VERSION ""

NS_ :

BS_:

BU_:BMS FCS VCU
BO_ 2550464563 BatP3_BMS_PackUsageLimit: 8 BMS
 SG_ P3_PackVltUprLmt : 7|14@0+ (0.1,0) [0|1200] "V" VCU
 SG_ P3_PackVltLoLmt : 9|14@0+ (0.1,0) [0|1200] "V" VCU
 SG_ P3_PackMaxDschrgCrnt : 27|14@0+ (0.1,0) [0|1600] "A" VCU
 SG_ P3_PackMaxChrgCrnt : 45|14@0+ (0.1,0) [0|1600] "A" VCU

BO_ 2550530099 BatP3_BMS_PackPowerCapability: 8 BMS
 SG_ P3_PackDschrgPwrLmt : 7|10@0+ (1,0) [0|1000] "kW" VCU
 SG_ P3_PackDschrgPwrStat : 13|2@0+ (1,0) [0|3] "" VCU
 SG_ P3_PackChrgPwrLmt : 11|10@0+ (1,0) [0|1000] "kW" VCU
 SG_ P3_PackChrgPwrStat : 17|2@0+ (1,0) [0|3] "" VCU

BO_ 2550595635 BatP3_BMS_ChargingInfo: 8 BMS
 SG_ P3_ChrgrCplrStat : 7|1@0+ (1,0) [0|1] "" VCU
 SG_ P3_HVBattChrgSysStatus : 6|4@0+ (1,0) [0|15] "" VCU
 SG_ P3_DCChrgCrntCmd : 2|9@0+ (1,0) [0|500] "A" VCU
 SG_ P3_CC2Vlt : 9|8@0+ (0.1,0) [0|25] "V" VCU
 SG_ P3_DCRcptPosTemp : 17|9@0+ (0.5,-40) [-40|150] "C" VCU
 SG_ P3_DCRcptNegTemp : 24|9@0+ (0.5,-40) [-40|150] "C" VCU
 SG_ P3_Tm2FullChrg : 47|14@0+ (1,0) [0|65535] "min" VCU

BO_ 2550661171 BatP3_BMS_ThermalManagement: 8 BMS
 SG_ P3_Inlet1ClntTemp : 7|11@0+ (0.1,-40) [-40|150] "C" VCU
 SG_ P3_Inlet2ClntTemp : 12|11@0+ (0.1,-40) [-40|150] "C" VCU
 SG_ P3_Outlet1ClntTemp : 17|11@0+ (0.1,-40) [-40|150] "C" VCU
 SG_ P3_Outlet2ClntTemp : 38|11@0+ (0.1,-40) [-40|150] "C" VCU
 SG_ P3_TrgtClntTemp : 43|11@0+ (0.1,-40) [-40|150] "C" VCU
 SG_ P3_TrgtClntFlowRate : 48|9@0+ (0.2,0) [0|100] "C" VCU

BO_ 2550726707 BatP3_BMS_CellVoltMaxMin: 8 BMS
 SG_ P3_MaxCellVlt : 7|13@0+ (0.001,0) [0|5] "V" VCU
 SG_ P3_MaxCellVltNum : 10|9@0+ (1,0) [0|500] "" VCU
 SG_ P3_MinCellVlt : 17|13@0+ (0.001,0) [0|5] "V" VCU
 SG_ P3_MinCellVltNum : 36|9@0+ (1,0) [0|500] "" VCU
 SG_ P3_AvgCellVlt : 43|13@0+ (0.001,0) [0|5] "V" VCU

BO_ 2550792243 BatP3_BMS_CellTempMaxMin: 8 BMS
 SG_ P3_MaxCellTemp : 7|11@0+ (0.1,-40) [-40|150] "C" VCU
 SG_ P3_MaxCellTempNum : 12|9@0+ (1,0) [0|500] "" VCU
 SG_ P3_MinCellTemp : 19|11@0+ (0.1,-40) [-40|150] "C" VCU
 SG_ P3_MinCellTempNum : 24|9@0+ (1,0) [0|500] "" VCU
 SG_ P3_AvgCellTemp : 47|11@0+ (0.1,-40) [-40|150] "C" VCU

BO_ 2550857779 BatP3_BMS_PackFaultInfo1: 8 BMS
 SG_ P3_PackTotFltNum : 7|8@0+ (1,0) [0|200] "" VCU
 SG_ P3_CellOverVoltage : 15|2@0+ (1,0) [0|3] "" VCU
 SG_ P3_CellUnderVoltage : 13|2@0+ (1,0) [0|3] "" VCU
 SG_ P3_CellVoltageDiffHi : 11|1@0+ (1,0) [0|1] "" VCU
 SG_ P3_PackOverVoltage : 10|2@0+ (1,0) [0|3] "" VCU
 SG_ P3_PackUnderVoltage : 8|2@0+ (1,0) [0|3] "" VCU
 SG_ P3_CellOverTemp : 22|2@0+ (1,0) [0|3] "" VCU
 SG_ P3_CellTempLow : 20|1@0+ (1,0) [0|1] "" VCU
 SG_ P3_CellTempDiffHi : 19|1@0+ (1,0) [0|1] "" VCU
 SG_ P3_PackDschrgCrntHi : 18|2@0+ (1,0) [0|3] "" VCU
 SG_ P3_PackChrgCrntHi : 16|2@0+ (1,0) [0|3] "" VCU
 SG_ P3_PackCrnSnsr1OffsetHi : 30|1@0+ (1,0) [0|1] "" VCU
 SG_ P3_HVIsolFlt : 29|2@0+ (1,0) [0|3] "" VCU
 SG_ P3_HVILFlt : 27|1@0+ (1,0) [0|1] "" VCU
 SG_ P3_ThrmlRunaway : 26|1@0+ (1,0) [0|1] "" VCU
 SG_ P3_CellVoltInvalid : 25|1@0+ (1,0) [0|1] "" VCU
 SG_ P3_CellTempInvalid : 24|1@0+ (1,0) [0|1] "" VCU
 SG_ P3_DaisyChainComFlt : 39|1@0+ (1,0) [0|1] "" VCU
 SG_ P3_PackVoltRatFlt : 38|1@0+ (1,0) [0|1] "" VCU
 SG_ P3_CrntSnsr1Invalid : 37|1@0+ (1,0) [0|1] "" VCU
 SG_ P3_CrntSnsr1OOR : 36|1@0+ (1,0) [0|1] "" VCU
 SG_ P3_CrntSnsr2Invalid : 35|1@0+ (1,0) [0|1] "" VCU
 SG_ P3_CrntSnsr2OOR : 34|1@0+ (1,0) [0|1] "" VCU
 SG_ P3_PackCrnSnsr2OffsetHi : 33|1@0+ (1,0) [0|1] "" VCU
 SG_ P3_OutofEnergy : 32|1@0+ (1,0) [0|1] "" VCU
 SG_ P3_IsolDetCircErr : 47|1@0+ (1,0) [0|1] "" VCU
 SG_ P3_HVILCircShortToGND : 46|1@0+ (1,0) [0|1] "" VCU
 SG_ P3_HVILCircShortToPwr : 45|1@0+ (1,0) [0|1] "" VCU

BO_ 2550923315 BatP3_BMS_PackFaultInfo2: 8 BMS
 SG_ P3_MainPosCntctrStkClsd : 7|1@0+ (1,0) [0|1] "" VCU
 SG_ P3_MainPosCntctrStkOpn : 6|1@0+ (1,0) [0|1] "" VCU
 SG_ P3_MainNegCntctr1StkClsd : 5|1@0+ (1,0) [0|1] "" VCU
 SG_ P3_MainNegCntctr1StkOpn : 4|1@0+ (1,0) [0|1] "" VCU
 SG_ P3_MainNegCntctr2StkClsd : 3|1@0+ (1,0) [0|1] "" VCU
 SG_ P3_MainNegCntctr2StkOpn : 2|1@0+ (1,0) [0|1] "" VCU
 SG_ P3_PrechargTmOut : 1|1@0+ (1,0) [0|1] "" VCU
 SG_ P3_PrechrgCrntHi : 0|1@0+ (1,0) [0|1] "" VCU
 SG_ P3_ChrgCplrPosTempHi : 15|1@0+ (1,0) [0|1] "" VCU
 SG_ P3_ChrgCplrNegTempHi : 14|1@0+ (1,0) [0|1] "" VCU
 SG_ P3_BMSPwrSuplVlt1Hi : 13|1@0+ (1,0) [0|1] "" VCU
 SG_ P3_BMSPwrSuplVlt1Lo : 12|1@0+ (1,0) [0|1] "" VCU
 SG_ P3_BMSPwrSuplVlt2Hi : 11|1@0+ (1,0) [0|1] "" VCU
 SG_ P3_BMSPwrSuplVlt2Lo : 10|1@0+ (1,0) [0|1] "" VCU
 SG_ P3_CntctrCirPwrSuplVltLo : 9|1@0+ (1,0) [0|1] "" VCU
 SG_ P3_CntctrCirPwrSuplVltHi : 8|1@0+ (1,0) [0|1] "" VCU
 SG_ P3_CAN1BusOff : 23|1@0+ (1,0) [0|1] "" VCU
 SG_ P3_CAN1BusTmOut : 22|1@0+ (1,0) [0|1] "" VCU
 SG_ P3_CAN2BusOff : 21|1@0+ (1,0) [0|1] "" VCU
 SG_ P3_CAN2BusTmOut : 20|1@0+ (1,0) [0|1] "" VCU
 SG_ P3_CellBalCircTempHi : 19|1@0+ (1,0) [0|1] "" VCU
 SG_ P3_ClntInTempHi : 18|1@0+ (1,0) [0|1] "" VCU
 SG_ P3_ClntOutTempHi : 17|1@0+ (1,0) [0|1] "" VCU
 SG_ P3_CellExtrmUdrVolt : 16|1@0+ (1,0) [0|1] "" VCU
 SG_ P3_CellExtrmOvrVolt : 31|1@0+ (1,0) [0|1] "" VCU
 SG_ P3_Branch1DischrgCrntHi  : 30|1@0+ (1,0) [0|1] "" VCU
 SG_ P3_Branch2DischrgCrntHi  : 29|1@0+ (1,0) [0|1] "" VCU
 SG_ P3_Branch1ChrgCrntHi  : 28|1@0+ (1,0) [0|1] "" VCU
 SG_ P3_Branch2ChrgCrntHi  : 27|1@0+ (1,0) [0|1] "" VCU
 SG_ P3_InitFailed : 26|1@0+ (1,0) [0|1] "" VCU
 SG_ P3_PackErrCode : 25|10@0+ (1,0) [0|1023] "" VCU

BO_ 2550988851 BatP3_BMS_PackConfigInfo: 8 BMS
 SG_ P3_PackTotCellNum : 7|9@0+ (1,0) [0|500] "" VCU
 SG_ P3_PackTotCellTempSnsrNum : 14|9@0+ (1,0) [0|500] "" VCU

BO_ 2552299571 BatP3_BMS_BMSVersion: 8 BMS
 SG_ P3_BMSASWMajVerNum : 7|8@0+ (1,0) [0|9] "" VCU
 SG_ P3_BMSASWMinVerNum : 15|8@0+ (1,0) [0|99] "" VCU
 SG_ P3_BMSASWPatchVerNum : 23|8@0+ (1,0) [0|255] "" VCU
 SG_ P3_BMSBSWMajVerNum : 31|8@0+ (1,0) [0|9] "" VCU
 SG_ P3_BMSBSWMinVerNum : 39|8@0+ (1,0) [0|99] "" VCU
 SG_ P3_BMSBSWPatchVerNum : 47|8@0+ (1,0) [0|255] "" VCU

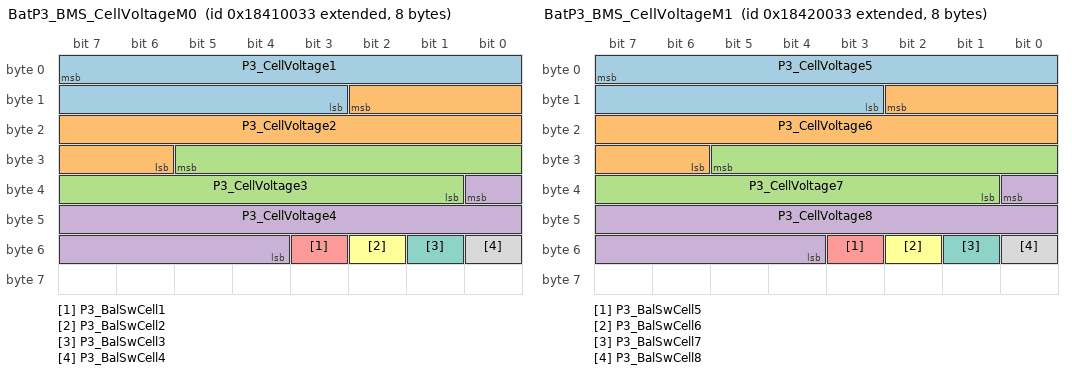
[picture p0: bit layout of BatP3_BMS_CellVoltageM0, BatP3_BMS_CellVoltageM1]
BO_ 2554396723 BatP3_BMS_CellVoltageM0: 8 BMS
 SG_ P3_CellVoltage1 : 7|13@0+ (0.001,0) [0|5] "V" VCU
 SG_ P3_CellVoltage2 : 10|13@0+ (0.001,0) [0|5] "V" VCU
 SG_ P3_CellVoltage3 : 29|13@0+ (0.001,0) [0|5] "V" VCU
 SG_ P3_CellVoltage4 : 32|13@0+ (0.001,0) [0|5] "V" VCU
 SG_ P3_BalSwCell1 : 51|1@0+ (1,0) [0|1] "" VCU
 SG_ P3_BalSwCell2 : 50|1@0+ (1,0) [0|1] "" VCU
 SG_ P3_BalSwCell3 : 49|1@0+ (1,0) [0|1] "" VCU
 SG_ P3_BalSwCell4 : 48|1@0+ (1,0) [0|1] "" VCU

BO_ 2554462259 BatP3_BMS_CellVoltageM1: 8 BMS
 SG_ P3_CellVoltage5 : 7|13@0+ (0.001,0) [0|5] "V" VCU
 SG_ P3_CellVoltage6 : 10|13@0+ (0.001,0) [0|5] "V" VCU
 SG_ P3_CellVoltage7 : 29|13@0+ (0.001,0) [0|5] "V" VCU
 SG_ P3_CellVoltage8 : 32|13@0+ (0.001,0) [0|5] "V" VCU
 SG_ P3_BalSwCell5 : 51|1@0+ (1,0) [0|1] "" VCU
 SG_ P3_BalSwCell6 : 50|1@0+ (1,0) [0|1] "" VCU
 SG_ P3_BalSwCell7 : 49|1@0+ (1,0) [0|1] "" VCU
 SG_ P3_BalSwCell8 : 48|1@0+ (1,0) [0|1] "" VCU

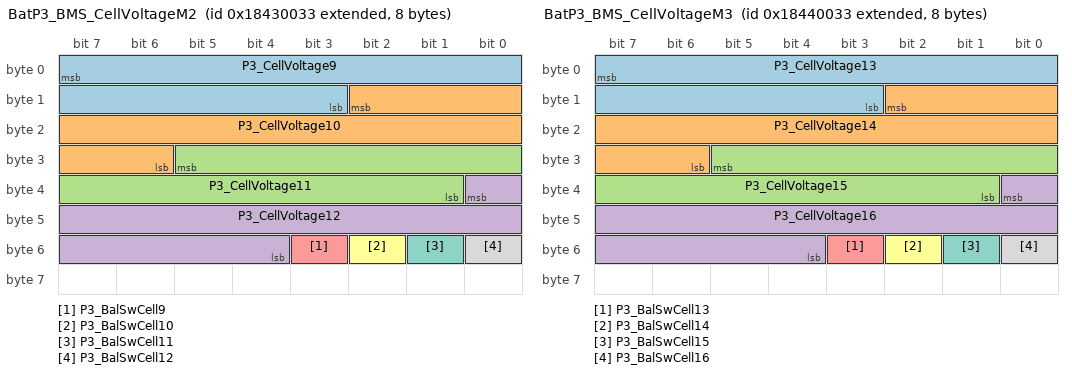
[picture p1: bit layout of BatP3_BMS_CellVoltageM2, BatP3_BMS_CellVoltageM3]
BO_ 2554527795 BatP3_BMS_CellVoltageM2: 8 BMS
 SG_ P3_CellVoltage9 : 7|13@0+ (0.001,0) [0|5] "V" VCU
 SG_ P3_CellVoltage10 : 10|13@0+ (0.001,0) [0|5] "V" VCU
 SG_ P3_CellVoltage11 : 29|13@0+ (0.001,0) [0|5] "V" VCU
 SG_ P3_CellVoltage12 : 32|13@0+ (0.001,0) [0|5] "V" VCU
 SG_ P3_BalSwCell9 : 51|1@0+ (1,0) [0|1] "" VCU
 SG_ P3_BalSwCell10 : 50|1@0+ (1,0) [0|1] "" VCU
 SG_ P3_BalSwCell11 : 49|1@0+ (1,0) [0|1] "" VCU
 SG_ P3_BalSwCell12 : 48|1@0+ (1,0) [0|1] "" VCU

BO_ 2554593331 BatP3_BMS_CellVoltageM3: 8 BMS
 SG_ P3_CellVoltage13 : 7|13@0+ (0.001,0) [0|5] "V" VCU
 SG_ P3_CellVoltage14 : 10|13@0+ (0.001,0) [0|5] "V" VCU
 SG_ P3_CellVoltage15 : 29|13@0+ (0.001,0) [0|5] "V" VCU
 SG_ P3_CellVoltage16 : 32|13@0+ (0.001,0) [0|5] "V" VCU
 SG_ P3_BalSwCell13 : 51|1@0+ (1,0) [0|1] "" VCU
 SG_ P3_BalSwCell14 : 50|1@0+ (1,0) [0|1] "" VCU
 SG_ P3_BalSwCell15 : 49|1@0+ (1,0) [0|1] "" VCU
 SG_ P3_BalSwCell16 : 48|1@0+ (1,0) [0|1] "" VCU

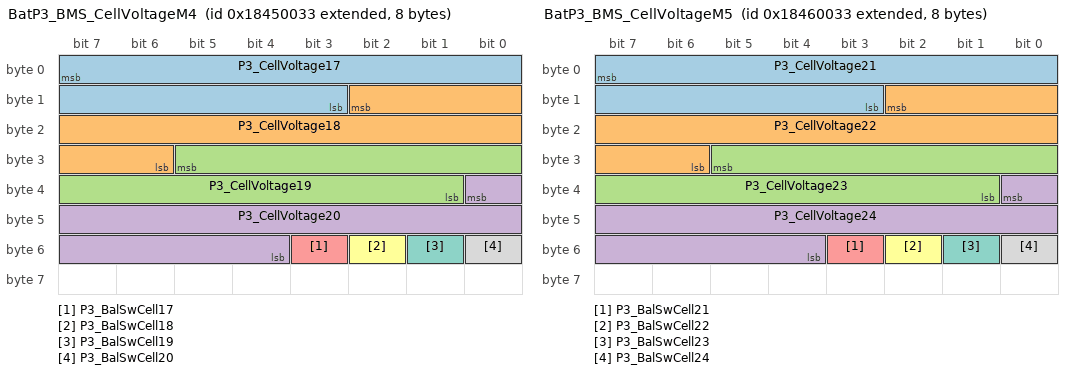
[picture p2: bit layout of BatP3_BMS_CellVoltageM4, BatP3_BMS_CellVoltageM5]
BO_ 2554658867 BatP3_BMS_CellVoltageM4: 8 BMS
 SG_ P3_CellVoltage17 : 7|13@0+ (0.001,0) [0|5] "V" VCU
 SG_ P3_CellVoltage18 : 10|13@0+ (0.001,0) [0|5] "V" VCU
 SG_ P3_CellVoltage19 : 29|13@0+ (0.001,0) [0|5] "V" VCU
 SG_ P3_CellVoltage20 : 32|13@0+ (0.001,0) [0|5] "V" VCU
 SG_ P3_BalSwCell17 : 51|1@0+ (1,0) [0|1] "" VCU
 SG_ P3_BalSwCell18 : 50|1@0+ (1,0) [0|1] "" VCU
 SG_ P3_BalSwCell19 : 49|1@0+ (1,0) [0|1] "" VCU
 SG_ P3_BalSwCell20 : 48|1@0+ (1,0) [0|1] "" VCU

BO_ 2554724403 BatP3_BMS_CellVoltageM5: 8 BMS
 SG_ P3_CellVoltage21 : 7|13@0+ (0.001,0) [0|5] "V" VCU
 SG_ P3_CellVoltage22 : 10|13@0+ (0.001,0) [0|5] "V" VCU
 SG_ P3_CellVoltage23 : 29|13@0+ (0.001,0) [0|5] "V" VCU
 SG_ P3_CellVoltage24 : 32|13@0+ (0.001,0) [0|5] "V" VCU
 SG_ P3_BalSwCell21 : 51|1@0+ (1,0) [0|1] "" VCU
 SG_ P3_BalSwCell22 : 50|1@0+ (1,0) [0|1] "" VCU
 SG_ P3_BalSwCell23 : 49|1@0+ (1,0) [0|1] "" VCU
 SG_ P3_BalSwCell24 : 48|1@0+ (1,0) [0|1] "" VCU

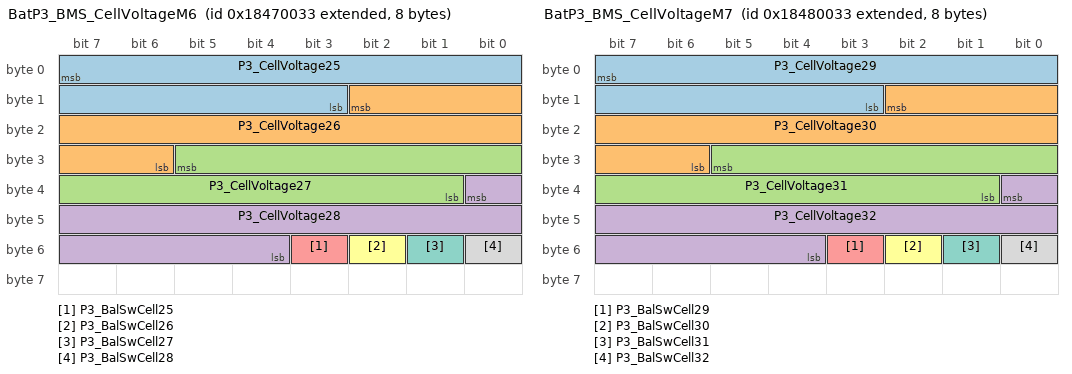
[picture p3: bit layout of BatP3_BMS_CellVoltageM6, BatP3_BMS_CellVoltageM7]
BO_ 2554789939 BatP3_BMS_CellVoltageM6: 8 BMS
 SG_ P3_CellVoltage25 : 7|13@0+ (0.001,0) [0|5] "V" VCU
 SG_ P3_CellVoltage26 : 10|13@0+ (0.001,0) [0|5] "V" VCU
 SG_ P3_CellVoltage27 : 29|13@0+ (0.001,0) [0|5] "V" VCU
 SG_ P3_CellVoltage28 : 32|13@0+ (0.001,0) [0|5] "V" VCU
 SG_ P3_BalSwCell25 : 51|1@0+ (1,0) [0|1] "" VCU
 SG_ P3_BalSwCell26 : 50|1@0+ (1,0) [0|1] "" VCU
 SG_ P3_BalSwCell27 : 49|1@0+ (1,0) [0|1] "" VCU
 SG_ P3_BalSwCell28 : 48|1@0+ (1,0) [0|1] "" VCU

BO_ 2554855475 BatP3_BMS_CellVoltageM7: 8 BMS
 SG_ P3_CellVoltage29 : 7|13@0+ (0.001,0) [0|5] "V" VCU
 SG_ P3_CellVoltage30 : 10|13@0+ (0.001,0) [0|5] "V" VCU
 SG_ P3_CellVoltage31 : 29|13@0+ (0.001,0) [0|5] "V" VCU
 SG_ P3_CellVoltage32 : 32|13@0+ (0.001,0) [0|5] "V" VCU
 SG_ P3_BalSwCell29 : 51|1@0+ (1,0) [0|1] "" VCU
 SG_ P3_BalSwCell30 : 50|1@0+ (1,0) [0|1] "" VCU
 SG_ P3_BalSwCell31 : 49|1@0+ (1,0) [0|1] "" VCU
 SG_ P3_BalSwCell32 : 48|1@0+ (1,0) [0|1] "" VCU

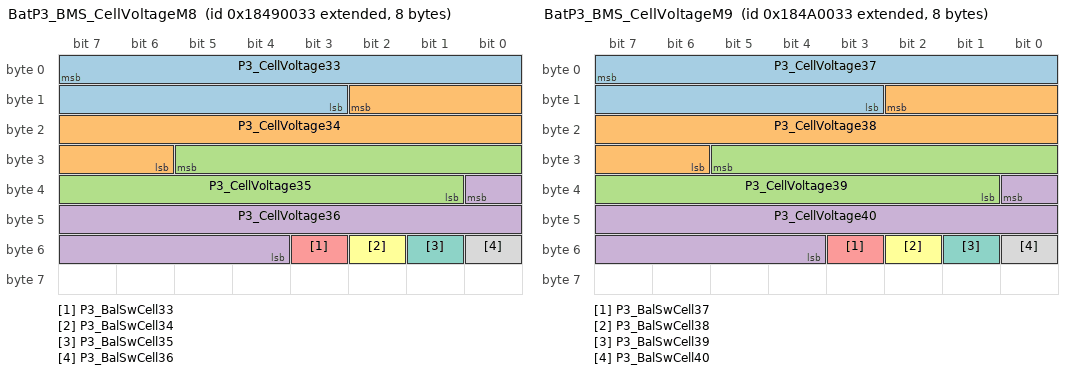
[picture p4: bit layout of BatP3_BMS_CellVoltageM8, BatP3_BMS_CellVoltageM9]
BO_ 2554921011 BatP3_BMS_CellVoltageM8: 8 BMS
 SG_ P3_CellVoltage33 : 7|13@0+ (0.001,0) [0|5] "V" VCU
 SG_ P3_CellVoltage34 : 10|13@0+ (0.001,0) [0|5] "V" VCU
 SG_ P3_CellVoltage35 : 29|13@0+ (0.001,0) [0|5] "V" VCU
 SG_ P3_CellVoltage36 : 32|13@0+ (0.001,0) [0|5] "V" VCU
 SG_ P3_BalSwCell33 : 51|1@0+ (1,0) [0|1] "" VCU
 SG_ P3_BalSwCell34 : 50|1@0+ (1,0) [0|1] "" VCU
 SG_ P3_BalSwCell35 : 49|1@0+ (1,0) [0|1] "" VCU
 SG_ P3_BalSwCell36 : 48|1@0+ (1,0) [0|1] "" VCU

BO_ 2554986547 BatP3_BMS_CellVoltageM9: 8 BMS
 SG_ P3_CellVoltage37 : 7|13@0+ (0.001,0) [0|5] "V" VCU
 SG_ P3_CellVoltage38 : 10|13@0+ (0.001,0) [0|5] "V" VCU
 SG_ P3_CellVoltage39 : 29|13@0+ (0.001,0) [0|5] "V" VCU
 SG_ P3_CellVoltage40 : 32|13@0+ (0.001,0) [0|5] "V" VCU
 SG_ P3_BalSwCell37 : 51|1@0+ (1,0) [0|1] "" VCU
 SG_ P3_BalSwCell38 : 50|1@0+ (1,0) [0|1] "" VCU
 SG_ P3_BalSwCell39 : 49|1@0+ (1,0) [0|1] "" VCU
 SG_ P3_BalSwCell40 : 48|1@0+ (1,0) [0|1] "" VCU

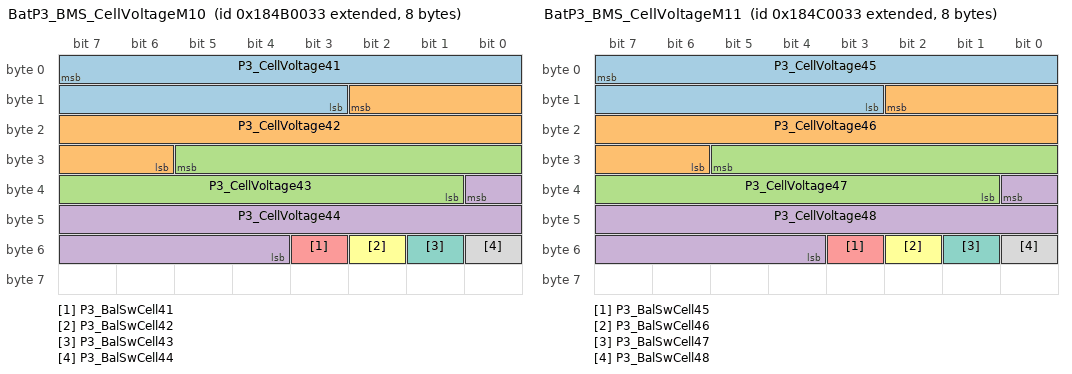
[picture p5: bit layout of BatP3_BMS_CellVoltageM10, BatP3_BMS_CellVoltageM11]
BO_ 2555052083 BatP3_BMS_CellVoltageM10: 8 BMS
 SG_ P3_CellVoltage41 : 7|13@0+ (0.001,0) [0|5] "V" VCU
 SG_ P3_CellVoltage42 : 10|13@0+ (0.001,0) [0|5] "V" VCU
 SG_ P3_CellVoltage43 : 29|13@0+ (0.001,0) [0|5] "V" VCU
 SG_ P3_CellVoltage44 : 32|13@0+ (0.001,0) [0|5] "V" VCU
 SG_ P3_BalSwCell41 : 51|1@0+ (1,0) [0|1] "" VCU
 SG_ P3_BalSwCell42 : 50|1@0+ (1,0) [0|1] "" VCU
 SG_ P3_BalSwCell43 : 49|1@0+ (1,0) [0|1] "" VCU
 SG_ P3_BalSwCell44 : 48|1@0+ (1,0) [0|1] "" VCU

BO_ 2555117619 BatP3_BMS_CellVoltageM11: 8 BMS
 SG_ P3_CellVoltage45 : 7|13@0+ (0.001,0) [0|5] "V" VCU
 SG_ P3_CellVoltage46 : 10|13@0+ (0.001,0) [0|5] "V" VCU
 SG_ P3_CellVoltage47 : 29|13@0+ (0.001,0) [0|5] "V" VCU
 SG_ P3_CellVoltage48 : 32|13@0+ (0.001,0) [0|5] "V" VCU
 SG_ P3_BalSwCell45 : 51|1@0+ (1,0) [0|1] "" VCU
 SG_ P3_BalSwCell46 : 50|1@0+ (1,0) [0|1] "" VCU
 SG_ P3_BalSwCell47 : 49|1@0+ (1,0) [0|1] "" VCU
 SG_ P3_BalSwCell48 : 48|1@0+ (1,0) [0|1] "" VCU

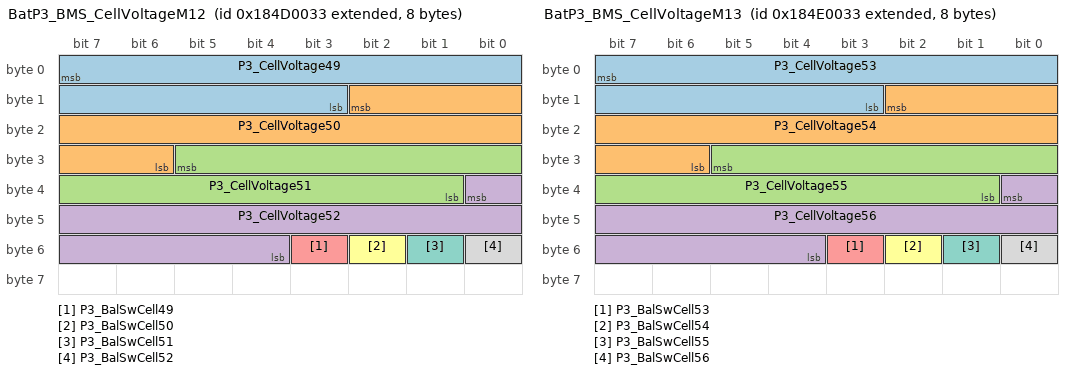
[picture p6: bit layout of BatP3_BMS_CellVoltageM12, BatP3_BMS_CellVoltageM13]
BO_ 2555183155 BatP3_BMS_CellVoltageM12: 8 BMS
 SG_ P3_CellVoltage49 : 7|13@0+ (0.001,0) [0|5] "V" VCU
 SG_ P3_CellVoltage50 : 10|13@0+ (0.001,0) [0|5] "V" VCU
 SG_ P3_CellVoltage51 : 29|13@0+ (0.001,0) [0|5] "V" VCU
 SG_ P3_CellVoltage52 : 32|13@0+ (0.001,0) [0|5] "V" VCU
 SG_ P3_BalSwCell49 : 51|1@0+ (1,0) [0|1] "" VCU
 SG_ P3_BalSwCell50 : 50|1@0+ (1,0) [0|1] "" VCU
 SG_ P3_BalSwCell51 : 49|1@0+ (1,0) [0|1] "" VCU
 SG_ P3_BalSwCell52 : 48|1@0+ (1,0) [0|1] "" VCU

BO_ 2555248691 BatP3_BMS_CellVoltageM13: 8 BMS
 SG_ P3_CellVoltage53 : 7|13@0+ (0.001,0) [0|5] "V" VCU
 SG_ P3_CellVoltage54 : 10|13@0+ (0.001,0) [0|5] "V" VCU
 SG_ P3_CellVoltage55 : 29|13@0+ (0.001,0) [0|5] "V" VCU
 SG_ P3_CellVoltage56 : 32|13@0+ (0.001,0) [0|5] "V" VCU
 SG_ P3_BalSwCell53 : 51|1@0+ (1,0) [0|1] "" VCU
 SG_ P3_BalSwCell54 : 50|1@0+ (1,0) [0|1] "" VCU
 SG_ P3_BalSwCell55 : 49|1@0+ (1,0) [0|1] "" VCU
 SG_ P3_BalSwCell56 : 48|1@0+ (1,0) [0|1] "" VCU

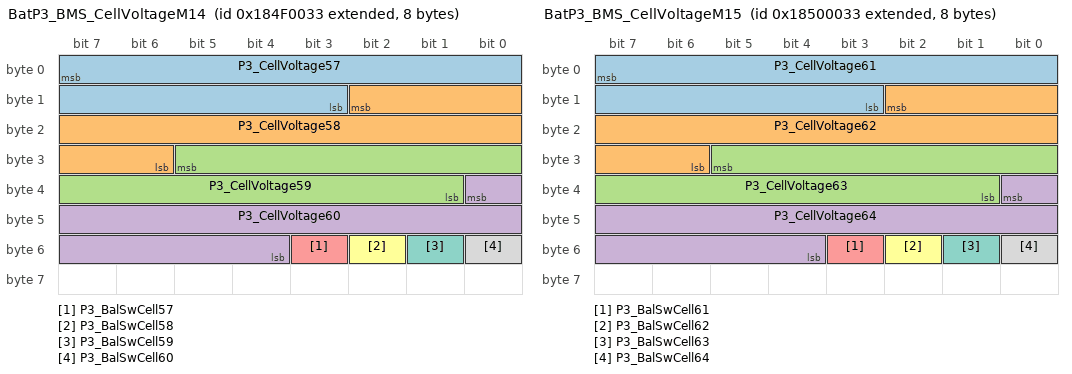
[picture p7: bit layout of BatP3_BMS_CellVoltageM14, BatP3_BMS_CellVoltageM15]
BO_ 2555314227 BatP3_BMS_CellVoltageM14: 8 BMS
 SG_ P3_CellVoltage57 : 7|13@0+ (0.001,0) [0|5] "V" VCU
 SG_ P3_CellVoltage58 : 10|13@0+ (0.001,0) [0|5] "V" VCU
 SG_ P3_CellVoltage59 : 29|13@0+ (0.001,0) [0|5] "V" VCU
 SG_ P3_CellVoltage60 : 32|13@0+ (0.001,0) [0|5] "V" VCU
 SG_ P3_BalSwCell57 : 51|1@0+ (1,0) [0|1] "" VCU
 SG_ P3_BalSwCell58 : 50|1@0+ (1,0) [0|1] "" VCU
 SG_ P3_BalSwCell59 : 49|1@0+ (1,0) [0|1] "" VCU
 SG_ P3_BalSwCell60 : 48|1@0+ (1,0) [0|1] "" VCU

BO_ 2555379763 BatP3_BMS_CellVoltageM15: 8 BMS
 SG_ P3_CellVoltage61 : 7|13@0+ (0.001,0) [0|5] "V" VCU
 SG_ P3_CellVoltage62 : 10|13@0+ (0.001,0) [0|5] "V" VCU
 SG_ P3_CellVoltage63 : 29|13@0+ (0.001,0) [0|5] "V" VCU
 SG_ P3_CellVoltage64 : 32|13@0+ (0.001,0) [0|5] "V" VCU
 SG_ P3_BalSwCell61 : 51|1@0+ (1,0) [0|1] "" VCU
 SG_ P3_BalSwCell62 : 50|1@0+ (1,0) [0|1] "" VCU
 SG_ P3_BalSwCell63 : 49|1@0+ (1,0) [0|1] "" VCU
 SG_ P3_BalSwCell64 : 48|1@0+ (1,0) [0|1] "" VCU

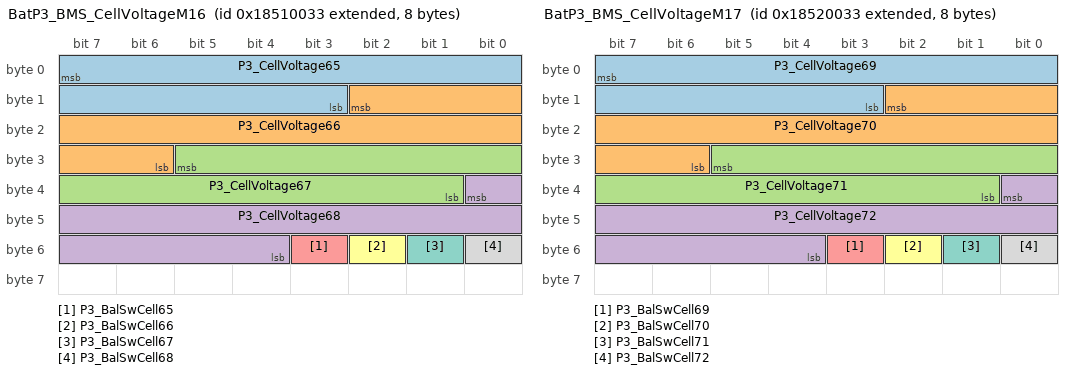
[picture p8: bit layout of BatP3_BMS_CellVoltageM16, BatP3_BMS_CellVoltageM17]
BO_ 2555445299 BatP3_BMS_CellVoltageM16: 8 BMS
 SG_ P3_CellVoltage65 : 7|13@0+ (0.001,0) [0|5] "V" VCU
 SG_ P3_CellVoltage66 : 10|13@0+ (0.001,0) [0|5] "V" VCU
 SG_ P3_CellVoltage67 : 29|13@0+ (0.001,0) [0|5] "V" VCU
 SG_ P3_CellVoltage68 : 32|13@0+ (0.001,0) [0|5] "V" VCU
 SG_ P3_BalSwCell65 : 51|1@0+ (1,0) [0|1] "" VCU
 SG_ P3_BalSwCell66 : 50|1@0+ (1,0) [0|1] "" VCU
 SG_ P3_BalSwCell67 : 49|1@0+ (1,0) [0|1] "" VCU
 SG_ P3_BalSwCell68 : 48|1@0+ (1,0) [0|1] "" VCU

BO_ 2555510835 BatP3_BMS_CellVoltageM17: 8 BMS
 SG_ P3_CellVoltage69 : 7|13@0+ (0.001,0) [0|5] "V" VCU
 SG_ P3_CellVoltage70 : 10|13@0+ (0.001,0) [0|5] "V" VCU
 SG_ P3_CellVoltage71 : 29|13@0+ (0.001,0) [0|5] "V" VCU
 SG_ P3_CellVoltage72 : 32|13@0+ (0.001,0) [0|5] "V" VCU
 SG_ P3_BalSwCell69 : 51|1@0+ (1,0) [0|1] "" VCU
 SG_ P3_BalSwCell70 : 50|1@0+ (1,0) [0|1] "" VCU
 SG_ P3_BalSwCell71 : 49|1@0+ (1,0) [0|1] "" VCU
 SG_ P3_BalSwCell72 : 48|1@0+ (1,0) [0|1] "" VCU

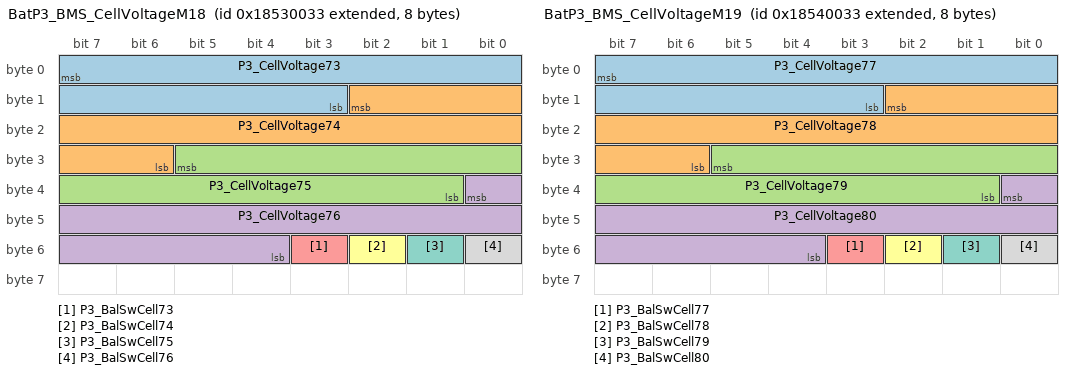
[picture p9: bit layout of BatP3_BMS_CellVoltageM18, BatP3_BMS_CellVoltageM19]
BO_ 2555576371 BatP3_BMS_CellVoltageM18: 8 BMS
 SG_ P3_CellVoltage73 : 7|13@0+ (0.001,0) [0|5] "V" VCU
 SG_ P3_CellVoltage74 : 10|13@0+ (0.001,0) [0|5] "V" VCU
 SG_ P3_CellVoltage75 : 29|13@0+ (0.001,0) [0|5] "V" VCU
 SG_ P3_CellVoltage76 : 32|13@0+ (0.001,0) [0|5] "V" VCU
 SG_ P3_BalSwCell73 : 51|1@0+ (1,0) [0|1] "" VCU
 SG_ P3_BalSwCell74 : 50|1@0+ (1,0) [0|1] "" VCU
 SG_ P3_BalSwCell75 : 49|1@0+ (1,0) [0|1] "" VCU
 SG_ P3_BalSwCell76 : 48|1@0+ (1,0) [0|1] "" VCU

BO_ 2555641907 BatP3_BMS_CellVoltageM19: 8 BMS
 SG_ P3_CellVoltage77 : 7|13@0+ (0.001,0) [0|5] "V" VCU
 SG_ P3_CellVoltage78 : 10|13@0+ (0.001,0) [0|5] "V" VCU
 SG_ P3_CellVoltage79 : 29|13@0+ (0.001,0) [0|5] "V" VCU
 SG_ P3_CellVoltage80 : 32|13@0+ (0.001,0) [0|5] "V" VCU
 SG_ P3_BalSwCell77 : 51|1@0+ (1,0) [0|1] "" VCU
 SG_ P3_BalSwCell78 : 50|1@0+ (1,0) [0|1] "" VCU
 SG_ P3_BalSwCell79 : 49|1@0+ (1,0) [0|1] "" VCU
 SG_ P3_BalSwCell80 : 48|1@0+ (1,0) [0|1] "" VCU

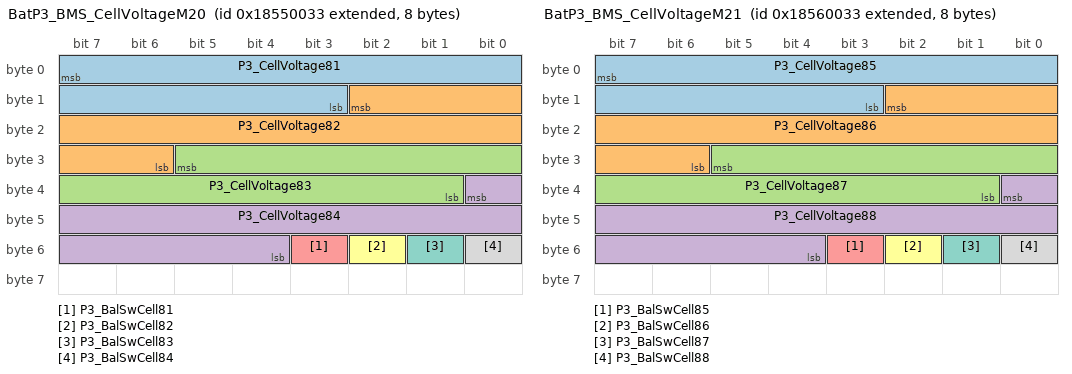
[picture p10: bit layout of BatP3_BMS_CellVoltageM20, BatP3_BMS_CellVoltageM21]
BO_ 2555707443 BatP3_BMS_CellVoltageM20: 8 BMS
 SG_ P3_CellVoltage81 : 7|13@0+ (0.001,0) [0|5] "V" VCU
 SG_ P3_CellVoltage82 : 10|13@0+ (0.001,0) [0|5] "V" VCU
 SG_ P3_CellVoltage83 : 29|13@0+ (0.001,0) [0|5] "V" VCU
 SG_ P3_CellVoltage84 : 32|13@0+ (0.001,0) [0|5] "V" VCU
 SG_ P3_BalSwCell81 : 51|1@0+ (1,0) [0|1] "" VCU
 SG_ P3_BalSwCell82 : 50|1@0+ (1,0) [0|1] "" VCU
 SG_ P3_BalSwCell83 : 49|1@0+ (1,0) [0|1] "" VCU
 SG_ P3_BalSwCell84 : 48|1@0+ (1,0) [0|1] "" VCU

BO_ 2555772979 BatP3_BMS_CellVoltageM21: 8 BMS
 SG_ P3_CellVoltage85 : 7|13@0+ (0.001,0) [0|5] "V" VCU
 SG_ P3_CellVoltage86 : 10|13@0+ (0.001,0) [0|5] "V" VCU
 SG_ P3_CellVoltage87 : 29|13@0+ (0.001,0) [0|5] "V" VCU
 SG_ P3_CellVoltage88 : 32|13@0+ (0.001,0) [0|5] "V" VCU
 SG_ P3_BalSwCell85 : 51|1@0+ (1,0) [0|1] "" VCU
 SG_ P3_BalSwCell86 : 50|1@0+ (1,0) [0|1] "" VCU
 SG_ P3_BalSwCell87 : 49|1@0+ (1,0) [0|1] "" VCU
 SG_ P3_BalSwCell88 : 48|1@0+ (1,0) [0|1] "" VCU

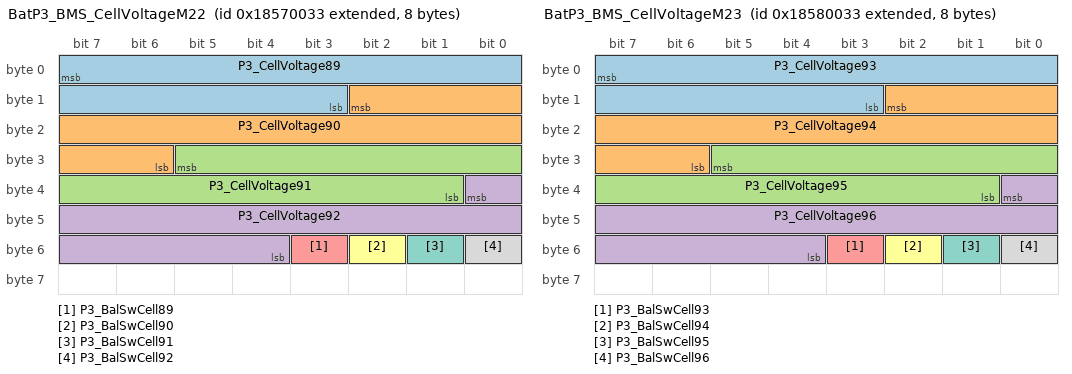
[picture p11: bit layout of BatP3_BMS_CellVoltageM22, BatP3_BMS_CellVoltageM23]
BO_ 2555838515 BatP3_BMS_CellVoltageM22: 8 BMS
 SG_ P3_CellVoltage89 : 7|13@0+ (0.001,0) [0|5] "V" VCU
 SG_ P3_CellVoltage90 : 10|13@0+ (0.001,0) [0|5] "V" VCU
 SG_ P3_CellVoltage91 : 29|13@0+ (0.001,0) [0|5] "V" VCU
 SG_ P3_CellVoltage92 : 32|13@0+ (0.001,0) [0|5] "V" VCU
 SG_ P3_BalSwCell89 : 51|1@0+ (1,0) [0|1] "" VCU
 SG_ P3_BalSwCell90 : 50|1@0+ (1,0) [0|1] "" VCU
 SG_ P3_BalSwCell91 : 49|1@0+ (1,0) [0|1] "" VCU
 SG_ P3_BalSwCell92 : 48|1@0+ (1,0) [0|1] "" VCU

BO_ 2555904051 BatP3_BMS_CellVoltageM23: 8 BMS
 SG_ P3_CellVoltage93 : 7|13@0+ (0.001,0) [0|5] "V" VCU
 SG_ P3_CellVoltage94 : 10|13@0+ (0.001,0) [0|5] "V" VCU
 SG_ P3_CellVoltage95 : 29|13@0+ (0.001,0) [0|5] "V" VCU
 SG_ P3_CellVoltage96 : 32|13@0+ (0.001,0) [0|5] "V" VCU
 SG_ P3_BalSwCell93 : 51|1@0+ (1,0) [0|1] "" VCU
 SG_ P3_BalSwCell94 : 50|1@0+ (1,0) [0|1] "" VCU
 SG_ P3_BalSwCell95 : 49|1@0+ (1,0) [0|1] "" VCU
 SG_ P3_BalSwCell96 : 48|1@0+ (1,0) [0|1] "" VCU

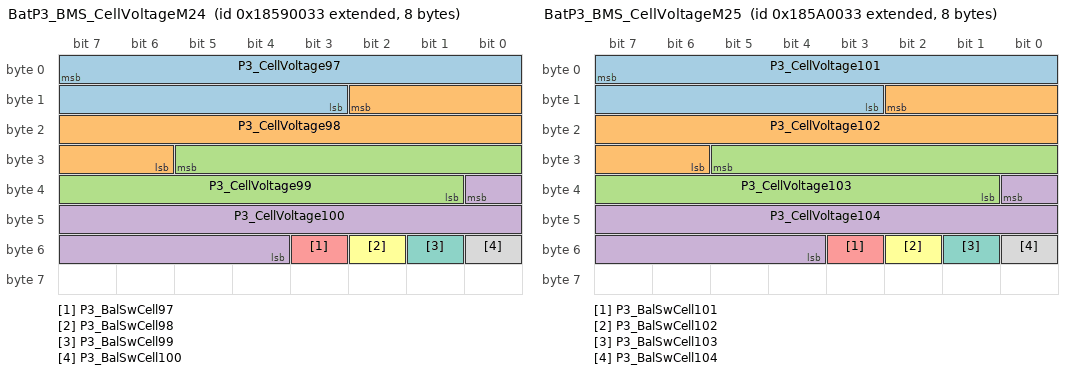
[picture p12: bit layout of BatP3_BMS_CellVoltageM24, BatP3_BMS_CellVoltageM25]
BO_ 2555969587 BatP3_BMS_CellVoltageM24: 8 BMS
 SG_ P3_CellVoltage97 : 7|13@0+ (0.001,0) [0|5] "V" VCU
 SG_ P3_CellVoltage98 : 10|13@0+ (0.001,0) [0|5] "V" VCU
 SG_ P3_CellVoltage99 : 29|13@0+ (0.001,0) [0|5] "V" VCU
 SG_ P3_CellVoltage100 : 32|13@0+ (0.001,0) [0|5] "V" VCU
 SG_ P3_BalSwCell97 : 51|1@0+ (1,0) [0|1] "" VCU
 SG_ P3_BalSwCell98 : 50|1@0+ (1,0) [0|1] "" VCU
 SG_ P3_BalSwCell99 : 49|1@0+ (1,0) [0|1] "" VCU
 SG_ P3_BalSwCell100 : 48|1@0+ (1,0) [0|1] "" VCU

BO_ 2556035123 BatP3_BMS_CellVoltageM25: 8 BMS
 SG_ P3_CellVoltage101 : 7|13@0+ (0.001,0) [0|5] "V" VCU
 SG_ P3_CellVoltage102 : 10|13@0+ (0.001,0) [0|5] "V" VCU
 SG_ P3_CellVoltage103 : 29|13@0+ (0.001,0) [0|5] "V" VCU
 SG_ P3_CellVoltage104 : 32|13@0+ (0.001,0) [0|5] "V" VCU
 SG_ P3_BalSwCell101 : 51|1@0+ (1,0) [0|1] "" VCU
 SG_ P3_BalSwCell102 : 50|1@0+ (1,0) [0|1] "" VCU
 SG_ P3_BalSwCell103 : 49|1@0+ (1,0) [0|1] "" VCU
 SG_ P3_BalSwCell104 : 48|1@0+ (1,0) [0|1] "" VCU

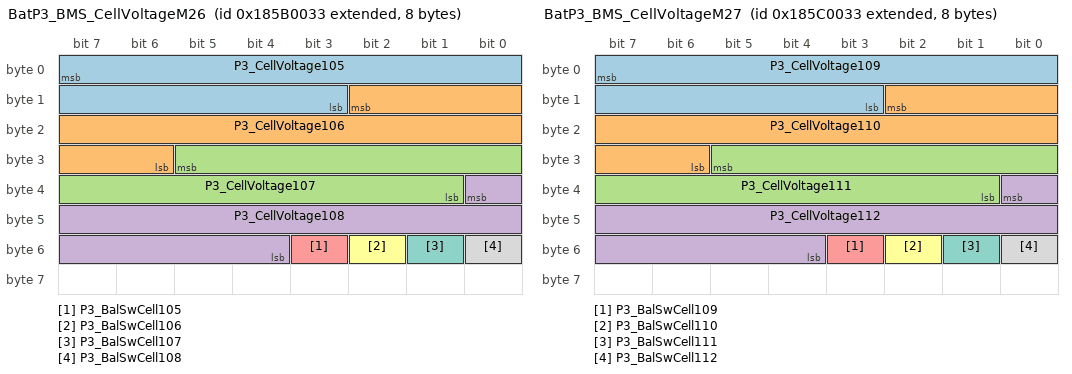
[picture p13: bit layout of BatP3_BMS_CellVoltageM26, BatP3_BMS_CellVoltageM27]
BO_ 2556100659 BatP3_BMS_CellVoltageM26: 8 BMS
 SG_ P3_CellVoltage105 : 7|13@0+ (0.001,0) [0|5] "V" VCU
 SG_ P3_CellVoltage106 : 10|13@0+ (0.001,0) [0|5] "V" VCU
 SG_ P3_CellVoltage107 : 29|13@0+ (0.001,0) [0|5] "V" VCU
 SG_ P3_CellVoltage108 : 32|13@0+ (0.001,0) [0|5] "V" VCU
 SG_ P3_BalSwCell105 : 51|1@0+ (1,0) [0|1] "" VCU
 SG_ P3_BalSwCell106 : 50|1@0+ (1,0) [0|1] "" VCU
 SG_ P3_BalSwCell107 : 49|1@0+ (1,0) [0|1] "" VCU
 SG_ P3_BalSwCell108 : 48|1@0+ (1,0) [0|1] "" VCU

BO_ 2556166195 BatP3_BMS_CellVoltageM27: 8 BMS
 SG_ P3_CellVoltage109 : 7|13@0+ (0.001,0) [0|5] "V" VCU
 SG_ P3_CellVoltage110 : 10|13@0+ (0.001,0) [0|5] "V" VCU
 SG_ P3_CellVoltage111 : 29|13@0+ (0.001,0) [0|5] "V" VCU
 SG_ P3_CellVoltage112 : 32|13@0+ (0.001,0) [0|5] "V" VCU
 SG_ P3_BalSwCell109 : 51|1@0+ (1,0) [0|1] "" VCU
 SG_ P3_BalSwCell110 : 50|1@0+ (1,0) [0|1] "" VCU
 SG_ P3_BalSwCell111 : 49|1@0+ (1,0) [0|1] "" VCU
 SG_ P3_BalSwCell112 : 48|1@0+ (1,0) [0|1] "" VCU

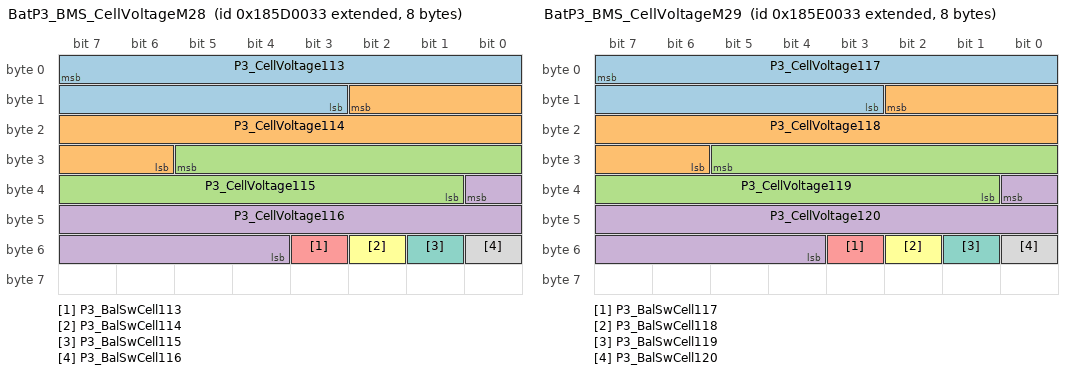
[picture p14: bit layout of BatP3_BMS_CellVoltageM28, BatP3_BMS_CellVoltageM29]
BO_ 2556231731 BatP3_BMS_CellVoltageM28: 8 BMS
 SG_ P3_CellVoltage113 : 7|13@0+ (0.001,0) [0|5] "V" VCU
 SG_ P3_CellVoltage114 : 10|13@0+ (0.001,0) [0|5] "V" VCU
 SG_ P3_CellVoltage115 : 29|13@0+ (0.001,0) [0|5] "V" VCU
 SG_ P3_CellVoltage116 : 32|13@0+ (0.001,0) [0|5] "V" VCU
 SG_ P3_BalSwCell113 : 51|1@0+ (1,0) [0|1] "" VCU
 SG_ P3_BalSwCell114 : 50|1@0+ (1,0) [0|1] "" VCU
 SG_ P3_BalSwCell115 : 49|1@0+ (1,0) [0|1] "" VCU
 SG_ P3_BalSwCell116 : 48|1@0+ (1,0) [0|1] "" VCU

BO_ 2556297267 BatP3_BMS_CellVoltageM29: 8 BMS
 SG_ P3_CellVoltage117 : 7|13@0+ (0.001,0) [0|5] "V" VCU
 SG_ P3_CellVoltage118 : 10|13@0+ (0.001,0) [0|5] "V" VCU
 SG_ P3_CellVoltage119 : 29|13@0+ (0.001,0) [0|5] "V" VCU
 SG_ P3_CellVoltage120 : 32|13@0+ (0.001,0) [0|5] "V" VCU
 SG_ P3_BalSwCell117 : 51|1@0+ (1,0) [0|1] "" VCU
 SG_ P3_BalSwCell118 : 50|1@0+ (1,0) [0|1] "" VCU
 SG_ P3_BalSwCell119 : 49|1@0+ (1,0) [0|1] "" VCU
 SG_ P3_BalSwCell120 : 48|1@0+ (1,0) [0|1] "" VCU

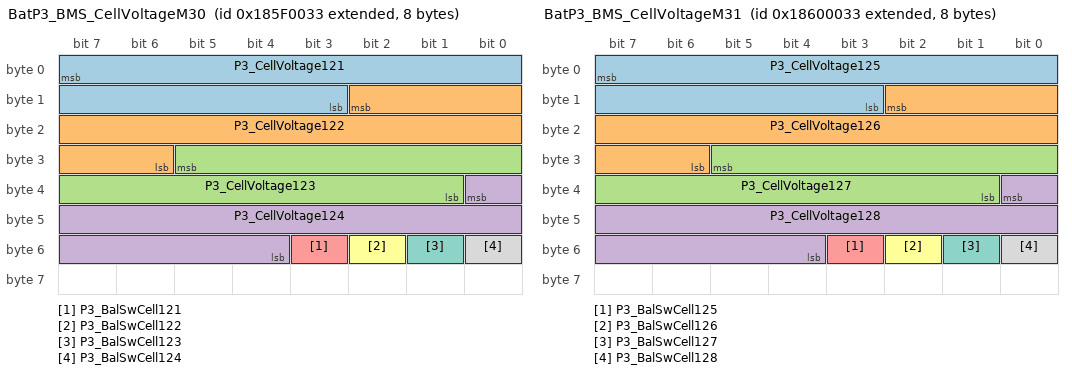
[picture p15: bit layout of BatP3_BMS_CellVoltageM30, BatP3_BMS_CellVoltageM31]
BO_ 2556362803 BatP3_BMS_CellVoltageM30: 8 BMS
 SG_ P3_CellVoltage121 : 7|13@0+ (0.001,0) [0|5] "V" VCU
 SG_ P3_CellVoltage122 : 10|13@0+ (0.001,0) [0|5] "V" VCU
 SG_ P3_CellVoltage123 : 29|13@0+ (0.001,0) [0|5] "V" VCU
 SG_ P3_CellVoltage124 : 32|13@0+ (0.001,0) [0|5] "V" VCU
 SG_ P3_BalSwCell121 : 51|1@0+ (1,0) [0|1] "" VCU
 SG_ P3_BalSwCell122 : 50|1@0+ (1,0) [0|1] "" VCU
 SG_ P3_BalSwCell123 : 49|1@0+ (1,0) [0|1] "" VCU
 SG_ P3_BalSwCell124 : 48|1@0+ (1,0) [0|1] "" VCU

BO_ 2556428339 BatP3_BMS_CellVoltageM31: 8 BMS
 SG_ P3_CellVoltage125 : 7|13@0+ (0.001,0) [0|5] "V" VCU
 SG_ P3_CellVoltage126 : 10|13@0+ (0.001,0) [0|5] "V" VCU
 SG_ P3_CellVoltage127 : 29|13@0+ (0.001,0) [0|5] "V" VCU
 SG_ P3_CellVoltage128 : 32|13@0+ (0.001,0) [0|5] "V" VCU
 SG_ P3_BalSwCell125 : 51|1@0+ (1,0) [0|1] "" VCU
 SG_ P3_BalSwCell126 : 50|1@0+ (1,0) [0|1] "" VCU
 SG_ P3_BalSwCell127 : 49|1@0+ (1,0) [0|1] "" VCU
 SG_ P3_BalSwCell128 : 48|1@0+ (1,0) [0|1] "" VCU

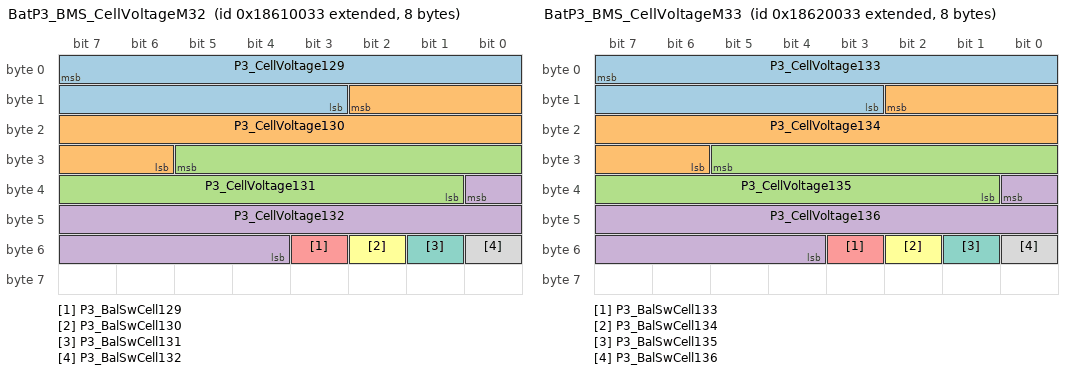
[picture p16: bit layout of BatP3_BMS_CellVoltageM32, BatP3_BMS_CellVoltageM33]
BO_ 2556493875 BatP3_BMS_CellVoltageM32: 8 BMS
 SG_ P3_CellVoltage129 : 7|13@0+ (0.001,0) [0|5] "V" VCU
 SG_ P3_CellVoltage130 : 10|13@0+ (0.001,0) [0|5] "V" VCU
 SG_ P3_CellVoltage131 : 29|13@0+ (0.001,0) [0|5] "V" VCU
 SG_ P3_CellVoltage132 : 32|13@0+ (0.001,0) [0|5] "V" VCU
 SG_ P3_BalSwCell129 : 51|1@0+ (1,0) [0|1] "" VCU
 SG_ P3_BalSwCell130 : 50|1@0+ (1,0) [0|1] "" VCU
 SG_ P3_BalSwCell131 : 49|1@0+ (1,0) [0|1] "" VCU
 SG_ P3_BalSwCell132 : 48|1@0+ (1,0) [0|1] "" VCU

BO_ 2556559411 BatP3_BMS_CellVoltageM33: 8 BMS
 SG_ P3_CellVoltage133 : 7|13@0+ (0.001,0) [0|5] "V" VCU
 SG_ P3_CellVoltage134 : 10|13@0+ (0.001,0) [0|5] "V" VCU
 SG_ P3_CellVoltage135 : 29|13@0+ (0.001,0) [0|5] "V" VCU
 SG_ P3_CellVoltage136 : 32|13@0+ (0.001,0) [0|5] "V" VCU
 SG_ P3_BalSwCell133 : 51|1@0+ (1,0) [0|1] "" VCU
 SG_ P3_BalSwCell134 : 50|1@0+ (1,0) [0|1] "" VCU
 SG_ P3_BalSwCell135 : 49|1@0+ (1,0) [0|1] "" VCU
 SG_ P3_BalSwCell136 : 48|1@0+ (1,0) [0|1] "" VCU

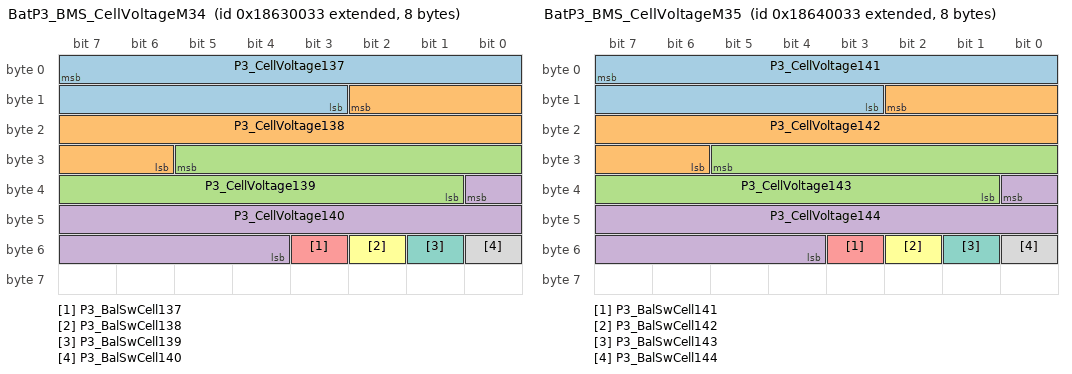
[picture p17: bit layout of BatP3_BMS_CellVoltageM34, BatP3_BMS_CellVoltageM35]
BO_ 2556624947 BatP3_BMS_CellVoltageM34: 8 BMS
 SG_ P3_CellVoltage137 : 7|13@0+ (0.001,0) [0|5] "V" VCU
 SG_ P3_CellVoltage138 : 10|13@0+ (0.001,0) [0|5] "V" VCU
 SG_ P3_CellVoltage139 : 29|13@0+ (0.001,0) [0|5] "V" VCU
 SG_ P3_CellVoltage140 : 32|13@0+ (0.001,0) [0|5] "V" VCU
 SG_ P3_BalSwCell137 : 51|1@0+ (1,0) [0|1] "" VCU
 SG_ P3_BalSwCell138 : 50|1@0+ (1,0) [0|1] "" VCU
 SG_ P3_BalSwCell139 : 49|1@0+ (1,0) [0|1] "" VCU
 SG_ P3_BalSwCell140 : 48|1@0+ (1,0) [0|1] "" VCU

BO_ 2556690483 BatP3_BMS_CellVoltageM35: 8 BMS
 SG_ P3_CellVoltage141 : 7|13@0+ (0.001,0) [0|5] "V" VCU
 SG_ P3_CellVoltage142 : 10|13@0+ (0.001,0) [0|5] "V" VCU
 SG_ P3_CellVoltage143 : 29|13@0+ (0.001,0) [0|5] "V" VCU
 SG_ P3_CellVoltage144 : 32|13@0+ (0.001,0) [0|5] "V" VCU
 SG_ P3_BalSwCell141 : 51|1@0+ (1,0) [0|1] "" VCU
 SG_ P3_BalSwCell142 : 50|1@0+ (1,0) [0|1] "" VCU
 SG_ P3_BalSwCell143 : 49|1@0+ (1,0) [0|1] "" VCU
 SG_ P3_BalSwCell144 : 48|1@0+ (1,0) [0|1] "" VCU

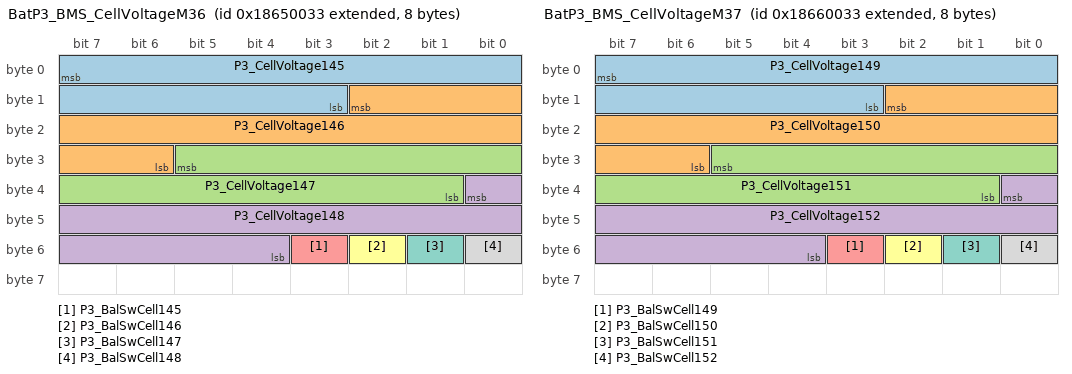
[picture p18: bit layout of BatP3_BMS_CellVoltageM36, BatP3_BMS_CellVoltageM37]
BO_ 2556756019 BatP3_BMS_CellVoltageM36: 8 BMS
 SG_ P3_CellVoltage145 : 7|13@0+ (0.001,0) [0|5] "V" VCU
 SG_ P3_CellVoltage146 : 10|13@0+ (0.001,0) [0|5] "V" VCU
 SG_ P3_CellVoltage147 : 29|13@0+ (0.001,0) [0|5] "V" VCU
 SG_ P3_CellVoltage148 : 32|13@0+ (0.001,0) [0|5] "V" VCU
 SG_ P3_BalSwCell145 : 51|1@0+ (1,0) [0|1] "" VCU
 SG_ P3_BalSwCell146 : 50|1@0+ (1,0) [0|1] "" VCU
 SG_ P3_BalSwCell147 : 49|1@0+ (1,0) [0|1] "" VCU
 SG_ P3_BalSwCell148 : 48|1@0+ (1,0) [0|1] "" VCU

BO_ 2556821555 BatP3_BMS_CellVoltageM37: 8 BMS
 SG_ P3_CellVoltage149 : 7|13@0+ (0.001,0) [0|5] "V" VCU
 SG_ P3_CellVoltage150 : 10|13@0+ (0.001,0) [0|5] "V" VCU
 SG_ P3_CellVoltage151 : 29|13@0+ (0.001,0) [0|5] "V" VCU
 SG_ P3_CellVoltage152 : 32|13@0+ (0.001,0) [0|5] "V" VCU
 SG_ P3_BalSwCell149 : 51|1@0+ (1,0) [0|1] "" VCU
 SG_ P3_BalSwCell150 : 50|1@0+ (1,0) [0|1] "" VCU
 SG_ P3_BalSwCell151 : 49|1@0+ (1,0) [0|1] "" VCU
 SG_ P3_BalSwCell152 : 48|1@0+ (1,0) [0|1] "" VCU

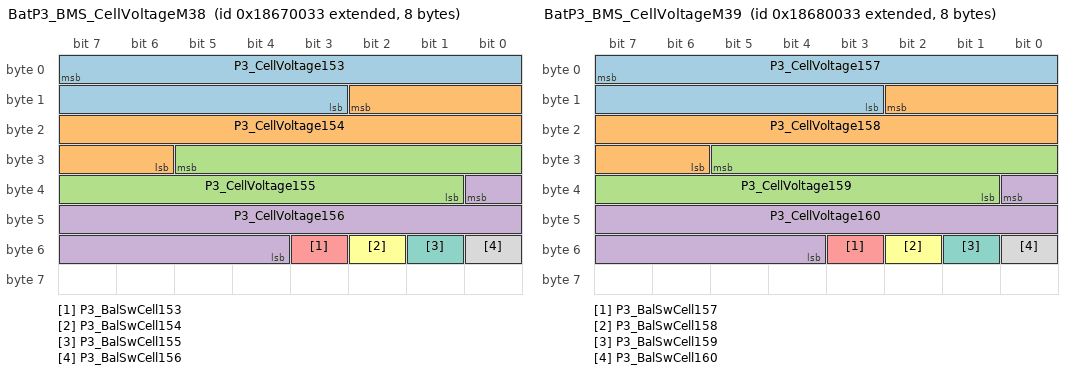
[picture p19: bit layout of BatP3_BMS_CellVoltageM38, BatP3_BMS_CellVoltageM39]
BO_ 2556887091 BatP3_BMS_CellVoltageM38: 8 BMS
 SG_ P3_CellVoltage153 : 7|13@0+ (0.001,0) [0|5] "V" VCU
 SG_ P3_CellVoltage154 : 10|13@0+ (0.001,0) [0|5] "V" VCU
 SG_ P3_CellVoltage155 : 29|13@0+ (0.001,0) [0|5] "V" VCU
 SG_ P3_CellVoltage156 : 32|13@0+ (0.001,0) [0|5] "V" VCU
 SG_ P3_BalSwCell153 : 51|1@0+ (1,0) [0|1] "" VCU
 SG_ P3_BalSwCell154 : 50|1@0+ (1,0) [0|1] "" VCU
 SG_ P3_BalSwCell155 : 49|1@0+ (1,0) [0|1] "" VCU
 SG_ P3_BalSwCell156 : 48|1@0+ (1,0) [0|1] "" VCU

BO_ 2556952627 BatP3_BMS_CellVoltageM39: 8 BMS
 SG_ P3_CellVoltage157 : 7|13@0+ (0.001,0) [0|5] "V" VCU
 SG_ P3_CellVoltage158 : 10|13@0+ (0.001,0) [0|5] "V" VCU
 SG_ P3_CellVoltage159 : 29|13@0+ (0.001,0) [0|5] "V" VCU
 SG_ P3_CellVoltage160 : 32|13@0+ (0.001,0) [0|5] "V" VCU
 SG_ P3_BalSwCell157 : 51|1@0+ (1,0) [0|1] "" VCU
 SG_ P3_BalSwCell158 : 50|1@0+ (1,0) [0|1] "" VCU
 SG_ P3_BalSwCell159 : 49|1@0+ (1,0) [0|1] "" VCU
 SG_ P3_BalSwCell160 : 48|1@0+ (1,0) [0|1] "" VCU

BO_ 2557018163 BatP3_BMS_CellVoltageM40: 8 BMS
 SG_ P3_CellVoltage161 : 7|13@0+ (0.001,0) [0|5] "V" VCU
 SG_ P3_CellVoltage162 : 10|13@0+ (0.001,0) [0|5] "V" VCU
 SG_ P3_CellVoltage163 : 29|13@0+ (0.001,0) [0|5] "V" VCU
 SG_ P3_CellVoltage164 : 32|13@0+ (0.001,0) [0|5] "V" VCU
 SG_ P3_BalSwCell161 : 51|1@0+ (1,0) [0|1] "" VCU
 SG_ P3_BalSwCell162 : 50|1@0+ (1,0) [0|1] "" VCU
 SG_ P3_BalSwCell163 : 49|1@0+ (1,0) [0|1] "" VCU
 SG_ P3_BalSwCell164 : 48|1@0+ (1,0) [0|1] "" VCU

BO_ 2557083699 BatP3_BMS_CellVoltageM41: 8 BMS
 SG_ P3_CellVoltage165 : 7|13@0+ (0.001,0) [0|5] "V" VCU
 SG_ P3_CellVoltage166 : 10|13@0+ (0.001,0) [0|5] "V" VCU
 SG_ P3_CellVoltage167 : 29|13@0+ (0.001,0) [0|5] "V" VCU
 SG_ P3_CellVoltage168 : 32|13@0+ (0.001,0) [0|5] "V" VCU
 SG_ P3_BalSwCell165 : 51|1@0+ (1,0) [0|1] "" VCU
 SG_ P3_BalSwCell166 : 50|1@0+ (1,0) [0|1] "" VCU
 SG_ P3_BalSwCell167 : 49|1@0+ (1,0) [0|1] "" VCU
 SG_ P3_BalSwCell168 : 48|1@0+ (1,0) [0|1] "" VCU

BO_ 2557149235 BatP3_BMS_CellVoltageM42: 8 BMS
 SG_ P3_CellVoltage169 : 7|13@0+ (0.001,0) [0|5] "V" VCU
 SG_ P3_CellVoltage170 : 10|13@0+ (0.001,0) [0|5] "V" VCU
 SG_ P3_CellVoltage171 : 29|13@0+ (0.001,0) [0|5] "V" VCU
 SG_ P3_CellVoltage172 : 32|13@0+ (0.001,0) [0|5] "V" VCU
 SG_ P3_BalSwCell169 : 51|1@0+ (1,0) [0|1] "" VCU
 SG_ P3_BalSwCell170 : 50|1@0+ (1,0) [0|1] "" VCU
 SG_ P3_BalSwCell171 : 49|1@0+ (1,0) [0|1] "" VCU
 SG_ P3_BalSwCell172 : 48|1@0+ (1,0) [0|1] "" VCU

BO_ 2557214771 BatP3_BMS_CellVoltageM43: 8 BMS
 SG_ P3_CellVoltage173 : 7|13@0+ (0.001,0) [0|5] "V" VCU
 SG_ P3_CellVoltage174 : 10|13@0+ (0.001,0) [0|5] "V" VCU
 SG_ P3_CellVoltage175 : 29|13@0+ (0.001,0) [0|5] "V" VCU
 SG_ P3_CellVoltage176 : 32|13@0+ (0.001,0) [0|5] "V" VCU
 SG_ P3_BalSwCell173 : 51|1@0+ (1,0) [0|1] "" VCU
 SG_ P3_BalSwCell174 : 50|1@0+ (1,0) [0|1] "" VCU
 SG_ P3_BalSwCell175 : 49|1@0+ (1,0) [0|1] "" VCU
 SG_ P3_BalSwCell176 : 48|1@0+ (1,0) [0|1] "" VCU

BO_ 2557280307 BatP3_BMS_CellVoltageM44: 8 BMS
 SG_ P3_CellVoltage177 : 7|13@0+ (0.001,0) [0|5] "V" VCU
 SG_ P3_CellVoltage178 : 10|13@0+ (0.001,0) [0|5] "V" VCU
 SG_ P3_CellVoltage179 : 29|13@0+ (0.001,0) [0|5] "V" VCU
 SG_ P3_CellVoltage180 : 32|13@0+ (0.001,0) [0|5] "V" VCU
 SG_ P3_BalSwCell177 : 51|1@0+ (1,0) [0|1] "" VCU
 SG_ P3_BalSwCell178 : 50|1@0+ (1,0) [0|1] "" VCU
 SG_ P3_BalSwCell179 : 49|1@0+ (1,0) [0|1] "" VCU
 SG_ P3_BalSwCell180 : 48|1@0+ (1,0) [0|1] "" VCU

BO_ 2557345843 BatP3_BMS_CellVoltageM45: 8 BMS
 SG_ P3_CellVoltage181 : 7|13@0+ (0.001,0) [0|5] "V" VCU
 SG_ P3_CellVoltage182 : 10|13@0+ (0.001,0) [0|5] "V" VCU
 SG_ P3_CellVoltage183 : 29|13@0+ (0.001,0) [0|5] "V" VCU
 SG_ P3_CellVoltage184 : 32|13@0+ (0.001,0) [0|5] "V" VCU
 SG_ P3_BalSwCell181 : 51|1@0+ (1,0) [0|1] "" VCU
 SG_ P3_BalSwCell182 : 50|1@0+ (1,0) [0|1] "" VCU
 SG_ P3_BalSwCell183 : 49|1@0+ (1,0) [0|1] "" VCU
 SG_ P3_BalSwCell184 : 48|1@0+ (1,0) [0|1] "" VCU

BO_ 2557411379 BatP3_BMS_CellVoltageM46: 8 BMS
 SG_ P3_CellVoltage185 : 7|13@0+ (0.001,0) [0|5] "V" VCU
 SG_ P3_CellVoltage186 : 10|13@0+ (0.001,0) [0|5] "V" VCU
 SG_ P3_CellVoltage187 : 29|13@0+ (0.001,0) [0|5] "V" VCU
 SG_ P3_CellVoltage188 : 32|13@0+ (0.001,0) [0|5] "V" VCU
 SG_ P3_BalSwCell185 : 51|1@0+ (1,0) [0|1] "" VCU
 SG_ P3_BalSwCell186 : 50|1@0+ (1,0) [0|1] "" VCU
 SG_ P3_BalSwCell187 : 49|1@0+ (1,0) [0|1] "" VCU
 SG_ P3_BalSwCell188 : 48|1@0+ (1,0) [0|1] "" VCU

BO_ 2557476915 BatP3_BMS_CellVoltageM47: 8 BMS
 SG_ P3_CellVoltage189 : 7|13@0+ (0.001,0) [0|5] "V" VCU
 SG_ P3_CellVoltage190 : 10|13@0+ (0.001,0) [0|5] "V" VCU
 SG_ P3_CellVoltage191 : 29|13@0+ (0.001,0) [0|5] "V" VCU
 SG_ P3_CellVoltage192 : 32|13@0+ (0.001,0) [0|5] "V" VCU
 SG_ P3_BalSwCell189 : 51|1@0+ (1,0) [0|1] "" VCU
 SG_ P3_BalSwCell190 : 50|1@0+ (1,0) [0|1] "" VCU
 SG_ P3_BalSwCell191 : 49|1@0+ (1,0) [0|1] "" VCU
 SG_ P3_BalSwCell192 : 48|1@0+ (1,0) [0|1] "" VCU

BO_ 2558525491 BatP3_BMS_CellTempM0: 8 BMS
 SG_ P3_CellTemp1 : 7|11@0+ (0.1,-40) [-40|150] "C" VCU
 SG_ P3_CellTemp2 : 12|11@0+ (0.1,-40) [-40|150] "C" VCU
 SG_ P3_CellTemp3 : 17|11@0+ (0.1,-40) [-40|150] "C" VCU
 SG_ P3_CellTemp4 : 38|11@0+ (0.1,-40) [-40|150] "C" VCU
 SG_ P3_CellTemp5 : 43|11@0+ (0.1,-40) [-40|150] "C" VCU

BO_ 2558591027 BatP3_BMS_CellTempM1: 8 BMS
 SG_ P3_CellTemp6 : 7|11@0+ (0.1,-40) [-40|150] "C" VCU
 SG_ P3_CellTemp7 : 12|11@0+ (0.1,-40) [-40|150] "C" VCU
 SG_ P3_CellTemp8 : 17|11@0+ (0.1,-40) [-40|150] "C" VCU
 SG_ P3_CellTemp9 : 38|11@0+ (0.1,-40) [-40|150] "C" VCU
 SG_ P3_CellTemp10 : 43|11@0+ (0.1,-40) [-40|150] "C" VCU

BO_ 2558656563 BatP3_BMS_CellTempM2: 8 BMS
 SG_ P3_CellTemp11 : 7|11@0+ (0.1,-40) [-40|150] "C" VCU
 SG_ P3_CellTemp12 : 12|11@0+ (0.1,-40) [-40|150] "C" VCU
 SG_ P3_CellTemp13 : 17|11@0+ (0.1,-40) [-40|150] "C" VCU
 SG_ P3_CellTemp14 : 38|11@0+ (0.1,-40) [-40|150] "C" VCU
 SG_ P3_CellTemp15 : 43|11@0+ (0.1,-40) [-40|150] "C" VCU

BO_ 2558722099 BatP3_BMS_CellTempM3: 8 BMS
 SG_ P3_CellTemp16 : 7|11@0+ (0.1,-40) [-40|150] "C" VCU
 SG_ P3_CellTemp17 : 12|11@0+ (0.1,-40) [-40|150] "C" VCU
 SG_ P3_CellTemp18 : 17|11@0+ (0.1,-40) [-40|150] "C" VCU
 SG_ P3_CellTemp19 : 38|11@0+ (0.1,-40) [-40|150] "C" VCU
 SG_ P3_CellTemp20 : 43|11@0+ (0.1,-40) [-40|150] "C" VCU

BO_ 2558787635 BatP3_BMS_CellTempM4: 8 BMS
 SG_ P3_CellTemp21 : 7|11@0+ (0.1,-40) [-40|150] "C" VCU
 SG_ P3_CellTemp22 : 12|11@0+ (0.1,-40) [-40|150] "C" VCU
 SG_ P3_CellTemp23 : 17|11@0+ (0.1,-40) [-40|150] "C" VCU
 SG_ P3_CellTemp24 : 38|11@0+ (0.1,-40) [-40|150] "C" VCU
 SG_ P3_CellTemp25 : 43|11@0+ (0.1,-40) [-40|150] "C" VCU

BO_ 2558853171 BatP3_BMS_CellTempM5: 8 BMS
 SG_ P3_CellTemp26 : 7|11@0+ (0.1,-40) [-40|150] "C" VCU
 SG_ P3_CellTemp27 : 12|11@0+ (0.1,-40) [-40|150] "C" VCU
 SG_ P3_CellTemp28 : 17|11@0+ (0.1,-40) [-40|150] "C" VCU
 SG_ P3_CellTemp29 : 38|11@0+ (0.1,-40) [-40|150] "C" VCU
 SG_ P3_CellTemp30 : 43|11@0+ (0.1,-40) [-40|150] "C" VCU

BO_ 2558918707 BatP3_BMS_CellTempM6: 8 BMS
 SG_ P3_CellTemp31 : 7|11@0+ (0.1,-40) [-40|150] "C" VCU
 SG_ P3_CellTemp32 : 12|11@0+ (0.1,-40) [-40|150] "C" VCU
 SG_ P3_CellTemp33 : 17|11@0+ (0.1,-40) [-40|150] "C" VCU
 SG_ P3_CellTemp34 : 38|11@0+ (0.1,-40) [-40|150] "C" VCU
 SG_ P3_CellTemp35 : 43|11@0+ (0.1,-40) [-40|150] "C" VCU

BO_ 2558984243 BatP3_BMS_CellTempM7: 8 BMS
 SG_ P3_CellTemp36 : 7|11@0+ (0.1,-40) [-40|150] "C" VCU
 SG_ P3_CellTemp37 : 12|11@0+ (0.1,-40) [-40|150] "C" VCU
 SG_ P3_CellTemp38 : 17|11@0+ (0.1,-40) [-40|150] "C" VCU
 SG_ P3_CellTemp39 : 38|11@0+ (0.1,-40) [-40|150] "C" VCU
 SG_ P3_CellTemp40 : 43|11@0+ (0.1,-40) [-40|150] "C" VCU

BO_ 2559049779 BatP3_BMS_CellTempM8: 8 BMS
 SG_ P3_CellTemp41 : 7|11@0+ (0.1,-40) [-40|150] "C" VCU
 SG_ P3_CellTemp42 : 12|11@0+ (0.1,-40) [-40|150] "C" VCU
 SG_ P3_CellTemp43 : 17|11@0+ (0.1,-40) [-40|150] "C" VCU
 SG_ P3_CellTemp44 : 38|11@0+ (0.1,-40) [-40|150] "C" VCU
 SG_ P3_CellTemp45 : 43|11@0+ (0.1,-40) [-40|150] "C" VCU

BO_ 2559115315 BatP3_BMS_CellTempM9: 8 BMS
 SG_ P3_CellTemp46 : 7|11@0+ (0.1,-40) [-40|150] "C" VCU
 SG_ P3_CellTemp47 : 12|11@0+ (0.1,-40) [-40|150] "C" VCU
 SG_ P3_CellTemp48 : 17|11@0+ (0.1,-40) [-40|150] "C" VCU
 SG_ P3_CellTemp49 : 38|11@0+ (0.1,-40) [-40|150] "C" VCU
 SG_ P3_CellTemp50 : 43|11@0+ (0.1,-40) [-40|150] "C" VCU

BO_ 2559180851 BatP3_BMS_CellTempM10: 8 BMS
 SG_ P3_CellTemp51 : 7|11@0+ (0.1,-40) [-40|150] "C" VCU
 SG_ P3_CellTemp52 : 12|11@0+ (0.1,-40) [-40|150] "C" VCU
 SG_ P3_CellTemp53 : 17|11@0+ (0.1,-40) [-40|150] "C" VCU
 SG_ P3_CellTemp54 : 38|11@0+ (0.1,-40) [-40|150] "C" VCU
 SG_ P3_CellTemp55 : 43|11@0+ (0.1,-40) [-40|150] "C" VCU

BO_ 2559246387 BatP3_BMS_CellTempM11: 8 BMS
 SG_ P3_CellTemp56 : 7|11@0+ (0.1,-40) [-40|150] "C" VCU
 SG_ P3_CellTemp57 : 12|11@0+ (0.1,-40) [-40|150] "C" VCU
 SG_ P3_CellTemp58 : 17|11@0+ (0.1,-40) [-40|150] "C" VCU
 SG_ P3_CellTemp59 : 38|11@0+ (0.1,-40) [-40|150] "C" VCU
 SG_ P3_CellTemp60 : 43|11@0+ (0.1,-40) [-40|150] "C" VCU

BO_ 2559311923 BatP3_BMS_CellTempM12: 8 BMS
 SG_ P3_CellTemp61 : 7|11@0+ (0.1,-40) [-40|150] "C" VCU
 SG_ P3_CellTemp62 : 12|11@0+ (0.1,-40) [-40|150] "C" VCU
 SG_ P3_CellTemp63 : 17|11@0+ (0.1,-40) [-40|150] "C" VCU
 SG_ P3_CellTemp64 : 38|11@0+ (0.1,-40) [-40|150] "C" VCU
 SG_ P3_CellTemp65 : 43|11@0+ (0.1,-40) [-40|150] "C" VCU

BO_ 2559377459 BatP3_BMS_CellTempM13: 8 BMS
 SG_ P3_CellTemp66 : 7|11@0+ (0.1,-40) [-40|150] "C" VCU
 SG_ P3_CellTemp67 : 12|11@0+ (0.1,-40) [-40|150] "C" VCU
 SG_ P3_CellTemp68 : 17|11@0+ (0.1,-40) [-40|150] "C" VCU
 SG_ P3_CellTemp69 : 38|11@0+ (0.1,-40) [-40|150] "C" VCU
 SG_ P3_CellTemp70 : 43|11@0+ (0.1,-40) [-40|150] "C" VCU

BO_ 2559442995 BatP3_BMS_CellTempM14: 8 BMS
 SG_ P3_CellTemp71 : 7|11@0+ (0.1,-40) [-40|150] "C" VCU
 SG_ P3_CellTemp72 : 12|11@0+ (0.1,-40) [-40|150] "C" VCU
 SG_ P3_CellTemp73 : 17|11@0+ (0.1,-40) [-40|150] "C" VCU
 SG_ P3_CellTemp74 : 38|11@0+ (0.1,-40) [-40|150] "C" VCU
 SG_ P3_CellTemp75 : 43|11@0+ (0.1,-40) [-40|150] "C" VCU

BO_ 2559508531 BatP3_BMS_CellTempM15: 8 BMS
 SG_ P3_CellTemp76 : 7|11@0+ (0.1,-40) [-40|150] "C" VCU
 SG_ P3_CellTemp77 : 12|11@0+ (0.1,-40) [-40|150] "C" VCU
 SG_ P3_CellTemp78 : 17|11@0+ (0.1,-40) [-40|150] "C" VCU
 SG_ P3_CellTemp79 : 38|11@0+ (0.1,-40) [-40|150] "C" VCU
 SG_ P3_CellTemp80 : 43|11@0+ (0.1,-40) [-40|150] "C" VCU

BO_ 2559574067 BatP3_BMS_CellTempM16: 8 BMS
 SG_ P3_CellTemp81 : 7|11@0+ (0.1,-40) [-40|150] "C" VCU
 SG_ P3_CellTemp82 : 12|11@0+ (0.1,-40) [-40|150] "C" VCU
 SG_ P3_CellTemp83 : 17|11@0+ (0.1,-40) [-40|150] "C" VCU
 SG_ P3_CellTemp84 : 38|11@0+ (0.1,-40) [-40|150] "C" VCU
 SG_ P3_CellTemp85 : 43|11@0+ (0.1,-40) [-40|150] "C" VCU

BO_ 2559639603 BatP3_BMS_CellTempM17: 8 BMS
 SG_ P3_CellTemp86 : 7|11@0+ (0.1,-40) [-40|150] "C" VCU
 SG_ P3_CellTemp87 : 12|11@0+ (0.1,-40) [-40|150] "C" VCU
 SG_ P3_CellTemp88 : 17|11@0+ (0.1,-40) [-40|150] "C" VCU
 SG_ P3_CellTemp89 : 38|11@0+ (0.1,-40) [-40|150] "C" VCU
 SG_ P3_CellTemp90 : 43|11@0+ (0.1,-40) [-40|150] "C" VCU

BO_ 2559705139 BatP3_BMS_CellTempM18: 8 BMS
 SG_ P3_CellTemp91 : 7|11@0+ (0.1,-40) [-40|150] "C" VCU
 SG_ P3_CellTemp92 : 12|11@0+ (0.1,-40) [-40|150] "C" VCU
 SG_ P3_CellTemp93 : 17|11@0+ (0.1,-40) [-40|150] "C" VCU
 SG_ P3_CellTemp94 : 38|11@0+ (0.1,-40) [-40|150] "C" VCU
 SG_ P3_CellTemp95 : 43|11@0+ (0.1,-40) [-40|150] "C" VCU

BO_ 2559770675 BatP3_BMS_CellTempM19: 8 BMS
 SG_ P3_CellTemp96 : 7|11@0+ (0.1,-40) [-40|150] "C" VCU
 SG_ P3_CellTemp97 : 12|11@0+ (0.1,-40) [-40|150] "C" VCU
 SG_ P3_CellTemp98 : 17|11@0+ (0.1,-40) [-40|150] "C" VCU
 SG_ P3_CellTemp99 : 38|11@0+ (0.1,-40) [-40|150] "C" VCU
 SG_ P3_CellTemp100 : 43|11@0+ (0.1,-40) [-40|150] "C" VCU

BO_ 2559836211 BatP3_BMS_CellTempM20: 8 BMS
 SG_ P3_CellTemp101 : 7|11@0+ (0.1,-40) [-40|150] "C" VCU
 SG_ P3_CellTemp102 : 12|11@0+ (0.1,-40) [-40|150] "C" VCU
 SG_ P3_CellTemp103 : 17|11@0+ (0.1,-40) [-40|150] "C" VCU
 SG_ P3_CellTemp104 : 38|11@0+ (0.1,-40) [-40|150] "C" VCU
 SG_ P3_CellTemp105 : 43|11@0+ (0.1,-40) [-40|150] "C" VCU

BO_ 2559901747 BatP3_BMS_CellTempM21: 8 BMS
 SG_ P3_CellTemp106 : 7|11@0+ (0.1,-40) [-40|150] "C" VCU
 SG_ P3_CellTemp107 : 12|11@0+ (0.1,-40) [-40|150] "C" VCU
 SG_ P3_CellTemp108 : 17|11@0+ (0.1,-40) [-40|150] "C" VCU
 SG_ P3_CellTemp109 : 38|11@0+ (0.1,-40) [-40|150] "C" VCU
 SG_ P3_CellTemp110 : 43|11@0+ (0.1,-40) [-40|150] "C" VCU

BO_ 2559967283 BatP3_BMS_CellTempM22: 8 BMS
 SG_ P3_CellTemp111 : 7|11@0+ (0.1,-40) [-40|150] "C" VCU
 SG_ P3_CellTemp112 : 12|11@0+ (0.1,-40) [-40|150] "C" VCU
 SG_ P3_CellTemp113 : 17|11@0+ (0.1,-40) [-40|150] "C" VCU
 SG_ P3_CellTemp114 : 38|11@0+ (0.1,-40) [-40|150] "C" VCU
 SG_ P3_CellTemp115 : 43|11@0+ (0.1,-40) [-40|150] "C" VCU

BO_ 2560032819 BatP3_BMS_CellTempM23: 8 BMS
 SG_ P3_CellTemp116 : 7|11@0+ (0.1,-40) [-40|150] "C" VCU
 SG_ P3_CellTemp117 : 12|11@0+ (0.1,-40) [-40|150] "C" VCU
 SG_ P3_CellTemp118 : 17|11@0+ (0.1,-40) [-40|150] "C" VCU
 SG_ P3_CellTemp119 : 38|11@0+ (0.1,-40) [-40|150] "C" VCU
 SG_ P3_CellTemp120 : 43|11@0+ (0.1,-40) [-40|150] "C" VCU

BO_ 2560098355 BatP3_BMS_CellTempM24: 8 BMS
 SG_ P3_CellTemp121 : 7|11@0+ (0.1,-40) [-40|150] "C" VCU
 SG_ P3_CellTemp122 : 12|11@0+ (0.1,-40) [-40|150] "C" VCU
 SG_ P3_CellTemp123 : 17|11@0+ (0.1,-40) [-40|150] "C" VCU
 SG_ P3_CellTemp124 : 38|11@0+ (0.1,-40) [-40|150] "C" VCU
 SG_ P3_CellTemp125 : 43|11@0+ (0.1,-40) [-40|150] "C" VCU

BO_ 2560163891 BatP3_BMS_CellTempM25: 8 BMS
 SG_ P3_CellTemp126 : 7|11@0+ (0.1,-40) [-40|150] "C" VCU
 SG_ P3_CellTemp127 : 12|11@0+ (0.1,-40) [-40|150] "C" VCU
 SG_ P3_CellTemp128 : 17|11@0+ (0.1,-40) [-40|150] "C" VCU
 SG_ P3_CellTemp129 : 38|11@0+ (0.1,-40) [-40|150] "C" VCU
 SG_ P3_CellTemp130 : 43|11@0+ (0.1,-40) [-40|150] "C" VCU

BO_ 2560229427 BatP3_BMS_CellTempM26: 8 BMS
 SG_ P3_CellTemp131 : 7|11@0+ (0.1,-40) [-40|150] "C" VCU
 SG_ P3_CellTemp132 : 12|11@0+ (0.1,-40) [-40|150] "C" VCU
 SG_ P3_CellTemp133 : 17|11@0+ (0.1,-40) [-40|150] "C" VCU
 SG_ P3_CellTemp134 : 38|11@0+ (0.1,-40) [-40|150] "C" VCU
 SG_ P3_CellTemp135 : 43|11@0+ (0.1,-40) [-40|150] "C" VCU

BO_ 2560294963 BatP3_BMS_CellTempM27: 8 BMS
 SG_ P3_CellTemp136 : 7|11@0+ (0.1,-40) [-40|150] "C" VCU
 SG_ P3_CellTemp137 : 12|11@0+ (0.1,-40) [-40|150] "C" VCU
 SG_ P3_CellTemp138 : 17|11@0+ (0.1,-40) [-40|150] "C" VCU
 SG_ P3_CellTemp139 : 38|11@0+ (0.1,-40) [-40|150] "C" VCU
 SG_ P3_CellTemp140 : 43|11@0+ (0.1,-40) [-40|150] "C" VCU

BO_ 2560360499 BatP3_BMS_CellTempM28: 8 BMS
 SG_ P3_CellTemp141 : 7|11@0+ (0.1,-40) [-40|150] "C" VCU
 SG_ P3_CellTemp142 : 12|11@0+ (0.1,-40) [-40|150] "C" VCU
 SG_ P3_CellTemp143 : 17|11@0+ (0.1,-40) [-40|150] "C" VCU
 SG_ P3_CellTemp144 : 38|11@0+ (0.1,-40) [-40|150] "C" VCU
 SG_ P3_CellTemp145 : 43|11@0+ (0.1,-40) [-40|150] "C" VCU

BO_ 2560426035 BatP3_BMS_CellTempM29: 8 BMS
 SG_ P3_CellTemp146 : 7|11@0+ (0.1,-40) [-40|150] "C" VCU
 SG_ P3_CellTemp147 : 12|11@0+ (0.1,-40) [-40|150] "C" VCU
 SG_ P3_CellTemp148 : 17|11@0+ (0.1,-40) [-40|150] "C" VCU
 SG_ P3_CellTemp149 : 38|11@0+ (0.1,-40) [-40|150] "C" VCU
 SG_ P3_CellTemp150 : 43|11@0+ (0.1,-40) [-40|150] "C" VCU

BO_ 2560491571 BatP3_BMS_CellTempM30: 8 BMS
 SG_ P3_CellTemp151 : 7|11@0+ (0.1,-40) [-40|150] "C" VCU
 SG_ P3_CellTemp152 : 12|11@0+ (0.1,-40) [-40|150] "C" VCU
 SG_ P3_CellTemp153 : 17|11@0+ (0.1,-40) [-40|150] "C" VCU
 SG_ P3_CellTemp154 : 38|11@0+ (0.1,-40) [-40|150] "C" VCU
 SG_ P3_CellTemp155 : 43|11@0+ (0.1,-40) [-40|150] "C" VCU

BO_ 2560557107 BatP3_BMS_CellTempM31: 8 BMS
 SG_ P3_CellTemp156 : 7|11@0+ (0.1,-40) [-40|150] "C" VCU
 SG_ P3_CellTemp157 : 12|11@0+ (0.1,-40) [-40|150] "C" VCU
 SG_ P3_CellTemp158 : 17|11@0+ (0.1,-40) [-40|150] "C" VCU
 SG_ P3_CellTemp159 : 38|11@0+ (0.1,-40) [-40|150] "C" VCU
 SG_ P3_CellTemp160 : 43|11@0+ (0.1,-40) [-40|150] "C" VCU

BO_ 2560622643 BatP3_BMS_CellTempM32: 8 BMS
 SG_ P3_CellTemp161 : 7|11@0+ (0.1,-40) [-40|150] "C" VCU
 SG_ P3_CellTemp162 : 12|11@0+ (0.1,-40) [-40|150] "C" VCU
 SG_ P3_CellTemp163 : 17|11@0+ (0.1,-40) [-40|150] "C" VCU
 SG_ P3_CellTemp164 : 38|11@0+ (0.1,-40) [-40|150] "C" VCU
 SG_ P3_CellTemp165 : 43|11@0+ (0.1,-40) [-40|150] "C" VCU

BO_ 2560688179 BatP3_BMS_CellTempM33: 8 BMS
 SG_ P3_CellTemp166 : 7|11@0+ (0.1,-40) [-40|150] "C" VCU
 SG_ P3_CellTemp167 : 12|11@0+ (0.1,-40) [-40|150] "C" VCU
 SG_ P3_CellTemp168 : 17|11@0+ (0.1,-40) [-40|150] "C" VCU
 SG_ P3_CellTemp169 : 38|11@0+ (0.1,-40) [-40|150] "C" VCU
 SG_ P3_CellTemp170 : 43|11@0+ (0.1,-40) [-40|150] "C" VCU

BO_ 2560753715 BatP3_BMS_CellTempM34: 8 BMS
 SG_ P3_CellTemp171 : 7|11@0+ (0.1,-40) [-40|150] "C" VCU
 SG_ P3_CellTemp172 : 12|11@0+ (0.1,-40) [-40|150] "C" VCU
 SG_ P3_CellTemp173 : 17|11@0+ (0.1,-40) [-40|150] "C" VCU
 SG_ P3_CellTemp174 : 38|11@0+ (0.1,-40) [-40|150] "C" VCU
 SG_ P3_CellTemp175 : 43|11@0+ (0.1,-40) [-40|150] "C" VCU

BO_ 2560819251 BatP3_BMS_CellTempM35: 8 BMS
 SG_ P3_CellTemp176 : 7|11@0+ (0.1,-40) [-40|150] "C" VCU
 SG_ P3_CellTemp177 : 12|11@0+ (0.1,-40) [-40|150] "C" VCU
 SG_ P3_CellTemp178 : 17|11@0+ (0.1,-40) [-40|150] "C" VCU
 SG_ P3_CellTemp179 : 38|11@0+ (0.1,-40) [-40|150] "C" VCU
 SG_ P3_CellTemp180 : 43|11@0+ (0.1,-40) [-40|150] "C" VCU

BO_ 2560884787 BatP3_BMS_CellTempM36: 8 BMS
 SG_ P3_CellTemp181 : 7|11@0+ (0.1,-40) [-40|150] "C" VCU
 SG_ P3_CellTemp182 : 12|11@0+ (0.1,-40) [-40|150] "C" VCU
 SG_ P3_CellTemp183 : 17|11@0+ (0.1,-40) [-40|150] "C" VCU
 SG_ P3_CellTemp184 : 38|11@0+ (0.1,-40) [-40|150] "C" VCU
 SG_ P3_CellTemp185 : 43|11@0+ (0.1,-40) [-40|150] "C" VCU

BO_ 2560950323 BatP3_BMS_CellTempM37: 8 BMS
 SG_ P3_CellTemp186 : 7|11@0+ (0.1,-40) [-40|150] "C" VCU
 SG_ P3_CellTemp187 : 12|11@0+ (0.1,-40) [-40|150] "C" VCU
 SG_ P3_CellTemp188 : 17|11@0+ (0.1,-40) [-40|150] "C" VCU
 SG_ P3_CellTemp189 : 38|11@0+ (0.1,-40) [-40|150] "C" VCU
 SG_ P3_CellTemp190 : 43|11@0+ (0.1,-40) [-40|150] "C" VCU

BO_ 2561015859 BatP3_BMS_CellTempM38: 8 BMS
 SG_ P3_CellTemp191 : 7|11@0+ (0.1,-40) [-40|150] "C" VCU
 SG_ P3_CellTemp192 : 12|11@0+ (0.1,-40) [-40|150] "C" VCU
 SG_ P3_DatLen16DbgInfo1 : 7|16@0+ (1,0) [0|65535] "" VCU
 SG_ P3_DatLen16DbgInfo2 : 23|16@0+ (1,0) [0|65535] "" VCU
 SG_ P3_DatLen16DbgInfo3 : 39|16@0+ (1,0) [0|65535] "" VCU
 SG_ P3_DatLen16DbgInfo4 : 55|16@0+ (1,0) [0|65535] "" VCU

BO_ 2550399044 BatP4_BMS_PowerSupplyInfo: 8 BMS
 SG_ P4_BMSPwrSuplVlt1 : 7|9@0+ (0.1,0) [0|50] "V" VCU
 SG_ P4_BMSPwrSuplVlt2 : 14|9@0+ (0.1,0) [0|50] "V" VCU
 SG_ P4_ChrgStationAuxPwrSuplVlt : 21|9@0+ (0.1,0) [0|50] "V" VCU
 SG_ P4_BMSKL15ON : 28|1@0+ (1,0) [0|1] "" VCU
 SG_ P4_DCStepState : 27|8@0+ (1,0) [0|255] "" VCU
 SG_ P4_ExtLvWakeup_28VOnly : 35|9@0+ (0.1,0) [0|50] "V" VCU

BO_ 2550464580 BatP4_BMS_PackUsageLimit: 8 BMS
 SG_ P4_PackVltUprLmt : 7|14@0+ (0.1,0) [0|1200] "V" VCU
 SG_ P4_PackVltLoLmt : 9|14@0+ (0.1,0) [0|1200] "V" VCU
 SG_ P4_PackMaxDschrgCrnt : 27|14@0+ (0.1,0) [0|1600] "A" VCU
 SG_ P4_PackMaxChrgCrnt : 45|14@0+ (0.1,0) [0|1600] "A" VCU

BO_ 2550530116 BatP4_BMS_PackPowerCapability: 8 BMS
 SG_ P4_PackDschrgPwrLmt : 7|10@0+ (1,0) [0|1000] "kW" VCU
 SG_ P4_PackDschrgPwrStat : 13|2@0+ (1,0) [0|3] "" VCU
 SG_ P4_PackChrgPwrLmt : 11|10@0+ (1,0) [0|1000] "kW" VCU
 SG_ P4_PackChrgPwrStat : 17|2@0+ (1,0) [0|3] "" VCU

BO_ 2550595652 BatP4_BMS_ChargingInfo: 8 BMS
 SG_ P4_ChrgrCplrStat : 7|1@0+ (1,0) [0|1] "" VCU
 SG_ P4_HVBattChrgSysStatus : 6|4@0+ (1,0) [0|15] "" VCU
 SG_ P4_DCChrgCrntCmd : 2|9@0+ (1,0) [0|500] "A" VCU
 SG_ P4_CC2Vlt : 9|8@0+ (0.1,0) [0|25] "V" VCU
 SG_ P4_DCRcptPosTemp : 17|9@0+ (0.5,-40) [-40|150] "C" VCU
 SG_ P4_DCRcptNegTemp : 24|9@0+ (0.5,-40) [-40|150] "C" VCU
 SG_ P4_Tm2FullChrg : 47|14@0+ (1,0) [0|65535] "min" VCU

BO_ 2550661188 BatP4_BMS_ThermalManagement: 8 BMS
 SG_ P4_Inlet1ClntTemp : 7|11@0+ (0.1,-40) [-40|150] "C" VCU
 SG_ P4_Inlet2ClntTemp : 12|11@0+ (0.1,-40) [-40|150] "C" VCU
 SG_ P4_Outlet1ClntTemp : 17|11@0+ (0.1,-40) [-40|150] "C" VCU
 SG_ P4_Outlet2ClntTemp : 38|11@0+ (0.1,-40) [-40|150] "C" VCU
 SG_ P4_TrgtClntTemp : 43|11@0+ (0.1,-40) [-40|150] "C" VCU
 SG_ P4_TrgtClntFlowRate : 48|9@0+ (0.2,0) [0|100] "C" VCU

BO_ 2550726724 BatP4_BMS_CellVoltMaxMin: 8 BMS
 SG_ P4_MaxCellVlt : 7|13@0+ (0.001,0) [0|5] "V" VCU
 SG_ P4_MaxCellVltNum : 10|9@0+ (1,0) [0|500] "" VCU
 SG_ P4_MinCellVlt : 17|13@0+ (0.001,0) [0|5] "V" VCU
 SG_ P4_MinCellVltNum : 36|9@0+ (1,0) [0|500] "" VCU
 SG_ P4_AvgCellVlt : 43|13@0+ (0.001,0) [0|5] "V" VCU

BO_ 2550792260 BatP4_BMS_CellTempMaxMin: 8 BMS
 SG_ P4_MaxCellTemp : 7|11@0+ (0.1,-40) [-40|150] "C" VCU
 SG_ P4_MaxCellTempNum : 12|9@0+ (1,0) [0|500] "" VCU
 SG_ P4_MinCellTemp : 19|11@0+ (0.1,-40) [-40|150] "C" VCU
 SG_ P4_MinCellTempNum : 24|9@0+ (1,0) [0|500] "" VCU
 SG_ P4_AvgCellTemp : 47|11@0+ (0.1,-40) [-40|150] "C" VCU

BO_ 2550857796 BatP4_BMS_PackFaultInfo1: 8 BMS
 SG_ P4_PackTotFltNum : 7|8@0+ (1,0) [0|200] "" VCU
 SG_ P4_CellOverVoltage : 15|2@0+ (1,0) [0|3] "" VCU
 SG_ P4_CellUnderVoltage : 13|2@0+ (1,0) [0|3] "" VCU
 SG_ P4_CellVoltageDiffHi : 11|1@0+ (1,0) [0|1] "" VCU
 SG_ P4_PackOverVoltage : 10|2@0+ (1,0) [0|3] "" VCU
 SG_ P4_PackUnderVoltage : 8|2@0+ (1,0) [0|3] "" VCU
 SG_ P4_CellOverTemp : 22|2@0+ (1,0) [0|3] "" VCU
 SG_ P4_CellTempLow : 20|1@0+ (1,0) [0|1] "" VCU
 SG_ P4_CellTempDiffHi : 19|1@0+ (1,0) [0|1] "" VCU
 SG_ P4_PackDschrgCrntHi : 18|2@0+ (1,0) [0|3] "" VCU
 SG_ P4_PackChrgCrntHi : 16|2@0+ (1,0) [0|3] "" VCU
 SG_ P4_PackCrnSnsr1OffsetHi : 30|1@0+ (1,0) [0|1] "" VCU
 SG_ P4_HVIsolFlt : 29|2@0+ (1,0) [0|3] "" VCU
 SG_ P4_HVILFlt : 27|1@0+ (1,0) [0|1] "" VCU
 SG_ P4_ThrmlRunaway : 26|1@0+ (1,0) [0|1] "" VCU
 SG_ P4_CellVoltInvalid : 25|1@0+ (1,0) [0|1] "" VCU
 SG_ P4_CellTempInvalid : 24|1@0+ (1,0) [0|1] "" VCU
 SG_ P4_DaisyChainComFlt : 39|1@0+ (1,0) [0|1] "" VCU
 SG_ P4_PackVoltRatFlt : 38|1@0+ (1,0) [0|1] "" VCU
 SG_ P4_CrntSnsr1Invalid : 37|1@0+ (1,0) [0|1] "" VCU
 SG_ P4_CrntSnsr1OOR : 36|1@0+ (1,0) [0|1] "" VCU
 SG_ P4_CrntSnsr2Invalid : 35|1@0+ (1,0) [0|1] "" VCU
 SG_ P4_CrntSnsr2OOR : 34|1@0+ (1,0) [0|1] "" VCU
 SG_ P4_PackCrnSnsr2OffsetHi : 33|1@0+ (1,0) [0|1] "" VCU
 SG_ P4_OutofEnergy : 32|1@0+ (1,0) [0|1] "" VCU
 SG_ P4_IsolDetCircErr : 47|1@0+ (1,0) [0|1] "" VCU
 SG_ P4_HVILCircShortToGND : 46|1@0+ (1,0) [0|1] "" VCU
 SG_ P4_HVILCircShortToPwr : 45|1@0+ (1,0) [0|1] "" VCU

BO_ 2550923332 BatP4_BMS_PackFaultInfo2: 8 BMS
 SG_ P4_MainPosCntctrStkClsd : 7|1@0+ (1,0) [0|1] "" VCU
 SG_ P4_MainPosCntctrStkOpn : 6|1@0+ (1,0) [0|1] "" VCU
 SG_ P4_MainNegCntctr1StkClsd : 5|1@0+ (1,0) [0|1] "" VCU
 SG_ P4_MainNegCntctr1StkOpn : 4|1@0+ (1,0) [0|1] "" VCU
 SG_ P4_MainNegCntctr2StkClsd : 3|1@0+ (1,0) [0|1] "" VCU
 SG_ P4_MainNegCntctr2StkOpn : 2|1@0+ (1,0) [0|1] "" VCU
 SG_ P4_PrechargTmOut : 1|1@0+ (1,0) [0|1] "" VCU
 SG_ P4_PrechrgCrntHi : 0|1@0+ (1,0) [0|1] "" VCU
 SG_ P4_ChrgCplrPosTempHi : 15|1@0+ (1,0) [0|1] "" VCU
 SG_ P4_ChrgCplrNegTempHi : 14|1@0+ (1,0) [0|1] "" VCU
 SG_ P4_BMSPwrSuplVlt1Hi : 13|1@0+ (1,0) [0|1] "" VCU
 SG_ P4_BMSPwrSuplVlt1Lo : 12|1@0+ (1,0) [0|1] "" VCU
 SG_ P4_BMSPwrSuplVlt2Hi : 11|1@0+ (1,0) [0|1] "" VCU
 SG_ P4_BMSPwrSuplVlt2Lo : 10|1@0+ (1,0) [0|1] "" VCU
 SG_ P4_CntctrCirPwrSuplVltLo : 9|1@0+ (1,0) [0|1] "" VCU
 SG_ P4_CntctrCirPwrSuplVltHi : 8|1@0+ (1,0) [0|1] "" VCU
 SG_ P4_CAN1BusOff : 23|1@0+ (1,0) [0|1] "" VCU
 SG_ P4_CAN1BusTmOut : 22|1@0+ (1,0) [0|1] "" VCU
 SG_ P4_CAN2BusOff : 21|1@0+ (1,0) [0|1] "" VCU
 SG_ P4_CAN2BusTmOut : 20|1@0+ (1,0) [0|1] "" VCU
 SG_ P4_CellBalCircTempHi : 19|1@0+ (1,0) [0|1] "" VCU
 SG_ P4_ClntInTempHi : 18|1@0+ (1,0) [0|1] "" VCU
 SG_ P4_ClntOutTempHi : 17|1@0+ (1,0) [0|1] "" VCU
 SG_ P4_CellExtrmUdrVolt : 16|1@0+ (1,0) [0|1] "" VCU
 SG_ P4_CellExtrmOvrVolt : 31|1@0+ (1,0) [0|1] "" VCU
 SG_ P4_Branch1DischrgCrntHi  : 30|1@0+ (1,0) [0|1] "" VCU
 SG_ P4_Branch2DischrgCrntHi  : 29|1@0+ (1,0) [0|1] "" VCU
 SG_ P4_Branch1ChrgCrntHi  : 28|1@0+ (1,0) [0|1] "" VCU
 SG_ P4_Branch2ChrgCrntHi  : 27|1@0+ (1,0) [0|1] "" VCU
 SG_ P4_InitFailed : 26|1@0+ (1,0) [0|1] "" VCU
 SG_ P4_PackErrCode : 25|10@0+ (1,0) [0|1023] "" VCU

BO_ 2550988868 BatP4_BMS_PackConfigInfo: 8 BMS
 SG_ P4_PackTotCellNum : 7|9@0+ (1,0) [0|500] "" VCU
 SG_ P4_PackTotCellTempSnsrNum : 14|9@0+ (1,0) [0|500] "" VCU

BO_ 2552299588 BatP4_BMS_BMSVersion: 8 BMS
 SG_ P4_BMSASWMajVerNum : 7|8@0+ (1,0) [0|9] "" VCU
 SG_ P4_BMSASWMinVerNum : 15|8@0+ (1,0) [0|99] "" VCU
 SG_ P4_BMSASWPatchVerNum : 23|8@0+ (1,0) [0|255] "" VCU
 SG_ P4_BMSBSWMajVerNum : 31|8@0+ (1,0) [0|9] "" VCU
 SG_ P4_BMSBSWMinVerNum : 39|8@0+ (1,0) [0|99] "" VCU
 SG_ P4_BMSBSWPatchVerNum : 47|8@0+ (1,0) [0|255] "" VCU

BO_ 2554396740 BatP4_BMS_CellVoltageM0: 8 BMS
 SG_ P4_CellVoltage1 : 7|13@0+ (0.001,0) [0|5] "V" VCU
 SG_ P4_CellVoltage2 : 10|13@0+ (0.001,0) [0|5] "V" VCU
 SG_ P4_CellVoltage3 : 29|13@0+ (0.001,0) [0|5] "V" VCU
 SG_ P4_CellVoltage4 : 32|13@0+ (0.001,0) [0|5] "V" VCU
 SG_ P4_BalSwCell1 : 51|1@0+ (1,0) [0|1] "" VCU
 SG_ P4_BalSwCell2 : 50|1@0+ (1,0) [0|1] "" VCU
 SG_ P4_BalSwCell3 : 49|1@0+ (1,0) [0|1] "" VCU
 SG_ P4_BalSwCell4 : 48|1@0+ (1,0) [0|1] "" VCU

BO_ 2554462276 BatP4_BMS_CellVoltageM1: 8 BMS
 SG_ P4_CellVoltage5 : 7|13@0+ (0.001,0) [0|5] "V" VCU
 SG_ P4_CellVoltage6 : 10|13@0+ (0.001,0) [0|5] "V" VCU
 SG_ P4_CellVoltage7 : 29|13@0+ (0.001,0) [0|5] "V" VCU
 SG_ P4_CellVoltage8 : 32|13@0+ (0.001,0) [0|5] "V" VCU
 SG_ P4_BalSwCell5 : 51|1@0+ (1,0) [0|1] "" VCU
 SG_ P4_BalSwCell6 : 50|1@0+ (1,0) [0|1] "" VCU
 SG_ P4_BalSwCell7 : 49|1@0+ (1,0) [0|1] "" VCU
 SG_ P4_BalSwCell8 : 48|1@0+ (1,0) [0|1] "" VCU

BO_ 2554527812 BatP4_BMS_CellVoltageM2: 8 BMS
 SG_ P4_CellVoltage9 : 7|13@0+ (0.001,0) [0|5] "V" VCU
 SG_ P4_CellVoltage10 : 10|13@0+ (0.001,0) [0|5] "V" VCU
 SG_ P4_CellVoltage11 : 29|13@0+ (0.001,0) [0|5] "V" VCU
 SG_ P4_CellVoltage12 : 32|13@0+ (0.001,0) [0|5] "V" VCU
 SG_ P4_BalSwCell9 : 51|1@0+ (1,0) [0|1] "" VCU
 SG_ P4_BalSwCell10 : 50|1@0+ (1,0) [0|1] "" VCU
 SG_ P4_BalSwCell11 : 49|1@0+ (1,0) [0|1] "" VCU
 SG_ P4_BalSwCell12 : 48|1@0+ (1,0) [0|1] "" VCU

BO_ 2554593348 BatP4_BMS_CellVoltageM3: 8 BMS
 SG_ P4_CellVoltage13 : 7|13@0+ (0.001,0) [0|5] "V" VCU
 SG_ P4_CellVoltage14 : 10|13@0+ (0.001,0) [0|5] "V" VCU
 SG_ P4_CellVoltage15 : 29|13@0+ (0.001,0) [0|5] "V" VCU
 SG_ P4_CellVoltage16 : 32|13@0+ (0.001,0) [0|5] "V" VCU
 SG_ P4_BalSwCell13 : 51|1@0+ (1,0) [0|1] "" VCU
 SG_ P4_BalSwCell14 : 50|1@0+ (1,0) [0|1] "" VCU
 SG_ P4_BalSwCell15 : 49|1@0+ (1,0) [0|1] "" VCU
 SG_ P4_BalSwCell16 : 48|1@0+ (1,0) [0|1] "" VCU

BO_ 2554658884 BatP4_BMS_CellVoltageM4: 8 BMS
 SG_ P4_CellVoltage17 : 7|13@0+ (0.001,0) [0|5] "V" VCU
 SG_ P4_CellVoltage18 : 10|13@0+ (0.001,0) [0|5] "V" VCU
 SG_ P4_CellVoltage19 : 29|13@0+ (0.001,0) [0|5] "V" VCU
 SG_ P4_CellVoltage20 : 32|13@0+ (0.001,0) [0|5] "V" VCU
 SG_ P4_BalSwCell17 : 51|1@0+ (1,0) [0|1] "" VCU
 SG_ P4_BalSwCell18 : 50|1@0+ (1,0) [0|1] "" VCU
 SG_ P4_BalSwCell19 : 49|1@0+ (1,0) [0|1] "" VCU
 SG_ P4_BalSwCell20 : 48|1@0+ (1,0) [0|1] "" VCU

BO_ 2554724420 BatP4_BMS_CellVoltageM5: 8 BMS
 SG_ P4_CellVoltage21 : 7|13@0+ (0.001,0) [0|5] "V" VCU
 SG_ P4_CellVoltage22 : 10|13@0+ (0.001,0) [0|5] "V" VCU
 SG_ P4_CellVoltage23 : 29|13@0+ (0.001,0) [0|5] "V" VCU
 SG_ P4_CellVoltage24 : 32|13@0+ (0.001,0) [0|5] "V" VCU
 SG_ P4_BalSwCell21 : 51|1@0+ (1,0) [0|1] "" VCU
 SG_ P4_BalSwCell22 : 50|1@0+ (1,0) [0|1] "" VCU
 SG_ P4_BalSwCell23 : 49|1@0+ (1,0) [0|1] "" VCU
 SG_ P4_BalSwCell24 : 48|1@0+ (1,0) [0|1] "" VCU

BO_ 2554789956 BatP4_BMS_CellVoltageM6: 8 BMS
 SG_ P4_CellVoltage25 : 7|13@0+ (0.001,0) [0|5] "V" VCU
 SG_ P4_CellVoltage26 : 10|13@0+ (0.001,0) [0|5] "V" VCU
 SG_ P4_CellVoltage27 : 29|13@0+ (0.001,0) [0|5] "V" VCU
 SG_ P4_CellVoltage28 : 32|13@0+ (0.001,0) [0|5] "V" VCU
 SG_ P4_BalSwCell25 : 51|1@0+ (1,0) [0|1] "" VCU
 SG_ P4_BalSwCell26 : 50|1@0+ (1,0) [0|1] "" VCU
 SG_ P4_BalSwCell27 : 49|1@0+ (1,0) [0|1] "" VCU
 SG_ P4_BalSwCell28 : 48|1@0+ (1,0) [0|1] "" VCU

BO_ 2554855492 BatP4_BMS_CellVoltageM7: 8 BMS
 SG_ P4_CellVoltage29 : 7|13@0+ (0.001,0) [0|5] "V" VCU
 SG_ P4_CellVoltage30 : 10|13@0+ (0.001,0) [0|5] "V" VCU
 SG_ P4_CellVoltage31 : 29|13@0+ (0.001,0) [0|5] "V" VCU
 SG_ P4_CellVoltage32 : 32|13@0+ (0.001,0) [0|5] "V" VCU
 SG_ P4_BalSwCell29 : 51|1@0+ (1,0) [0|1] "" VCU
 SG_ P4_BalSwCell30 : 50|1@0+ (1,0) [0|1] "" VCU
 SG_ P4_BalSwCell31 : 49|1@0+ (1,0) [0|1] "" VCU
 SG_ P4_BalSwCell32 : 48|1@0+ (1,0) [0|1] "" VCU

BO_ 2554921028 BatP4_BMS_CellVoltageM8: 8 BMS
 SG_ P4_CellVoltage33 : 7|13@0+ (0.001,0) [0|5] "V" VCU
 SG_ P4_CellVoltage34 : 10|13@0+ (0.001,0) [0|5] "V" VCU
 SG_ P4_CellVoltage35 : 29|13@0+ (0.001,0) [0|5] "V" VCU
 SG_ P4_CellVoltage36 : 32|13@0+ (0.001,0) [0|5] "V" VCU
 SG_ P4_BalSwCell33 : 51|1@0+ (1,0) [0|1] "" VCU
 SG_ P4_BalSwCell34 : 50|1@0+ (1,0) [0|1] "" VCU
 SG_ P4_BalSwCell35 : 49|1@0+ (1,0) [0|1] "" VCU
 SG_ P4_BalSwCell36 : 48|1@0+ (1,0) [0|1] "" VCU

BO_ 2554986564 BatP4_BMS_CellVoltageM9: 8 BMS
 SG_ P4_CellVoltage37 : 7|13@0+ (0.001,0) [0|5] "V" VCU
 SG_ P4_CellVoltage38 : 10|13@0+ (0.001,0) [0|5] "V" VCU
 SG_ P4_CellVoltage39 : 29|13@0+ (0.001,0) [0|5] "V" VCU
 SG_ P4_CellVoltage40 : 32|13@0+ (0.001,0) [0|5] "V" VCU
 SG_ P4_BalSwCell37 : 51|1@0+ (1,0) [0|1] "" VCU
 SG_ P4_BalSwCell38 : 50|1@0+ (1,0) [0|1] "" VCU
 SG_ P4_BalSwCell39 : 49|1@0+ (1,0) [0|1] "" VCU
 SG_ P4_BalSwCell40 : 48|1@0+ (1,0) [0|1] "" VCU

BO_ 2555052100 BatP4_BMS_CellVoltageM10: 8 BMS
 SG_ P4_CellVoltage41 : 7|13@0+ (0.001,0) [0|5] "V" VCU
 SG_ P4_CellVoltage42 : 10|13@0+ (0.001,0) [0|5] "V" VCU
 SG_ P4_CellVoltage43 : 29|13@0+ (0.001,0) [0|5] "V" VCU
 SG_ P4_CellVoltage44 : 32|13@0+ (0.001,0) [0|5] "V" VCU
 SG_ P4_BalSwCell41 : 51|1@0+ (1,0) [0|1] "" VCU
 SG_ P4_BalSwCell42 : 50|1@0+ (1,0) [0|1] "" VCU
 SG_ P4_BalSwCell43 : 49|1@0+ (1,0) [0|1] "" VCU
 SG_ P4_BalSwCell44 : 48|1@0+ (1,0) [0|1] "" VCU

BO_ 2555117636 BatP4_BMS_CellVoltageM11: 8 BMS
 SG_ P4_CellVoltage45 : 7|13@0+ (0.001,0) [0|5] "V" VCU
 SG_ P4_CellVoltage46 : 10|13@0+ (0.001,0) [0|5] "V" VCU
 SG_ P4_CellVoltage47 : 29|13@0+ (0.001,0) [0|5] "V" VCU
 SG_ P4_CellVoltage48 : 32|13@0+ (0.001,0) [0|5] "V" VCU
 SG_ P4_BalSwCell45 : 51|1@0+ (1,0) [0|1] "" VCU
 SG_ P4_BalSwCell46 : 50|1@0+ (1,0) [0|1] "" VCU
 SG_ P4_BalSwCell47 : 49|1@0+ (1,0) [0|1] "" VCU
 SG_ P4_BalSwCell48 : 48|1@0+ (1,0) [0|1] "" VCU

BO_ 2555183172 BatP4_BMS_CellVoltageM12: 8 BMS
 SG_ P4_CellVoltage49 : 7|13@0+ (0.001,0) [0|5] "V" VCU
 SG_ P4_CellVoltage50 : 10|13@0+ (0.001,0) [0|5] "V" VCU
 SG_ P4_CellVoltage51 : 29|13@0+ (0.001,0) [0|5] "V" VCU
 SG_ P4_CellVoltage52 : 32|13@0+ (0.001,0) [0|5] "V" VCU
 SG_ P4_BalSwCell49 : 51|1@0+ (1,0) [0|1] "" VCU
 SG_ P4_BalSwCell50 : 50|1@0+ (1,0) [0|1] "" VCU
 SG_ P4_BalSwCell51 : 49|1@0+ (1,0) [0|1] "" VCU
 SG_ P4_BalSwCell52 : 48|1@0+ (1,0) [0|1] "" VCU

BO_ 2555248708 BatP4_BMS_CellVoltageM13: 8 BMS
 SG_ P4_CellVoltage53 : 7|13@0+ (0.001,0) [0|5] "V" VCU
 SG_ P4_CellVoltage54 : 10|13@0+ (0.001,0) [0|5] "V" VCU
 SG_ P4_CellVoltage55 : 29|13@0+ (0.001,0) [0|5] "V" VCU
 SG_ P4_CellVoltage56 : 32|13@0+ (0.001,0) [0|5] "V" VCU
 SG_ P4_BalSwCell53 : 51|1@0+ (1,0) [0|1] "" VCU
 SG_ P4_BalSwCell54 : 50|1@0+ (1,0) [0|1] "" VCU
 SG_ P4_BalSwCell55 : 49|1@0+ (1,0) [0|1] "" VCU
 SG_ P4_BalSwCell56 : 48|1@0+ (1,0) [0|1] "" VCU

BO_ 2555314244 BatP4_BMS_CellVoltageM14: 8 BMS
 SG_ P4_CellVoltage57 : 7|13@0+ (0.001,0) [0|5] "V" VCU
 SG_ P4_CellVoltage58 : 10|13@0+ (0.001,0) [0|5] "V" VCU
 SG_ P4_CellVoltage59 : 29|13@0+ (0.001,0) [0|5] "V" VCU
 SG_ P4_CellVoltage60 : 32|13@0+ (0.001,0) [0|5] "V" VCU
 SG_ P4_BalSwCell57 : 51|1@0+ (1,0) [0|1] "" VCU
 SG_ P4_BalSwCell58 : 50|1@0+ (1,0) [0|1] "" VCU
 SG_ P4_BalSwCell59 : 49|1@0+ (1,0) [0|1] "" VCU
 SG_ P4_BalSwCell60 : 48|1@0+ (1,0) [0|1] "" VCU

BO_ 2555379780 BatP4_BMS_CellVoltageM15: 8 BMS
 SG_ P4_CellVoltage61 : 7|13@0+ (0.001,0) [0|5] "V" VCU
 SG_ P4_CellVoltage62 : 10|13@0+ (0.001,0) [0|5] "V" VCU
 SG_ P4_CellVoltage63 : 29|13@0+ (0.001,0) [0|5] "V" VCU
 SG_ P4_CellVoltage64 : 32|13@0+ (0.001,0) [0|5] "V" VCU
 SG_ P4_BalSwCell61 : 51|1@0+ (1,0) [0|1] "" VCU
 SG_ P4_BalSwCell62 : 50|1@0+ (1,0) [0|1] "" VCU
 SG_ P4_BalSwCell63 : 49|1@0+ (1,0) [0|1] "" VCU
 SG_ P4_BalSwCell64 : 48|1@0+ (1,0) [0|1] "" VCU

BO_ 2555445316 BatP4_BMS_CellVoltageM16: 8 BMS
 SG_ P4_CellVoltage65 : 7|13@0+ (0.001,0) [0|5] "V" VCU
 SG_ P4_CellVoltage66 : 10|13@0+ (0.001,0) [0|5] "V" VCU
 SG_ P4_CellVoltage67 : 29|13@0+ (0.001,0) [0|5] "V" VCU
 SG_ P4_CellVoltage68 : 32|13@0+ (0.001,0) [0|5] "V" VCU
 SG_ P4_BalSwCell65 : 51|1@0+ (1,0) [0|1] "" VCU
 SG_ P4_BalSwCell66 : 50|1@0+ (1,0) [0|1] "" VCU
 SG_ P4_BalSwCell67 : 49|1@0+ (1,0) [0|1] "" VCU
 SG_ P4_BalSwCell68 : 48|1@0+ (1,0) [0|1] "" VCU

BO_ 2555510852 BatP4_BMS_CellVoltageM17: 8 BMS
 SG_ P4_CellVoltage69 : 7|13@0+ (0.001,0) [0|5] "V" VCU
 SG_ P4_CellVoltage70 : 10|13@0+ (0.001,0) [0|5] "V" VCU
 SG_ P4_CellVoltage71 : 29|13@0+ (0.001,0) [0|5] "V" VCU
 SG_ P4_CellVoltage72 : 32|13@0+ (0.001,0) [0|5] "V" VCU
 SG_ P4_BalSwCell69 : 51|1@0+ (1,0) [0|1] "" VCU
 SG_ P4_BalSwCell70 : 50|1@0+ (1,0) [0|1] "" VCU
 SG_ P4_BalSwCell71 : 49|1@0+ (1,0) [0|1] "" VCU
 SG_ P4_BalSwCell72 : 48|1@0+ (1,0) [0|1] "" VCU

BO_ 2555576388 BatP4_BMS_CellVoltageM18: 8 BMS
 SG_ P4_CellVoltage73 : 7|13@0+ (0.001,0) [0|5] "V" VCU
 SG_ P4_CellVoltage74 : 10|13@0+ (0.001,0) [0|5] "V" VCU
 SG_ P4_CellVoltage75 : 29|13@0+ (0.001,0) [0|5] "V" VCU
 SG_ P4_CellVoltage76 : 32|13@0+ (0.001,0) [0|5] "V" VCU
 SG_ P4_BalSwCell73 : 51|1@0+ (1,0) [0|1] "" VCU
 SG_ P4_BalSwCell74 : 50|1@0+ (1,0) [0|1] "" VCU
 SG_ P4_BalSwCell75 : 49|1@0+ (1,0) [0|1] "" VCU
 SG_ P4_BalSwCell76 : 48|1@0+ (1,0) [0|1] "" VCU

BO_ 2555641924 BatP4_BMS_CellVoltageM19: 8 BMS
 SG_ P4_CellVoltage77 : 7|13@0+ (0.001,0) [0|5] "V" VCU
 SG_ P4_CellVoltage78 : 10|13@0+ (0.001,0) [0|5] "V" VCU
 SG_ P4_CellVoltage79 : 29|13@0+ (0.001,0) [0|5] "V" VCU
 SG_ P4_CellVoltage80 : 32|13@0+ (0.001,0) [0|5] "V" VCU
 SG_ P4_BalSwCell77 : 51|1@0+ (1,0) [0|1] "" VCU
 SG_ P4_BalSwCell78 : 50|1@0+ (1,0) [0|1] "" VCU
 SG_ P4_BalSwCell79 : 49|1@0+ (1,0) [0|1] "" VCU
 SG_ P4_BalSwCell80 : 48|1@0+ (1,0) [0|1] "" VCU

BO_ 2555707460 BatP4_BMS_CellVoltageM20: 8 BMS
 SG_ P4_CellVoltage81 : 7|13@0+ (0.001,0) [0|5] "V" VCU
 SG_ P4_CellVoltage82 : 10|13@0+ (0.001,0) [0|5] "V" VCU
 SG_ P4_CellVoltage83 : 29|13@0+ (0.001,0) [0|5] "V" VCU
 SG_ P4_CellVoltage84 : 32|13@0+ (0.001,0) [0|5] "V" VCU
 SG_ P4_BalSwCell81 : 51|1@0+ (1,0) [0|1] "" VCU
 SG_ P4_BalSwCell82 : 50|1@0+ (1,0) [0|1] "" VCU
 SG_ P4_BalSwCell83 : 49|1@0+ (1,0) [0|1] "" VCU
 SG_ P4_BalSwCell84 : 48|1@0+ (1,0) [0|1] "" VCU

BO_ 2555772996 BatP4_BMS_CellVoltageM21: 8 BMS
 SG_ P4_CellVoltage85 : 7|13@0+ (0.001,0) [0|5] "V" VCU
 SG_ P4_CellVoltage86 : 10|13@0+ (0.001,0) [0|5] "V" VCU
 SG_ P4_CellVoltage87 : 29|13@0+ (0.001,0) [0|5] "V" VCU
 SG_ P4_CellVoltage88 : 32|13@0+ (0.001,0) [0|5] "V" VCU
 SG_ P4_BalSwCell85 : 51|1@0+ (1,0) [0|1] "" VCU
 SG_ P4_BalSwCell86 : 50|1@0+ (1,0) [0|1] "" VCU
 SG_ P4_BalSwCell87 : 49|1@0+ (1,0) [0|1] "" VCU
 SG_ P4_BalSwCell88 : 48|1@0+ (1,0) [0|1] "" VCU

BO_ 2555838532 BatP4_BMS_CellVoltageM22: 8 BMS
 SG_ P4_CellVoltage89 : 7|13@0+ (0.001,0) [0|5] "V" VCU
 SG_ P4_CellVoltage90 : 10|13@0+ (0.001,0) [0|5] "V" VCU
 SG_ P4_CellVoltage91 : 29|13@0+ (0.001,0) [0|5] "V" VCU
 SG_ P4_CellVoltage92 : 32|13@0+ (0.001,0) [0|5] "V" VCU
 SG_ P4_BalSwCell89 : 51|1@0+ (1,0) [0|1] "" VCU
 SG_ P4_BalSwCell90 : 50|1@0+ (1,0) [0|1] "" VCU
 SG_ P4_BalSwCell91 : 49|1@0+ (1,0) [0|1] "" VCU
 SG_ P4_BalSwCell92 : 48|1@0+ (1,0) [0|1] "" VCU

BO_ 2555904068 BatP4_BMS_CellVoltageM23: 8 BMS
 SG_ P4_CellVoltage93 : 7|13@0+ (0.001,0) [0|5] "V" VCU
 SG_ P4_CellVoltage94 : 10|13@0+ (0.001,0) [0|5] "V" VCU
 SG_ P4_CellVoltage95 : 29|13@0+ (0.001,0) [0|5] "V" VCU
 SG_ P4_CellVoltage96 : 32|13@0+ (0.001,0) [0|5] "V" VCU
 SG_ P4_BalSwCell93 : 51|1@0+ (1,0) [0|1] "" VCU
 SG_ P4_BalSwCell94 : 50|1@0+ (1,0) [0|1] "" VCU
 SG_ P4_BalSwCell95 : 49|1@0+ (1,0) [0|1] "" VCU
 SG_ P4_BalSwCell96 : 48|1@0+ (1,0) [0|1] "" VCU

BO_ 2555969604 BatP4_BMS_CellVoltageM24: 8 BMS
 SG_ P4_CellVoltage97 : 7|13@0+ (0.001,0) [0|5] "V" VCU
 SG_ P4_CellVoltage98 : 10|13@0+ (0.001,0) [0|5] "V" VCU
 SG_ P4_CellVoltage99 : 29|13@0+ (0.001,0) [0|5] "V" VCU
 SG_ P4_CellVoltage100 : 32|13@0+ (0.001,0) [0|5] "V" VCU
 SG_ P4_BalSwCell97 : 51|1@0+ (1,0) [0|1] "" VCU
 SG_ P4_BalSwCell98 : 50|1@0+ (1,0) [0|1] "" VCU
 SG_ P4_BalSwCell99 : 49|1@0+ (1,0) [0|1] "" VCU
 SG_ P4_BalSwCell100 : 48|1@0+ (1,0) [0|1] "" VCU

BO_ 2556035140 BatP4_BMS_CellVoltageM25: 8 BMS
 SG_ P4_CellVoltage101 : 7|13@0+ (0.001,0) [0|5] "V" VCU
 SG_ P4_CellVoltage102 : 10|13@0+ (0.001,0) [0|5] "V" VCU
 SG_ P4_CellVoltage103 : 29|13@0+ (0.001,0) [0|5] "V" VCU
 SG_ P4_CellVoltage104 : 32|13@0+ (0.001,0) [0|5] "V" VCU
 SG_ P4_BalSwCell101 : 51|1@0+ (1,0) [0|1] "" VCU
 SG_ P4_BalSwCell102 : 50|1@0+ (1,0) [0|1] "" VCU
 SG_ P4_BalSwCell103 : 49|1@0+ (1,0) [0|1] "" VCU
 SG_ P4_BalSwCell104 : 48|1@0+ (1,0) [0|1] "" VCU

BO_ 2556100676 BatP4_BMS_CellVoltageM26: 8 BMS
 SG_ P4_CellVoltage105 : 7|13@0+ (0.001,0) [0|5] "V" VCU
 SG_ P4_CellVoltage106 : 10|13@0+ (0.001,0) [0|5] "V" VCU
 SG_ P4_CellVoltage107 : 29|13@0+ (0.001,0) [0|5] "V" VCU
 SG_ P4_CellVoltage108 : 32|13@0+ (0.001,0) [0|5] "V" VCU
 SG_ P4_BalSwCell105 : 51|1@0+ (1,0) [0|1] "" VCU
 SG_ P4_BalSwCell106 : 50|1@0+ (1,0) [0|1] "" VCU
 SG_ P4_BalSwCell107 : 49|1@0+ (1,0) [0|1] "" VCU
 SG_ P4_BalSwCell108 : 48|1@0+ (1,0) [0|1] "" VCU

BO_ 2556166212 BatP4_BMS_CellVoltageM27: 8 BMS
 SG_ P4_CellVoltage109 : 7|13@0+ (0.001,0) [0|5] "V" VCU
 SG_ P4_CellVoltage110 : 10|13@0+ (0.001,0) [0|5] "V" VCU
 SG_ P4_CellVoltage111 : 29|13@0+ (0.001,0) [0|5] "V" VCU
 SG_ P4_CellVoltage112 : 32|13@0+ (0.001,0) [0|5] "V" VCU
 SG_ P4_BalSwCell109 : 51|1@0+ (1,0) [0|1] "" VCU
 SG_ P4_BalSwCell110 : 50|1@0+ (1,0) [0|1] "" VCU
 SG_ P4_BalSwCell111 : 49|1@0+ (1,0) [0|1] "" VCU
 SG_ P4_BalSwCell112 : 48|1@0+ (1,0) [0|1] "" VCU

BO_ 2556231748 BatP4_BMS_CellVoltageM28: 8 BMS
 SG_ P4_CellVoltage113 : 7|13@0+ (0.001,0) [0|5] "V" VCU
 SG_ P4_CellVoltage114 : 10|13@0+ (0.001,0) [0|5] "V" VCU
 SG_ P4_CellVoltage115 : 29|13@0+ (0.001,0) [0|5] "V" VCU
 SG_ P4_CellVoltage116 : 32|13@0+ (0.001,0) [0|5] "V" VCU
 SG_ P4_BalSwCell113 : 51|1@0+ (1,0) [0|1] "" VCU
 SG_ P4_BalSwCell114 : 50|1@0+ (1,0) [0|1] "" VCU
 SG_ P4_BalSwCell115 : 49|1@0+ (1,0) [0|1] "" VCU
 SG_ P4_BalSwCell116 : 48|1@0+ (1,0) [0|1] "" VCU

BO_ 2556297284 BatP4_BMS_CellVoltageM29: 8 BMS
 SG_ P4_CellVoltage117 : 7|13@0+ (0.001,0) [0|5] "V" VCU
 SG_ P4_CellVoltage118 : 10|13@0+ (0.001,0) [0|5] "V" VCU
 SG_ P4_CellVoltage119 : 29|13@0+ (0.001,0) [0|5] "V" VCU
 SG_ P4_CellVoltage120 : 32|13@0+ (0.001,0) [0|5] "V" VCU
 SG_ P4_BalSwCell117 : 51|1@0+ (1,0) [0|1] "" VCU
 SG_ P4_BalSwCell118 : 50|1@0+ (1,0) [0|1] "" VCU
 SG_ P4_BalSwCell119 : 49|1@0+ (1,0) [0|1] "" VCU
 SG_ P4_BalSwCell120 : 48|1@0+ (1,0) [0|1] "" VCU

BO_ 2556362820 BatP4_BMS_CellVoltageM30: 8 BMS
 SG_ P4_CellVoltage121 : 7|13@0+ (0.001,0) [0|5] "V" VCU
 SG_ P4_CellVoltage122 : 10|13@0+ (0.001,0) [0|5] "V" VCU
 SG_ P4_CellVoltage123 : 29|13@0+ (0.001,0) [0|5] "V" VCU
 SG_ P4_CellVoltage124 : 32|13@0+ (0.001,0) [0|5] "V" VCU
 SG_ P4_BalSwCell121 : 51|1@0+ (1,0) [0|1] "" VCU
 SG_ P4_BalSwCell122 : 50|1@0+ (1,0) [0|1] "" VCU
 SG_ P4_BalSwCell123 : 49|1@0+ (1,0) [0|1] "" VCU
 SG_ P4_BalSwCell124 : 48|1@0+ (1,0) [0|1] "" VCU

BO_ 2556428356 BatP4_BMS_CellVoltageM31: 8 BMS
 SG_ P4_CellVoltage125 : 7|13@0+ (0.001,0) [0|5] "V" VCU
 SG_ P4_CellVoltage126 : 10|13@0+ (0.001,0) [0|5] "V" VCU
 SG_ P4_CellVoltage127 : 29|13@0+ (0.001,0) [0|5] "V" VCU
 SG_ P4_CellVoltage128 : 32|13@0+ (0.001,0) [0|5] "V" VCU
 SG_ P4_BalSwCell125 : 51|1@0+ (1,0) [0|1] "" VCU
 SG_ P4_BalSwCell126 : 50|1@0+ (1,0) [0|1] "" VCU
 SG_ P4_BalSwCell127 : 49|1@0+ (1,0) [0|1] "" VCU
 SG_ P4_BalSwCell128 : 48|1@0+ (1,0) [0|1] "" VCU

BO_ 2556493892 BatP4_BMS_CellVoltageM32: 8 BMS
 SG_ P4_CellVoltage129 : 7|13@0+ (0.001,0) [0|5] "V" VCU
 SG_ P4_CellVoltage130 : 10|13@0+ (0.001,0) [0|5] "V" VCU
 SG_ P4_CellVoltage131 : 29|13@0+ (0.001,0) [0|5] "V" VCU
 SG_ P4_CellVoltage132 : 32|13@0+ (0.001,0) [0|5] "V" VCU
 SG_ P4_BalSwCell129 : 51|1@0+ (1,0) [0|1] "" VCU
 SG_ P4_BalSwCell130 : 50|1@0+ (1,0) [0|1] "" VCU
 SG_ P4_BalSwCell131 : 49|1@0+ (1,0) [0|1] "" VCU
 SG_ P4_BalSwCell132 : 48|1@0+ (1,0) [0|1] "" VCU

BO_ 2556559428 BatP4_BMS_CellVoltageM33: 8 BMS
 SG_ P4_CellVoltage133 : 7|13@0+ (0.001,0) [0|5] "V" VCU
 SG_ P4_CellVoltage134 : 10|13@0+ (0.001,0) [0|5] "V" VCU
 SG_ P4_CellVoltage135 : 29|13@0+ (0.001,0) [0|5] "V" VCU
 SG_ P4_CellVoltage136 : 32|13@0+ (0.001,0) [0|5] "V" VCU
 SG_ P4_BalSwCell133 : 51|1@0+ (1,0) [0|1] "" VCU
 SG_ P4_BalSwCell134 : 50|1@0+ (1,0) [0|1] "" VCU
 SG_ P4_BalSwCell135 : 49|1@0+ (1,0) [0|1] "" VCU
 SG_ P4_BalSwCell136 : 48|1@0+ (1,0) [0|1] "" VCU

BO_ 2556624964 BatP4_BMS_CellVoltageM34: 8 BMS
 SG_ P4_CellVoltage137 : 7|13@0+ (0.001,0) [0|5] "V" VCU
 SG_ P4_CellVoltage138 : 10|13@0+ (0.001,0) [0|5] "V" VCU
 SG_ P4_CellVoltage139 : 29|13@0+ (0.001,0) [0|5] "V" VCU
 SG_ P4_CellVoltage140 : 32|13@0+ (0.001,0) [0|5] "V" VCU
 SG_ P4_BalSwCell137 : 51|1@0+ (1,0) [0|1] "" VCU
 SG_ P4_BalSwCell138 : 50|1@0+ (1,0) [0|1] "" VCU
 SG_ P4_BalSwCell139 : 49|1@0+ (1,0) [0|1] "" VCU
 SG_ P4_BalSwCell140 : 48|1@0+ (1,0) [0|1] "" VCU

BO_ 2556690500 BatP4_BMS_CellVoltageM35: 8 BMS
 SG_ P4_CellVoltage141 : 7|13@0+ (0.001,0) [0|5] "V" VCU
 SG_ P4_CellVoltage142 : 10|13@0+ (0.001,0) [0|5] "V" VCU
 SG_ P4_CellVoltage143 : 29|13@0+ (0.001,0) [0|5] "V" VCU
 SG_ P4_CellVoltage144 : 32|13@0+ (0.001,0) [0|5] "V" VCU
 SG_ P4_BalSwCell141 : 51|1@0+ (1,0) [0|1] "" VCU
 SG_ P4_BalSwCell142 : 50|1@0+ (1,0) [0|1] "" VCU
 SG_ P4_BalSwCell143 : 49|1@0+ (1,0) [0|1] "" VCU
 SG_ P4_BalSwCell144 : 48|1@0+ (1,0) [0|1] "" VCU

BO_ 2556756036 BatP4_BMS_CellVoltageM36: 8 BMS
 SG_ P4_CellVoltage145 : 7|13@0+ (0.001,0) [0|5] "V" VCU
 SG_ P4_CellVoltage146 : 10|13@0+ (0.001,0) [0|5] "V" VCU
 SG_ P4_CellVoltage147 : 29|13@0+ (0.001,0) [0|5] "V" VCU
 SG_ P4_CellVoltage148 : 32|13@0+ (0.001,0) [0|5] "V" VCU
 SG_ P4_BalSwCell145 : 51|1@0+ (1,0) [0|1] "" VCU
 SG_ P4_BalSwCell146 : 50|1@0+ (1,0) [0|1] "" VCU
 SG_ P4_BalSwCell147 : 49|1@0+ (1,0) [0|1] "" VCU
 SG_ P4_BalSwCell148 : 48|1@0+ (1,0) [0|1] "" VCU

BO_ 2556821572 BatP4_BMS_CellVoltageM37: 8 BMS
 SG_ P4_CellVoltage149 : 7|13@0+ (0.001,0) [0|5] "V" VCU
 SG_ P4_CellVoltage150 : 10|13@0+ (0.001,0) [0|5] "V" VCU
 SG_ P4_CellVoltage151 : 29|13@0+ (0.001,0) [0|5] "V" VCU
 SG_ P4_CellVoltage152 : 32|13@0+ (0.001,0) [0|5] "V" VCU
 SG_ P4_BalSwCell149 : 51|1@0+ (1,0) [0|1] "" VCU
 SG_ P4_BalSwCell150 : 50|1@0+ (1,0) [0|1] "" VCU
 SG_ P4_BalSwCell151 : 49|1@0+ (1,0) [0|1] "" VCU
 SG_ P4_BalSwCell152 : 48|1@0+ (1,0) [0|1] "" VCU

BO_ 2556887108 BatP4_BMS_CellVoltageM38: 8 BMS
 SG_ P4_CellVoltage153 : 7|13@0+ (0.001,0) [0|5] "V" VCU
 SG_ P4_CellVoltage154 : 10|13@0+ (0.001,0) [0|5] "V" VCU
 SG_ P4_CellVoltage155 : 29|13@0+ (0.001,0) [0|5] "V" VCU
 SG_ P4_CellVoltage156 : 32|13@0+ (0.001,0) [0|5] "V" VCU
 SG_ P4_BalSwCell153 : 51|1@0+ (1,0) [0|1] "" VCU
 SG_ P4_BalSwCell154 : 50|1@0+ (1,0) [0|1] "" VCU
 SG_ P4_BalSwCell155 : 49|1@0+ (1,0) [0|1] "" VCU
 SG_ P4_BalSwCell156 : 48|1@0+ (1,0) [0|1] "" VCU

BO_ 2556952644 BatP4_BMS_CellVoltageM39: 8 BMS
 SG_ P4_CellVoltage157 : 7|13@0+ (0.001,0) [0|5] "V" VCU
 SG_ P4_CellVoltage158 : 10|13@0+ (0.001,0) [0|5] "V" VCU
 SG_ P4_CellVoltage159 : 29|13@0+ (0.001,0) [0|5] "V" VCU
 SG_ P4_CellVoltage160 : 32|13@0+ (0.001,0) [0|5] "V" VCU
 SG_ P4_BalSwCell157 : 51|1@0+ (1,0) [0|1] "" VCU
 SG_ P4_BalSwCell158 : 50|1@0+ (1,0) [0|1] "" VCU
 SG_ P4_BalSwCell159 : 49|1@0+ (1,0) [0|1] "" VCU
 SG_ P4_BalSwCell160 : 48|1@0+ (1,0) [0|1] "" VCU

BO_ 2557018180 BatP4_BMS_CellVoltageM40: 8 BMS
 SG_ P4_CellVoltage161 : 7|13@0+ (0.001,0) [0|5] "V" VCU
 SG_ P4_CellVoltage162 : 10|13@0+ (0.001,0) [0|5] "V" VCU
 SG_ P4_CellVoltage163 : 29|13@0+ (0.001,0) [0|5] "V" VCU
 SG_ P4_CellVoltage164 : 32|13@0+ (0.001,0) [0|5] "V" VCU
 SG_ P4_BalSwCell161 : 51|1@0+ (1,0) [0|1] "" VCU
 SG_ P4_BalSwCell162 : 50|1@0+ (1,0) [0|1] "" VCU
 SG_ P4_BalSwCell163 : 49|1@0+ (1,0) [0|1] "" VCU
 SG_ P4_BalSwCell164 : 48|1@0+ (1,0) [0|1] "" VCU

BO_ 2557083716 BatP4_BMS_CellVoltageM41: 8 BMS
 SG_ P4_CellVoltage165 : 7|13@0+ (0.001,0) [0|5] "V" VCU
 SG_ P4_CellVoltage166 : 10|13@0+ (0.001,0) [0|5] "V" VCU
 SG_ P4_CellVoltage167 : 29|13@0+ (0.001,0) [0|5] "V" VCU
 SG_ P4_CellVoltage168 : 32|13@0+ (0.001,0) [0|5] "V" VCU
 SG_ P4_BalSwCell165 : 51|1@0+ (1,0) [0|1] "" VCU
 SG_ P4_BalSwCell166 : 50|1@0+ (1,0) [0|1] "" VCU
 SG_ P4_BalSwCell167 : 49|1@0+ (1,0) [0|1] "" VCU
 SG_ P4_BalSwCell168 : 48|1@0+ (1,0) [0|1] "" VCU

BO_ 2557149252 BatP4_BMS_CellVoltageM42: 8 BMS
 SG_ P4_CellVoltage169 : 7|13@0+ (0.001,0) [0|5] "V" VCU
 SG_ P4_CellVoltage170 : 10|13@0+ (0.001,0) [0|5] "V" VCU
 SG_ P4_CellVoltage171 : 29|13@0+ (0.001,0) [0|5] "V" VCU
 SG_ P4_CellVoltage172 : 32|13@0+ (0.001,0) [0|5] "V" VCU
 SG_ P4_BalSwCell169 : 51|1@0+ (1,0) [0|1] "" VCU
 SG_ P4_BalSwCell170 : 50|1@0+ (1,0) [0|1] "" VCU
 SG_ P4_BalSwCell171 : 49|1@0+ (1,0) [0|1] "" VCU
 SG_ P4_BalSwCell172 : 48|1@0+ (1,0) [0|1] "" VCU

BO_ 2557214788 BatP4_BMS_CellVoltageM43: 8 BMS
 SG_ P4_CellVoltage173 : 7|13@0+ (0.001,0) [0|5] "V" VCU
 SG_ P4_CellVoltage174 : 10|13@0+ (0.001,0) [0|5] "V" VCU
 SG_ P4_CellVoltage175 : 29|13@0+ (0.001,0) [0|5] "V" VCU
 SG_ P4_CellVoltage176 : 32|13@0+ (0.001,0) [0|5] "V" VCU
 SG_ P4_BalSwCell173 : 51|1@0+ (1,0) [0|1] "" VCU
 SG_ P4_BalSwCell174 : 50|1@0+ (1,0) [0|1] "" VCU
 SG_ P4_BalSwCell175 : 49|1@0+ (1,0) [0|1] "" VCU
 SG_ P4_BalSwCell176 : 48|1@0+ (1,0) [0|1] "" VCU

BO_ 2557280324 BatP4_BMS_CellVoltageM44: 8 BMS
 SG_ P4_CellVoltage177 : 7|13@0+ (0.001,0) [0|5] "V" VCU
 SG_ P4_CellVoltage178 : 10|13@0+ (0.001,0) [0|5] "V" VCU
 SG_ P4_CellVoltage179 : 29|13@0+ (0.001,0) [0|5] "V" VCU
 SG_ P4_CellVoltage180 : 32|13@0+ (0.001,0) [0|5] "V" VCU
 SG_ P4_BalSwCell177 : 51|1@0+ (1,0) [0|1] "" VCU
 SG_ P4_BalSwCell178 : 50|1@0+ (1,0) [0|1] "" VCU
 SG_ P4_BalSwCell179 : 49|1@0+ (1,0) [0|1] "" VCU
 SG_ P4_BalSwCell180 : 48|1@0+ (1,0) [0|1] "" VCU

BO_ 2557345860 BatP4_BMS_CellVoltageM45: 8 BMS
 SG_ P4_CellVoltage181 : 7|13@0+ (0.001,0) [0|5] "V" VCU
 SG_ P4_CellVoltage182 : 10|13@0+ (0.001,0) [0|5] "V" VCU
 SG_ P4_CellVoltage183 : 29|13@0+ (0.001,0) [0|5] "V" VCU
 SG_ P4_CellVoltage184 : 32|13@0+ (0.001,0) [0|5] "V" VCU
 SG_ P4_BalSwCell181 : 51|1@0+ (1,0) [0|1] "" VCU
 SG_ P4_BalSwCell182 : 50|1@0+ (1,0) [0|1] "" VCU
 SG_ P4_BalSwCell183 : 49|1@0+ (1,0) [0|1] "" VCU
 SG_ P4_BalSwCell184 : 48|1@0+ (1,0) [0|1] "" VCU

BO_ 2557411396 BatP4_BMS_CellVoltageM46: 8 BMS
 SG_ P4_CellVoltage185 : 7|13@0+ (0.001,0) [0|5] "V" VCU
 SG_ P4_CellVoltage186 : 10|13@0+ (0.001,0) [0|5] "V" VCU
 SG_ P4_CellVoltage187 : 29|13@0+ (0.001,0) [0|5] "V" VCU
 SG_ P4_CellVoltage188 : 32|13@0+ (0.001,0) [0|5] "V" VCU
 SG_ P4_BalSwCell185 : 51|1@0+ (1,0) [0|1] "" VCU
 SG_ P4_BalSwCell186 : 50|1@0+ (1,0) [0|1] "" VCU
 SG_ P4_BalSwCell187 : 49|1@0+ (1,0) [0|1] "" VCU
 SG_ P4_BalSwCell188 : 48|1@0+ (1,0) [0|1] "" VCU

BO_ 2557476932 BatP4_BMS_CellVoltageM47: 8 BMS
 SG_ P4_CellVoltage189 : 7|13@0+ (0.001,0) [0|5] "V" VCU
 SG_ P4_CellVoltage190 : 10|13@0+ (0.001,0) [0|5] "V" VCU
 SG_ P4_CellVoltage191 : 29|13@0+ (0.001,0) [0|5] "V" VCU
 SG_ P4_CellVoltage192 : 32|13@0+ (0.001,0) [0|5] "V" VCU
 SG_ P4_BalSwCell189 : 51|1@0+ (1,0) [0|1] "" VCU
 SG_ P4_BalSwCell190 : 50|1@0+ (1,0) [0|1] "" VCU
 SG_ P4_BalSwCell191 : 49|1@0+ (1,0) [0|1] "" VCU
 SG_ P4_BalSwCell192 : 48|1@0+ (1,0) [0|1] "" VCU

BO_ 2558525508 BatP4_BMS_CellTempM0: 8 BMS
 SG_ P4_CellTemp1 : 7|11@0+ (0.1,-40) [-40|150] "C" VCU
 SG_ P4_CellTemp2 : 12|11@0+ (0.1,-40) [-40|150] "C" VCU
 SG_ P4_CellTemp3 : 17|11@0+ (0.1,-40) [-40|150] "C" VCU
 SG_ P4_CellTemp4 : 38|11@0+ (0.1,-40) [-40|150] "C" VCU
 SG_ P4_CellTemp5 : 43|11@0+ (0.1,-40) [-40|150] "C" VCU

BO_ 2558591044 BatP4_BMS_CellTempM1: 8 BMS
 SG_ P4_CellTemp6 : 7|11@0+ (0.1,-40) [-40|150] "C" VCU
 SG_ P4_CellTemp7 : 12|11@0+ (0.1,-40) [-40|150] "C" VCU
 SG_ P4_CellTemp8 : 17|11@0+ (0.1,-40) [-40|150] "C" VCU
 SG_ P4_CellTemp9 : 38|11@0+ (0.1,-40) [-40|150] "C" VCU
 SG_ P4_CellTemp10 : 43|11@0+ (0.1,-40) [-40|150] "C" VCU

BO_ 2558656580 BatP4_BMS_CellTempM2: 8 BMS
 SG_ P4_CellTemp11 : 7|11@0+ (0.1,-40) [-40|150] "C" VCU
 SG_ P4_CellTemp12 : 12|11@0+ (0.1,-40) [-40|150] "C" VCU
 SG_ P4_CellTemp13 : 17|11@0+ (0.1,-40) [-40|150] "C" VCU
 SG_ P4_CellTemp14 : 38|11@0+ (0.1,-40) [-40|150] "C" VCU
 SG_ P4_CellTemp15 : 43|11@0+ (0.1,-40) [-40|150] "C" VCU

BO_ 2558722116 BatP4_BMS_CellTempM3: 8 BMS
 SG_ P4_CellTemp16 : 7|11@0+ (0.1,-40) [-40|150] "C" VCU
 SG_ P4_CellTemp17 : 12|11@0+ (0.1,-40) [-40|150] "C" VCU
 SG_ P4_CellTemp18 : 17|11@0+ (0.1,-40) [-40|150] "C" VCU
 SG_ P4_CellTemp19 : 38|11@0+ (0.1,-40) [-40|150] "C" VCU
 SG_ P4_CellTemp20 : 43|11@0+ (0.1,-40) [-40|150] "C" VCU

BO_ 2558787652 BatP4_BMS_CellTempM4: 8 BMS
 SG_ P4_CellTemp21 : 7|11@0+ (0.1,-40) [-40|150] "C" VCU
 SG_ P4_CellTemp22 : 12|11@0+ (0.1,-40) [-40|150] "C" VCU
 SG_ P4_CellTemp23 : 17|11@0+ (0.1,-40) [-40|150] "C" VCU
 SG_ P4_CellTemp24 : 38|11@0+ (0.1,-40) [-40|150] "C" VCU
 SG_ P4_CellTemp25 : 43|11@0+ (0.1,-40) [-40|150] "C" VCU

BO_ 2558853188 BatP4_BMS_CellTempM5: 8 BMS
 SG_ P4_CellTemp26 : 7|11@0+ (0.1,-40) [-40|150] "C" VCU
 SG_ P4_CellTemp27 : 12|11@0+ (0.1,-40) [-40|150] "C" VCU
 SG_ P4_CellTemp28 : 17|11@0+ (0.1,-40) [-40|150] "C" VCU
 SG_ P4_CellTemp29 : 38|11@0+ (0.1,-40) [-40|150] "C" VCU
 SG_ P4_CellTemp30 : 43|11@0+ (0.1,-40) [-40|150] "C" VCU

BO_ 2558918724 BatP4_BMS_CellTempM6: 8 BMS
 SG_ P4_CellTemp31 : 7|11@0+ (0.1,-40) [-40|150] "C" VCU
 SG_ P4_CellTemp32 : 12|11@0+ (0.1,-40) [-40|150] "C" VCU
 SG_ P4_CellTemp33 : 17|11@0+ (0.1,-40) [-40|150] "C" VCU
 SG_ P4_CellTemp34 : 38|11@0+ (0.1,-40) [-40|150] "C" VCU
 SG_ P4_CellTemp35 : 43|11@0+ (0.1,-40) [-40|150] "C" VCU

BO_ 2558984260 BatP4_BMS_CellTempM7: 8 BMS
 SG_ P4_CellTemp36 : 7|11@0+ (0.1,-40) [-40|150] "C" VCU
 SG_ P4_CellTemp37 : 12|11@0+ (0.1,-40) [-40|150] "C" VCU
 SG_ P4_CellTemp38 : 17|11@0+ (0.1,-40) [-40|150] "C" VCU
 SG_ P4_CellTemp39 : 38|11@0+ (0.1,-40) [-40|150] "C" VCU
 SG_ P4_CellTemp40 : 43|11@0+ (0.1,-40) [-40|150] "C" VCU

BO_ 2559049796 BatP4_BMS_CellTempM8: 8 BMS
 SG_ P4_CellTemp41 : 7|11@0+ (0.1,-40) [-40|150] "C" VCU
 SG_ P4_CellTemp42 : 12|11@0+ (0.1,-40) [-40|150] "C" VCU
 SG_ P4_CellTemp43 : 17|11@0+ (0.1,-40) [-40|150] "C" VCU
 SG_ P4_CellTemp44 : 38|11@0+ (0.1,-40) [-40|150] "C" VCU
 SG_ P4_CellTemp45 : 43|11@0+ (0.1,-40) [-40|150] "C" VCU

BO_ 2559115332 BatP4_BMS_CellTempM9: 8 BMS
 SG_ P4_CellTemp46 : 7|11@0+ (0.1,-40) [-40|150] "C" VCU
 SG_ P4_CellTemp47 : 12|11@0+ (0.1,-40) [-40|150] "C" VCU
 SG_ P4_CellTemp48 : 17|11@0+ (0.1,-40) [-40|150] "C" VCU
 SG_ P4_CellTemp49 : 38|11@0+ (0.1,-40) [-40|150] "C" VCU
 SG_ P4_CellTemp50 : 43|11@0+ (0.1,-40) [-40|150] "C" VCU

BO_ 2559180868 BatP4_BMS_CellTempM10: 8 BMS
 SG_ P4_CellTemp51 : 7|11@0+ (0.1,-40) [-40|150] "C" VCU
 SG_ P4_CellTemp52 : 12|11@0+ (0.1,-40) [-40|150] "C" VCU
 SG_ P4_CellTemp53 : 17|11@0+ (0.1,-40) [-40|150] "C" VCU
 SG_ P4_CellTemp54 : 38|11@0+ (0.1,-40) [-40|150] "C" VCU
 SG_ P4_CellTemp55 : 43|11@0+ (0.1,-40) [-40|150] "C" VCU

BO_ 2559246404 BatP4_BMS_CellTempM11: 8 BMS
 SG_ P4_CellTemp56 : 7|11@0+ (0.1,-40) [-40|150] "C" VCU
 SG_ P4_CellTemp57 : 12|11@0+ (0.1,-40) [-40|150] "C" VCU
 SG_ P4_CellTemp58 : 17|11@0+ (0.1,-40) [-40|150] "C" VCU
 SG_ P4_CellTemp59 : 38|11@0+ (0.1,-40) [-40|150] "C" VCU
 SG_ P4_CellTemp60 : 43|11@0+ (0.1,-40) [-40|150] "C" VCU

BO_ 2559311940 BatP4_BMS_CellTempM12: 8 BMS
 SG_ P4_CellTemp61 : 7|11@0+ (0.1,-40) [-40|150] "C" VCU
 SG_ P4_CellTemp62 : 12|11@0+ (0.1,-40) [-40|150] "C" VCU
 SG_ P4_CellTemp63 : 17|11@0+ (0.1,-40) [-40|150] "C" VCU
 SG_ P4_CellTemp64 : 38|11@0+ (0.1,-40) [-40|150] "C" VCU
 SG_ P4_CellTemp65 : 43|11@0+ (0.1,-40) [-40|150] "C" VCU

BO_ 2559377476 BatP4_BMS_CellTempM13: 8 BMS
 SG_ P4_CellTemp66 : 7|11@0+ (0.1,-40) [-40|150] "C" VCU
 SG_ P4_CellTemp67 : 12|11@0+ (0.1,-40) [-40|150] "C" VCU
 SG_ P4_CellTemp68 : 17|11@0+ (0.1,-40) [-40|150] "C" VCU
 SG_ P4_CellTemp69 : 38|11@0+ (0.1,-40) [-40|150] "C" VCU
 SG_ P4_CellTemp70 : 43|11@0+ (0.1,-40) [-40|150] "C" VCU

BO_ 2559443012 BatP4_BMS_CellTempM14: 8 BMS
 SG_ P4_CellTemp71 : 7|11@0+ (0.1,-40) [-40|150] "C" VCU
 SG_ P4_CellTemp72 : 12|11@0+ (0.1,-40) [-40|150] "C" VCU
 SG_ P4_CellTemp73 : 17|11@0+ (0.1,-40) [-40|150] "C" VCU
 SG_ P4_CellTemp74 : 38|11@0+ (0.1,-40) [-40|150] "C" VCU
 SG_ P4_CellTemp75 : 43|11@0+ (0.1,-40) [-40|150] "C" VCU

BO_ 2559508548 BatP4_BMS_CellTempM15: 8 BMS
 SG_ P4_CellTemp76 : 7|11@0+ (0.1,-40) [-40|150] "C" VCU
 SG_ P4_CellTemp77 : 12|11@0+ (0.1,-40) [-40|150] "C" VCU
 SG_ P4_CellTemp78 : 17|11@0+ (0.1,-40) [-40|150] "C" VCU
 SG_ P4_CellTemp79 : 38|11@0+ (0.1,-40) [-40|150] "C" VCU
 SG_ P4_CellTemp80 : 43|11@0+ (0.1,-40) [-40|150] "C" VCU

BO_ 2559574084 BatP4_BMS_CellTempM16: 8 BMS
 SG_ P4_CellTemp81 : 7|11@0+ (0.1,-40) [-40|150] "C" VCU
 SG_ P4_CellTemp82 : 12|11@0+ (0.1,-40) [-40|150] "C" VCU
 SG_ P4_CellTemp83 : 17|11@0+ (0.1,-40) [-40|150] "C" VCU
 SG_ P4_CellTemp84 : 38|11@0+ (0.1,-40) [-40|150] "C" VCU
 SG_ P4_CellTemp85 : 43|11@0+ (0.1,-40) [-40|150] "C" VCU

BO_ 2559639620 BatP4_BMS_CellTempM17: 8 BMS
 SG_ P4_CellTemp86 : 7|11@0+ (0.1,-40) [-40|150] "C" VCU
 SG_ P4_CellTemp87 : 12|11@0+ (0.1,-40) [-40|150] "C" VCU
 SG_ P4_CellTemp88 : 17|11@0+ (0.1,-40) [-40|150] "C" VCU
 SG_ P4_CellTemp89 : 38|11@0+ (0.1,-40) [-40|150] "C" VCU
 SG_ P4_CellTemp90 : 43|11@0+ (0.1,-40) [-40|150] "C" VCU

BO_ 2559705156 BatP4_BMS_CellTempM18: 8 BMS
 SG_ P4_CellTemp91 : 7|11@0+ (0.1,-40) [-40|150] "C" VCU
 SG_ P4_CellTemp92 : 12|11@0+ (0.1,-40) [-40|150] "C" VCU
 SG_ P4_CellTemp93 : 17|11@0+ (0.1,-40) [-40|150] "C" VCU
 SG_ P4_CellTemp94 : 38|11@0+ (0.1,-40) [-40|150] "C" VCU
 SG_ P4_CellTemp95 : 43|11@0+ (0.1,-40) [-40|150] "C" VCU

BO_ 2559770692 BatP4_BMS_CellTempM19: 8 BMS
 SG_ P4_CellTemp96 : 7|11@0+ (0.1,-40) [-40|150] "C" VCU
 SG_ P4_CellTemp97 : 12|11@0+ (0.1,-40) [-40|150] "C" VCU
 SG_ P4_CellTemp98 : 17|11@0+ (0.1,-40) [-40|150] "C" VCU
 SG_ P4_CellTemp99 : 38|11@0+ (0.1,-40) [-40|150] "C" VCU
 SG_ P4_CellTemp100 : 43|11@0+ (0.1,-40) [-40|150] "C" VCU

BO_ 2559836228 BatP4_BMS_CellTempM20: 8 BMS
 SG_ P4_CellTemp101 : 7|11@0+ (0.1,-40) [-40|150] "C" VCU
 SG_ P4_CellTemp102 : 12|11@0+ (0.1,-40) [-40|150] "C" VCU
 SG_ P4_CellTemp103 : 17|11@0+ (0.1,-40) [-40|150] "C" VCU
 SG_ P4_CellTemp104 : 38|11@0+ (0.1,-40) [-40|150] "C" VCU
 SG_ P4_CellTemp105 : 43|11@0+ (0.1,-40) [-40|150] "C" VCU

BO_ 2559901764 BatP4_BMS_CellTempM21: 8 BMS
 SG_ P4_CellTemp106 : 7|11@0+ (0.1,-40) [-40|150] "C" VCU
 SG_ P4_CellTemp107 : 12|11@0+ (0.1,-40) [-40|150] "C" VCU
 SG_ P4_CellTemp108 : 17|11@0+ (0.1,-40) [-40|150] "C" VCU
 SG_ P4_CellTemp109 : 38|11@0+ (0.1,-40) [-40|150] "C" VCU
 SG_ P4_CellTemp110 : 43|11@0+ (0.1,-40) [-40|150] "C" VCU

BO_ 2559967300 BatP4_BMS_CellTempM22: 8 BMS
 SG_ P4_CellTemp111 : 7|11@0+ (0.1,-40) [-40|150] "C" VCU
 SG_ P4_CellTemp112 : 12|11@0+ (0.1,-40) [-40|150] "C" VCU
 SG_ P4_CellTemp113 : 17|11@0+ (0.1,-40) [-40|150] "C" VCU
 SG_ P4_CellTemp114 : 38|11@0+ (0.1,-40) [-40|150] "C" VCU
 SG_ P4_CellTemp115 : 43|11@0+ (0.1,-40) [-40|150] "C" VCU

BO_ 2560032836 BatP4_BMS_CellTempM23: 8 BMS
 SG_ P4_CellTemp116 : 7|11@0+ (0.1,-40) [-40|150] "C" VCU
 SG_ P4_CellTemp117 : 12|11@0+ (0.1,-40) [-40|150] "C" VCU
 SG_ P4_CellTemp118 : 17|11@0+ (0.1,-40) [-40|150] "C" VCU
 SG_ P4_CellTemp119 : 38|11@0+ (0.1,-40) [-40|150] "C" VCU
 SG_ P4_CellTemp120 : 43|11@0+ (0.1,-40) [-40|150] "C" VCU

BO_ 2560098372 BatP4_BMS_CellTempM24: 8 BMS
 SG_ P4_CellTemp121 : 7|11@0+ (0.1,-40) [-40|150] "C" VCU
 SG_ P4_CellTemp122 : 12|11@0+ (0.1,-40) [-40|150] "C" VCU
 SG_ P4_CellTemp123 : 17|11@0+ (0.1,-40) [-40|150] "C" VCU
 SG_ P4_CellTemp124 : 38|11@0+ (0.1,-40) [-40|150] "C" VCU
 SG_ P4_CellTemp125 : 43|11@0+ (0.1,-40) [-40|150] "C" VCU

BO_ 2560163908 BatP4_BMS_CellTempM25: 8 BMS
 SG_ P4_CellTemp126 : 7|11@0+ (0.1,-40) [-40|150] "C" VCU
 SG_ P4_CellTemp127 : 12|11@0+ (0.1,-40) [-40|150] "C" VCU
 SG_ P4_CellTemp128 : 17|11@0+ (0.1,-40) [-40|150] "C" VCU
 SG_ P4_CellTemp129 : 38|11@0+ (0.1,-40) [-40|150] "C" VCU
 SG_ P4_CellTemp130 : 43|11@0+ (0.1,-40) [-40|150] "C" VCU

BO_ 2560229444 BatP4_BMS_CellTempM26: 8 BMS
 SG_ P4_CellTemp131 : 7|11@0+ (0.1,-40) [-40|150] "C" VCU
 SG_ P4_CellTemp132 : 12|11@0+ (0.1,-40) [-40|150] "C" VCU
 SG_ P4_CellTemp133 : 17|11@0+ (0.1,-40) [-40|150] "C" VCU
 SG_ P4_CellTemp134 : 38|11@0+ (0.1,-40) [-40|150] "C" VCU
 SG_ P4_CellTemp135 : 43|11@0+ (0.1,-40) [-40|150] "C" VCU

BO_ 2560294980 BatP4_BMS_CellTempM27: 8 BMS
 SG_ P4_CellTemp136 : 7|11@0+ (0.1,-40) [-40|150] "C" VCU
 SG_ P4_CellTemp137 : 12|11@0+ (0.1,-40) [-40|150] "C" VCU
 SG_ P4_CellTemp138 : 17|11@0+ (0.1,-40) [-40|150] "C" VCU
 SG_ P4_CellTemp139 : 38|11@0+ (0.1,-40) [-40|150] "C" VCU
 SG_ P4_CellTemp140 : 43|11@0+ (0.1,-40) [-40|150] "C" VCU

BO_ 2560360516 BatP4_BMS_CellTempM28: 8 BMS
 SG_ P4_CellTemp141 : 7|11@0+ (0.1,-40) [-40|150] "C" VCU
 SG_ P4_CellTemp142 : 12|11@0+ (0.1,-40) [-40|150] "C" VCU
 SG_ P4_CellTemp143 : 17|11@0+ (0.1,-40) [-40|150] "C" VCU
 SG_ P4_CellTemp144 : 38|11@0+ (0.1,-40) [-40|150] "C" VCU
 SG_ P4_CellTemp145 : 43|11@0+ (0.1,-40) [-40|150] "C" VCU

BO_ 2560426052 BatP4_BMS_CellTempM29: 8 BMS
 SG_ P4_CellTemp146 : 7|11@0+ (0.1,-40) [-40|150] "C" VCU
 SG_ P4_CellTemp147 : 12|11@0+ (0.1,-40) [-40|150] "C" VCU
 SG_ P4_CellTemp148 : 17|11@0+ (0.1,-40) [-40|150] "C" VCU
 SG_ P4_CellTemp149 : 38|11@0+ (0.1,-40) [-40|150] "C" VCU
 SG_ P4_CellTemp150 : 43|11@0+ (0.1,-40) [-40|150] "C" VCU

BO_ 2560491588 BatP4_BMS_CellTempM30: 8 BMS
 SG_ P4_CellTemp151 : 7|11@0+ (0.1,-40) [-40|150] "C" VCU
 SG_ P4_CellTemp152 : 12|11@0+ (0.1,-40) [-40|150] "C" VCU
 SG_ P4_CellTemp153 : 17|11@0+ (0.1,-40) [-40|150] "C" VCU
 SG_ P4_CellTemp154 : 38|11@0+ (0.1,-40) [-40|150] "C" VCU
 SG_ P4_CellTemp155 : 43|11@0+ (0.1,-40) [-40|150] "C" VCU

BO_ 2560557124 BatP4_BMS_CellTempM31: 8 BMS
 SG_ P4_CellTemp156 : 7|11@0+ (0.1,-40) [-40|150] "C" VCU
 SG_ P4_CellTemp157 : 12|11@0+ (0.1,-40) [-40|150] "C" VCU
 SG_ P4_CellTemp158 : 17|11@0+ (0.1,-40) [-40|150] "C" VCU
 SG_ P4_CellTemp159 : 38|11@0+ (0.1,-40) [-40|150] "C" VCU
 SG_ P4_CellTemp160 : 43|11@0+ (0.1,-40) [-40|150] "C" VCU

BO_ 2560622660 BatP4_BMS_CellTempM32: 8 BMS
 SG_ P4_CellTemp161 : 7|11@0+ (0.1,-40) [-40|150] "C" VCU
 SG_ P4_CellTemp162 : 12|11@0+ (0.1,-40) [-40|150] "C" VCU
 SG_ P4_CellTemp163 : 17|11@0+ (0.1,-40) [-40|150] "C" VCU
 SG_ P4_CellTemp164 : 38|11@0+ (0.1,-40) [-40|150] "C" VCU
 SG_ P4_CellTemp165 : 43|11@0+ (0.1,-40) [-40|150] "C" VCU

BO_ 2560688196 BatP4_BMS_CellTempM33: 8 BMS
 SG_ P4_CellTemp166 : 7|11@0+ (0.1,-40) [-40|150] "C" VCU
 SG_ P4_CellTemp167 : 12|11@0+ (0.1,-40) [-40|150] "C" VCU
 SG_ P4_CellTemp168 : 17|11@0+ (0.1,-40) [-40|150] "C" VCU
 SG_ P4_CellTemp169 : 38|11@0+ (0.1,-40) [-40|150] "C" VCU
 SG_ P4_CellTemp170 : 43|11@0+ (0.1,-40) [-40|150] "C" VCU

BO_ 2560753732 BatP4_BMS_CellTempM34: 8 BMS
 SG_ P4_CellTemp171 : 7|11@0+ (0.1,-40) [-40|150] "C" VCU
 SG_ P4_CellTemp172 : 12|11@0+ (0.1,-40) [-40|150] "C" VCU
 SG_ P4_CellTemp173 : 17|11@0+ (0.1,-40) [-40|150] "C" VCU
 SG_ P4_CellTemp174 : 38|11@0+ (0.1,-40) [-40|150] "C" VCU
 SG_ P4_CellTemp175 : 43|11@0+ (0.1,-40) [-40|150] "C" VCU

BO_ 2560819268 BatP4_BMS_CellTempM35: 8 BMS
 SG_ P4_CellTemp176 : 7|11@0+ (0.1,-40) [-40|150] "C" VCU
 SG_ P4_CellTemp177 : 12|11@0+ (0.1,-40) [-40|150] "C" VCU
 SG_ P4_CellTemp178 : 17|11@0+ (0.1,-40) [-40|150] "C" VCU
 SG_ P4_CellTemp179 : 38|11@0+ (0.1,-40) [-40|150] "C" VCU
 SG_ P4_CellTemp180 : 43|11@0+ (0.1,-40) [-40|150] "C" VCU

BO_ 2560884804 BatP4_BMS_CellTempM36: 8 BMS
 SG_ P4_CellTemp181 : 7|11@0+ (0.1,-40) [-40|150] "C" VCU
 SG_ P4_CellTemp182 : 12|11@0+ (0.1,-40) [-40|150] "C" VCU
 SG_ P4_CellTemp183 : 17|11@0+ (0.1,-40) [-40|150] "C" VCU
 SG_ P4_CellTemp184 : 38|11@0+ (0.1,-40) [-40|150] "C" VCU
 SG_ P4_CellTemp185 : 43|11@0+ (0.1,-40) [-40|150] "C" VCU

BO_ 2560950340 BatP4_BMS_CellTempM37: 8 BMS
 SG_ P4_CellTemp186 : 7|11@0+ (0.1,-40) [-40|150] "C" VCU
 SG_ P4_CellTemp187 : 12|11@0+ (0.1,-40) [-40|150] "C" VCU
 SG_ P4_CellTemp188 : 17|11@0+ (0.1,-40) [-40|150] "C" VCU
 SG_ P4_CellTemp189 : 38|11@0+ (0.1,-40) [-40|150] "C" VCU
 SG_ P4_CellTemp190 : 43|11@0+ (0.1,-40) [-40|150] "C" VCU

BO_ 2561015876 BatP4_BMS_CellTempM38: 8 BMS
 SG_ P4_CellTemp191 : 7|11@0+ (0.1,-40) [-40|150] "C" VCU
 SG_ P4_CellTemp192 : 12|11@0+ (0.1,-40) [-40|150] "C" VCU
 SG_ P4_DatLen16DbgInfo1 : 7|16@0+ (1,0) [0|65535] "" VCU
 SG_ P4_DatLen16DbgInfo2 : 23|16@0+ (1,0) [0|65535] "" VCU
 SG_ P4_DatLen16DbgInfo3 : 39|16@0+ (1,0) [0|65535] "" VCU
 SG_ P4_DatLen16DbgInfo4 : 55|16@0+ (1,0) [0|65535] "" VCU

BO_ 2550399061 BatP5_BMS_PowerSupplyInfo: 8 BMS
 SG_ P5_BMSPwrSuplVlt1 : 7|9@0+ (0.1,0) [0|50] "V" VCU
 SG_ P5_BMSPwrSuplVlt2 : 14|9@0+ (0.1,0) [0|50] "V" VCU
 SG_ P5_ChrgStationAuxPwrSuplVlt : 21|9@0+ (0.1,0) [0|50] "V" VCU
 SG_ P5_BMSKL15ON : 28|1@0+ (1,0) [0|1] "" VCU
 SG_ P5_DCStepState : 27|8@0+ (1,0) [0|255] "" VCU
 SG_ P5_ExtLvWakeup_28VOnly : 35|9@0+ (0.1,0) [0|50] "V" VCU

BO_ 2550464597 BatP5_BMS_PackUsageLimit: 8 BMS
 SG_ P5_PackVltUprLmt : 7|14@0+ (0.1,0) [0|1200] "V" VCU
 SG_ P5_PackVltLoLmt : 9|14@0+ (0.1,0) [0|1200] "V" VCU
 SG_ P5_PackMaxDschrgCrnt : 27|14@0+ (0.1,0) [0|1600] "A" VCU
 SG_ P5_PackMaxChrgCrnt : 45|14@0+ (0.1,0) [0|1600] "A" VCU

CM_ SG_ 2550464563 P3_PackVltUprLmt "电池包3的电压使用上限";
CM_ SG_ 2550464563 P3_PackVltLoLmt "电池包3的电压使用下限";
CM_ SG_ 2550464563 P3_PackMaxDschrgCrnt "电池包3的最大允许放电电流";
CM_ SG_ 2550464563 P3_PackMaxChrgCrnt "电池包3的最大允许充电电流";
CM_ SG_ 2550530099 P3_PackDschrgPwrLmt "电池包3的放电功率限值";
CM_ SG_ 2550530099 P3_PackDschrgPwrStat "电池包3的放电功率状态";
CM_ SG_ 2550530099 P3_PackChrgPwrLmt "电池包3的充电功率限值";
CM_ SG_ 2550530099 P3_PackChrgPwrStat "电池包3的充电功率状态";
CM_ SG_ 2550595635 P3_ChrgrCplrStat "电池包3的充电枪连接状态";
CM_ SG_ 2550595635 P3_HVBattChrgSysStatus "电池包3的充电系统状态";
CM_ SG_ 2550595635 P3_DCChrgCrntCmd "电池包3的直流充电请求电流";
CM_ SG_ 2550595635 P3_CC2Vlt "电池包3的CC2电压值";
CM_ SG_ 2550595635 P3_DCRcptPosTemp "电池包3的快充充电插座正极温度";
CM_ SG_ 2550595635 P3_DCRcptNegTemp "电池包3的快充充电插座负极温度";
CM_ SG_ 2550595635 P3_Tm2FullChrg "电池包3满充剩余时间";
CM_ SG_ 2550661171 P3_Inlet1ClntTemp "进水口1冷却液温度";
CM_ SG_ 2550661171 P3_Inlet2ClntTemp "进水口2冷却液温度";
CM_ SG_ 2550661171 P3_Outlet1ClntTemp "出水口1冷却液温度";
CM_ SG_ 2550661171 P3_Outlet2ClntTemp "出水口2冷却液温度";
CM_ SG_ 2550661171 P3_TrgtClntTemp "冷却水目标温度";
CM_ SG_ 2550661171 P3_TrgtClntFlowRate "冷却水目标流量";
CM_ SG_ 2550726707 P3_MaxCellVlt "电池包3的最大单体电压";
CM_ SG_ 2550726707 P3_MaxCellVltNum "电池包3的最大单体电压编号";
CM_ SG_ 2550726707 P3_MinCellVlt "电池包3的最小单体电压";
CM_ SG_ 2550726707 P3_MinCellVltNum "电池包3的最小单体电压编号";
CM_ SG_ 2550726707 P3_AvgCellVlt "电池包3的平均单体电压";
CM_ SG_ 2550792243 P3_MaxCellTemp "电池包3的最高单体温度";
CM_ SG_ 2550792243 P3_MaxCellTempNum "电池包3的最高单体温度编号";
CM_ SG_ 2550792243 P3_MinCellTemp "电池包3的最低单体温度";
CM_ SG_ 2550792243 P3_MinCellTempNum "电池包3的最低单体温度编号";
CM_ SG_ 2550792243 P3_AvgCellTemp "电池包3的单体平均温度";
CM_ SG_ 2550857779 P3_PackTotFltNum "电池包3的电池故障总数";
CM_ SG_ 2550857779 P3_CellOverVoltage "电池包3的单体过压";
CM_ SG_ 2550857779 P3_CellUnderVoltage "电池包3的单体欠压";
CM_ SG_ 2550857779 P3_CellVoltageDiffHi "电池包3的单体压差过大";
CM_ SG_ 2550857779 P3_PackOverVoltage "电池包3的电压过高";
CM_ SG_ 2550857779 P3_PackUnderVoltage "电池包3的电压过低";
CM_ SG_ 2550857779 P3_CellOverTemp "电池包3的单体过温";
CM_ SG_ 2550857779 P3_CellTempLow "电池包3的单体温度过低";
CM_ SG_ 2550857779 P3_CellTempDiffHi "电池包3的单体温度差异过大";
CM_ SG_ 2550857779 P3_PackDschrgCrntHi "电池包3的放电电流过流";
CM_ SG_ 2550857779 P3_PackChrgCrntHi "电池包3的充电电流过流";
CM_ SG_ 2550857779 P3_PackCrnSnsr1OffsetHi "电池包3的电流传感器1零漂过大";
CM_ SG_ 2550857779 P3_HVIsolFlt "电池包3的高压绝缘故障";
CM_ SG_ 2550857779 P3_HVILFlt "电池包3的高压互锁故障";
CM_ SG_ 2550857779 P3_ThrmlRunaway "电池包3的热失控故障";
CM_ SG_ 2550857779 P3_CellVoltInvalid "电池包3的单体电压采样失效";
CM_ SG_ 2550857779 P3_CellTempInvalid "电池包3的电芯温度采样失效";
CM_ SG_ 2550857779 P3_DaisyChainComFlt "电池包3的菊花链通信故障";
CM_ SG_ 2550857779 P3_PackVoltRatFlt "电池包3的总电压与单体电压总和偏差过大";
CM_ SG_ 2550857779 P3_CrntSnsr1Invalid "电池包3的电流传感器1电流采样失效";
CM_ SG_ 2550857779 P3_CrntSnsr1OOR "电池包3的电流传感器1电流超出采样范围";
CM_ SG_ 2550857779 P3_CrntSnsr2Invalid "电池包3的电流传感器2电流采样失效";
CM_ SG_ 2550857779 P3_CrntSnsr2OOR "电池包3的电流传感器2电流超出采样范围";
CM_ SG_ 2550857779 P3_PackCrnSnsr2OffsetHi "电池包3的电流传感器2零漂过大";
CM_ SG_ 2550857779 P3_OutofEnergy "电池包3的电池剩余电量低";
CM_ SG_ 2550857779 P3_IsolDetCircErr "电池包3的绝缘检测电路失效";
CM_ SG_ 2550857779 P3_HVILCircShortToGND "电池包3的高压互锁对地短路";
CM_ SG_ 2550857779 P3_HVILCircShortToPwr "电池包3的高压互锁对电源短路";
CM_ SG_ 2550923315 P3_MainPosCntctrStkClsd "电池包3的主正继电器粘连故障";
CM_ SG_ 2550923315 P3_MainPosCntctrStkOpn "电池包3的主正继电器常开故障";
CM_ SG_ 2550923315 P3_MainNegCntctr1StkClsd "电池包3的主负继电器1粘连故障";
CM_ SG_ 2550923315 P3_MainNegCntctr1StkOpn "电池包3的主负继电器1常开故障";
CM_ SG_ 2550923315 P3_MainNegCntctr2StkClsd "电池包3的主负继电器2粘连故障";
CM_ SG_ 2550923315 P3_MainNegCntctr2StkOpn "电池包3的主负继电器2常开故障";
CM_ SG_ 2550923315 P3_PrechargTmOut "电池包3的预充超时故障";
CM_ SG_ 2550923315 P3_PrechrgCrntHi "电池包3的预充过流故障";
CM_ SG_ 2550923315 P3_ChrgCplrPosTempHi "电池包3的充电正极接口温度过高故障";
CM_ SG_ 2550923315 P3_ChrgCplrNegTempHi "电池包3的充电负极接口温度过高故障";
CM_ SG_ 2550923315 P3_BMSPwrSuplVlt1Hi "电池包3的BMS供电电压1过高";
CM_ SG_ 2550923315 P3_BMSPwrSuplVlt1Lo "电池包3的BMS供电电压1过低";
CM_ SG_ 2550923315 P3_BMSPwrSuplVlt2Hi "电池包3的BMS供电电压2过高";
CM_ SG_ 2550923315 P3_BMSPwrSuplVlt2Lo "电池包3的BMS供电电压2过低";
CM_ SG_ 2550923315 P3_CntctrCirPwrSuplVltLo "电池包3的继电器驱动供电电压过低";
CM_ SG_ 2550923315 P3_CntctrCirPwrSuplVltHi "电池包3的继电器驱动供电电压过高";
CM_ SG_ 2550923315 P3_CAN1BusOff "电池包3的CAN1通信Bus off";
CM_ SG_ 2550923315 P3_CAN1BusTmOut "电池包3的CAN1报文超时（Timeout）";
CM_ SG_ 2550923315 P3_CAN2BusOff "电池包3的CAN2通信Bus off";
CM_ SG_ 2550923315 P3_CAN2BusTmOut "电池包3的CAN2报文超时（Timeout）";
CM_ SG_ 2550923315 P3_CellBalCircTempHi "电池包3的均衡电路过温";
CM_ SG_ 2550923315 P3_ClntInTempHi "电池包3的入水口温度过高";
CM_ SG_ 2550923315 P3_ClntOutTempHi "电池包3的出水口温度过高";
CM_ SG_ 2550923315 P3_CellExtrmUdrVolt "电池包3的单体极限欠压";
CM_ SG_ 2550923315 P3_CellExtrmOvrVolt "电池包3的单体极限过压";
CM_ SG_ 2550923315 P3_Branch1DischrgCrntHi  "电池包3的支路1放电过流";
CM_ SG_ 2550923315 P3_Branch2DischrgCrntHi  "电池包3的支路2放电过流";
CM_ SG_ 2550923315 P3_Branch1ChrgCrntHi  "电池包3的支路1充电过流";
CM_ SG_ 2550923315 P3_Branch2ChrgCrntHi  "电池包3的支路2充电过流";
CM_ SG_ 2550923315 P3_InitFailed "电池包3的BMS初始化失败";
CM_ SG_ 2550923315 P3_PackErrCode "电池包3的故障代码";
CM_ SG_ 2550988851 P3_PackTotCellNum "电池包3的单体电池总数";
CM_ SG_ 2550988851 P3_PackTotCellTempSnsrNum "电池包3的单体温度传感器总数";
CM_ SG_ 2552299571 P3_BMSASWMajVerNum "电池包3的BMS应用层软件主版本号";
CM_ SG_ 2552299571 P3_BMSASWMinVerNum "电池包3的BMS应用层软件子版本号";
CM_ SG_ 2552299571 P3_BMSASWPatchVerNum "电池包3的BMS应用层软件修订版本号";
CM_ SG_ 2552299571 P3_BMSBSWMajVerNum "电池包3的BMS底层软件主版本号";
CM_ SG_ 2552299571 P3_BMSBSWMinVerNum "电池包3的BMS底层软件子版本号";
CM_ SG_ 2552299571 P3_BMSBSWPatchVerNum "电池包3的BMS底层软件修订版本号";
CM_ SG_ 2554396723 P3_CellVoltage1 "电池包3的单体电压1";
CM_ SG_ 2554396723 P3_CellVoltage2 "电池包3的单体电压2";
CM_ SG_ 2554396723 P3_CellVoltage3 "电池包3的单体电压3";
CM_ SG_ 2554396723 P3_CellVoltage4 "电池包3的单体电压4";
CM_ SG_ 2554396723 P3_BalSwCell1 "电池包3的电芯1均衡状态";
CM_ SG_ 2554396723 P3_BalSwCell2 "电池包3的电芯2均衡状态";
CM_ SG_ 2554396723 P3_BalSwCell3 "电池包3的电芯3均衡状态";
CM_ SG_ 2554396723 P3_BalSwCell4 "电池包3的电芯4均衡状态";
CM_ SG_ 2554462259 P3_CellVoltage5 "电池包3的单体电压5";
CM_ SG_ 2554462259 P3_CellVoltage6 "电池包3的单体电压6";
CM_ SG_ 2554462259 P3_CellVoltage7 "电池包3的单体电压7";
CM_ SG_ 2554462259 P3_CellVoltage8 "电池包3的单体电压8";
CM_ SG_ 2554462259 P3_BalSwCell5 "电池包3的电芯5均衡状态";
CM_ SG_ 2554462259 P3_BalSwCell6 "电池包3的电芯6均衡状态";
CM_ SG_ 2554462259 P3_BalSwCell7 "电池包3的电芯7均衡状态";
CM_ SG_ 2554462259 P3_BalSwCell8 "电池包3的电芯8均衡状态";
CM_ SG_ 2554527795 P3_CellVoltage9 "电池包3的单体电压9";
CM_ SG_ 2554527795 P3_CellVoltage10 "电池包3的单体电压10";
CM_ SG_ 2554527795 P3_CellVoltage11 "电池包3的单体电压11";
CM_ SG_ 2554527795 P3_CellVoltage12 "电池包3的单体电压12";
CM_ SG_ 2554527795 P3_BalSwCell9 "电池包3的电芯9均衡状态";
CM_ SG_ 2554527795 P3_BalSwCell10 "电池包3的电芯10均衡状态";
CM_ SG_ 2554527795 P3_BalSwCell11 "电池包3的电芯11均衡状态";
CM_ SG_ 2554527795 P3_BalSwCell12 "电池包3的电芯12均衡状态";
CM_ SG_ 2554593331 P3_CellVoltage13 "电池包3的单体电压13";
CM_ SG_ 2554593331 P3_CellVoltage14 "电池包3的单体电压14";
CM_ SG_ 2554593331 P3_CellVoltage15 "电池包3的单体电压15";
CM_ SG_ 2554593331 P3_CellVoltage16 "电池包3的单体电压16";
CM_ SG_ 2554593331 P3_BalSwCell13 "电池包3的电芯13均衡状态";
CM_ SG_ 2554593331 P3_BalSwCell14 "电池包3的电芯14均衡状态";
CM_ SG_ 2554593331 P3_BalSwCell15 "电池包3的电芯15均衡状态";
CM_ SG_ 2554593331 P3_BalSwCell16 "电池包3的电芯16均衡状态";
CM_ SG_ 2554658867 P3_CellVoltage17 "电池包3的单体电压17";
CM_ SG_ 2554658867 P3_CellVoltage18 "电池包3的单体电压18";
CM_ SG_ 2554658867 P3_CellVoltage19 "电池包3的单体电压19";
CM_ SG_ 2554658867 P3_CellVoltage20 "电池包3的单体电压20";
CM_ SG_ 2554658867 P3_BalSwCell17 "电池包3的电芯17均衡状态";
CM_ SG_ 2554658867 P3_BalSwCell18 "电池包3的电芯18均衡状态";
CM_ SG_ 2554658867 P3_BalSwCell19 "电池包3的电芯19均衡状态";
CM_ SG_ 2554658867 P3_BalSwCell20 "电池包3的电芯20均衡状态";
CM_ SG_ 2554724403 P3_CellVoltage21 "电池包3的单体电压21";
CM_ SG_ 2554724403 P3_CellVoltage22 "电池包3的单体电压22";
CM_ SG_ 2554724403 P3_CellVoltage23 "电池包3的单体电压23";
CM_ SG_ 2554724403 P3_CellVoltage24 "电池包3的单体电压24";
CM_ SG_ 2554724403 P3_BalSwCell21 "电池包3的电芯21均衡状态";
CM_ SG_ 2554724403 P3_BalSwCell22 "电池包3的电芯22均衡状态";
CM_ SG_ 2554724403 P3_BalSwCell23 "电池包3的电芯23均衡状态";
CM_ SG_ 2554724403 P3_BalSwCell24 "电池包3的电芯24均衡状态";
CM_ SG_ 2554789939 P3_CellVoltage25 "电池包3的单体电压25";
CM_ SG_ 2554789939 P3_CellVoltage26 "电池包3的单体电压26";
CM_ SG_ 2554789939 P3_CellVoltage27 "电池包3的单体电压27";
CM_ SG_ 2554789939 P3_CellVoltage28 "电池包3的单体电压28";
CM_ SG_ 2554789939 P3_BalSwCell25 "电池包3的电芯25均衡状态";
CM_ SG_ 2554789939 P3_BalSwCell26 "电池包3的电芯26均衡状态";
CM_ SG_ 2554789939 P3_BalSwCell27 "电池包3的电芯27均衡状态";
CM_ SG_ 2554789939 P3_BalSwCell28 "电池包3的电芯28均衡状态";
CM_ SG_ 2554855475 P3_CellVoltage29 "电池包3的单体电压29";
CM_ SG_ 2554855475 P3_CellVoltage30 "电池包3的单体电压30";
CM_ SG_ 2554855475 P3_CellVoltage31 "电池包3的单体电压31";
CM_ SG_ 2554855475 P3_CellVoltage32 "电池包3的单体电压32";
CM_ SG_ 2554855475 P3_BalSwCell29 "电池包3的电芯29均衡状态";
CM_ SG_ 2554855475 P3_BalSwCell30 "电池包3的电芯30均衡状态";
CM_ SG_ 2554855475 P3_BalSwCell31 "电池包3的电芯31均衡状态";
CM_ SG_ 2554855475 P3_BalSwCell32 "电池包3的电芯32均衡状态";
CM_ SG_ 2554921011 P3_CellVoltage33 "电池包3的单体电压33";
CM_ SG_ 2554921011 P3_CellVoltage34 "电池包3的单体电压34";
CM_ SG_ 2554921011 P3_CellVoltage35 "电池包3的单体电压35";
CM_ SG_ 2554921011 P3_CellVoltage36 "电池包3的单体电压36";
CM_ SG_ 2554921011 P3_BalSwCell33 "电池包3的电芯33均衡状态";
CM_ SG_ 2554921011 P3_BalSwCell34 "电池包3的电芯34均衡状态";
CM_ SG_ 2554921011 P3_BalSwCell35 "电池包3的电芯35均衡状态";
CM_ SG_ 2554921011 P3_BalSwCell36 "电池包3的电芯36均衡状态";
CM_ SG_ 2554986547 P3_CellVoltage37 "电池包3的单体电压37";
CM_ SG_ 2554986547 P3_CellVoltage38 "电池包3的单体电压38";
CM_ SG_ 2554986547 P3_CellVoltage39 "电池包3的单体电压39";
CM_ SG_ 2554986547 P3_CellVoltage40 "电池包3的单体电压40";
CM_ SG_ 2554986547 P3_BalSwCell37 "电池包3的电芯37均衡状态";
CM_ SG_ 2554986547 P3_BalSwCell38 "电池包3的电芯38均衡状态";
CM_ SG_ 2554986547 P3_BalSwCell39 "电池包3的电芯39均衡状态";
CM_ SG_ 2554986547 P3_BalSwCell40 "电池包3的电芯40均衡状态";
CM_ SG_ 2555052083 P3_CellVoltage41 "电池包3的单体电压41";
CM_ SG_ 2555052083 P3_CellVoltage42 "电池包3的单体电压42";
CM_ SG_ 2555052083 P3_CellVoltage43 "电池包3的单体电压43";
CM_ SG_ 2555052083 P3_CellVoltage44 "电池包3的单体电压44";
CM_ SG_ 2555052083 P3_BalSwCell41 "电池包3的电芯41均衡状态";
CM_ SG_ 2555052083 P3_BalSwCell42 "电池包3的电芯42均衡状态";
CM_ SG_ 2555052083 P3_BalSwCell43 "电池包3的电芯43均衡状态";
CM_ SG_ 2555052083 P3_BalSwCell44 "电池包3的电芯44均衡状态";
CM_ SG_ 2555117619 P3_CellVoltage45 "电池包3的单体电压45";
CM_ SG_ 2555117619 P3_CellVoltage46 "电池包3的单体电压46";
CM_ SG_ 2555117619 P3_CellVoltage47 "电池包3的单体电压47";
CM_ SG_ 2555117619 P3_CellVoltage48 "电池包3的单体电压48";
CM_ SG_ 2555117619 P3_BalSwCell45 "电池包3的电芯45均衡状态";
CM_ SG_ 2555117619 P3_BalSwCell46 "电池包3的电芯46均衡状态";
CM_ SG_ 2555117619 P3_BalSwCell47 "电池包3的电芯47均衡状态";
CM_ SG_ 2555117619 P3_BalSwCell48 "电池包3的电芯48均衡状态";
CM_ SG_ 2555183155 P3_CellVoltage49 "电池包3的单体电压49";
CM_ SG_ 2555183155 P3_CellVoltage50 "电池包3的单体电压50";
CM_ SG_ 2555183155 P3_CellVoltage51 "电池包3的单体电压51";
CM_ SG_ 2555183155 P3_CellVoltage52 "电池包3的单体电压52";
CM_ SG_ 2555183155 P3_BalSwCell49 "电池包3的电芯49均衡状态";
CM_ SG_ 2555183155 P3_BalSwCell50 "电池包3的电芯50均衡状态";
CM_ SG_ 2555183155 P3_BalSwCell51 "电池包3的电芯51均衡状态";
CM_ SG_ 2555183155 P3_BalSwCell52 "电池包3的电芯52均衡状态";
CM_ SG_ 2555248691 P3_CellVoltage53 "电池包3的单体电压53";
CM_ SG_ 2555248691 P3_CellVoltage54 "电池包3的单体电压54";
CM_ SG_ 2555248691 P3_CellVoltage55 "电池包3的单体电压55";
CM_ SG_ 2555248691 P3_CellVoltage56 "电池包3的单体电压56";
CM_ SG_ 2555248691 P3_BalSwCell53 "电池包3的电芯53均衡状态";
CM_ SG_ 2555248691 P3_BalSwCell54 "电池包3的电芯54均衡状态";
CM_ SG_ 2555248691 P3_BalSwCell55 "电池包3的电芯55均衡状态";
CM_ SG_ 2555248691 P3_BalSwCell56 "电池包3的电芯56均衡状态";
CM_ SG_ 2555314227 P3_CellVoltage57 "电池包3的单体电压57";
CM_ SG_ 2555314227 P3_CellVoltage58 "电池包3的单体电压58";
CM_ SG_ 2555314227 P3_CellVoltage59 "电池包3的单体电压59";
CM_ SG_ 2555314227 P3_CellVoltage60 "电池包3的单体电压60";
CM_ SG_ 2555314227 P3_BalSwCell57 "电池包3的电芯57均衡状态";
CM_ SG_ 2555314227 P3_BalSwCell58 "电池包3的电芯58均衡状态";
CM_ SG_ 2555314227 P3_BalSwCell59 "电池包3的电芯59均衡状态";
CM_ SG_ 2555314227 P3_BalSwCell60 "电池包3的电芯60均衡状态";
CM_ SG_ 2555379763 P3_CellVoltage61 "电池包3的单体电压61";
CM_ SG_ 2555379763 P3_CellVoltage62 "电池包3的单体电压62";
CM_ SG_ 2555379763 P3_CellVoltage63 "电池包3的单体电压63";
CM_ SG_ 2555379763 P3_CellVoltage64 "电池包3的单体电压64";
CM_ SG_ 2555379763 P3_BalSwCell61 "电池包3的电芯61均衡状态";
CM_ SG_ 2555379763 P3_BalSwCell62 "电池包3的电芯62均衡状态";
CM_ SG_ 2555379763 P3_BalSwCell63 "电池包3的电芯63均衡状态";
CM_ SG_ 2555379763 P3_BalSwCell64 "电池包3的电芯64均衡状态";
CM_ SG_ 2555445299 P3_CellVoltage65 "电池包3的单体电压65";
CM_ SG_ 2555445299 P3_CellVoltage66 "电池包3的单体电压66";
CM_ SG_ 2555445299 P3_CellVoltage67 "电池包3的单体电压67";
CM_ SG_ 2555445299 P3_CellVoltage68 "电池包3的单体电压68";
CM_ SG_ 2555445299 P3_BalSwCell65 "电池包3的电芯65均衡状态";
CM_ SG_ 2555445299 P3_BalSwCell66 "电池包3的电芯66均衡状态";
CM_ SG_ 2555445299 P3_BalSwCell67 "电池包3的电芯67均衡状态";
CM_ SG_ 2555445299 P3_BalSwCell68 "电池包3的电芯68均衡状态";
CM_ SG_ 2555510835 P3_CellVoltage69 "电池包3的单体电压69";
CM_ SG_ 2555510835 P3_CellVoltage70 "电池包3的单体电压70";
CM_ SG_ 2555510835 P3_CellVoltage71 "电池包3的单体电压71";
CM_ SG_ 2555510835 P3_CellVoltage72 "电池包3的单体电压72";
CM_ SG_ 2555510835 P3_BalSwCell69 "电池包3的电芯69均衡状态";
CM_ SG_ 2555510835 P3_BalSwCell70 "电池包3的电芯70均衡状态";
CM_ SG_ 2555510835 P3_BalSwCell71 "电池包3的电芯71均衡状态";
CM_ SG_ 2555510835 P3_BalSwCell72 "电池包3的电芯72均衡状态";
CM_ SG_ 2555576371 P3_CellVoltage73 "电池包3的单体电压73";
CM_ SG_ 2555576371 P3_CellVoltage74 "电池包3的单体电压74";
CM_ SG_ 2555576371 P3_CellVoltage75 "电池包3的单体电压75";
CM_ SG_ 2555576371 P3_CellVoltage76 "电池包3的单体电压76";
CM_ SG_ 2555576371 P3_BalSwCell73 "电池包3的电芯73均衡状态";
CM_ SG_ 2555576371 P3_BalSwCell74 "电池包3的电芯74均衡状态";
CM_ SG_ 2555576371 P3_BalSwCell75 "电池包3的电芯75均衡状态";
CM_ SG_ 2555576371 P3_BalSwCell76 "电池包3的电芯76均衡状态";
CM_ SG_ 2555641907 P3_CellVoltage77 "电池包3的单体电压77";
CM_ SG_ 2555641907 P3_CellVoltage78 "电池包3的单体电压78";
CM_ SG_ 2555641907 P3_CellVoltage79 "电池包3的单体电压79";
CM_ SG_ 2555641907 P3_CellVoltage80 "电池包3的单体电压80";
CM_ SG_ 2555641907 P3_BalSwCell77 "电池包3的电芯77均衡状态";
CM_ SG_ 2555641907 P3_BalSwCell78 "电池包3的电芯78均衡状态";
CM_ SG_ 2555641907 P3_BalSwCell79 "电池包3的电芯79均衡状态";
CM_ SG_ 2555641907 P3_BalSwCell80 "电池包3的电芯80均衡状态";
CM_ SG_ 2555707443 P3_CellVoltage81 "电池包3的单体电压81";
CM_ SG_ 2555707443 P3_CellVoltage82 "电池包3的单体电压82";
CM_ SG_ 2555707443 P3_CellVoltage83 "电池包3的单体电压83";
CM_ SG_ 2555707443 P3_CellVoltage84 "电池包3的单体电压84";
CM_ SG_ 2555707443 P3_BalSwCell81 "电池包3的电芯81均衡状态";
CM_ SG_ 2555707443 P3_BalSwCell82 "电池包3的电芯82均衡状态";
CM_ SG_ 2555707443 P3_BalSwCell83 "电池包3的电芯83均衡状态";
CM_ SG_ 2555707443 P3_BalSwCell84 "电池包3的电芯84均衡状态";
CM_ SG_ 2555772979 P3_CellVoltage85 "电池包3的单体电压85";
CM_ SG_ 2555772979 P3_CellVoltage86 "电池包3的单体电压86";
CM_ SG_ 2555772979 P3_CellVoltage87 "电池包3的单体电压87";
CM_ SG_ 2555772979 P3_CellVoltage88 "电池包3的单体电压88";
CM_ SG_ 2555772979 P3_BalSwCell85 "电池包3的电芯85均衡状态";
CM_ SG_ 2555772979 P3_BalSwCell86 "电池包3的电芯86均衡状态";
CM_ SG_ 2555772979 P3_BalSwCell87 "电池包3的电芯87均衡状态";
CM_ SG_ 2555772979 P3_BalSwCell88 "电池包3的电芯88均衡状态";
CM_ SG_ 2555838515 P3_CellVoltage89 "电池包3的单体电压89";
CM_ SG_ 2555838515 P3_CellVoltage90 "电池包3的单体电压90";
CM_ SG_ 2555838515 P3_CellVoltage91 "电池包3的单体电压91";
CM_ SG_ 2555838515 P3_CellVoltage92 "电池包3的单体电压92";
CM_ SG_ 2555838515 P3_BalSwCell89 "电池包3的电芯89均衡状态";
CM_ SG_ 2555838515 P3_BalSwCell90 "电池包3的电芯90均衡状态";
CM_ SG_ 2555838515 P3_BalSwCell91 "电池包3的电芯91均衡状态";
CM_ SG_ 2555838515 P3_BalSwCell92 "电池包3的电芯92均衡状态";
CM_ SG_ 2555904051 P3_CellVoltage93 "电池包3的单体电压93";
CM_ SG_ 2555904051 P3_CellVoltage94 "电池包3的单体电压94";
CM_ SG_ 2555904051 P3_CellVoltage95 "电池包3的单体电压95";
CM_ SG_ 2555904051 P3_CellVoltage96 "电池包3的单体电压96";
CM_ SG_ 2555904051 P3_BalSwCell93 "电池包3的电芯93均衡状态";
CM_ SG_ 2555904051 P3_BalSwCell94 "电池包3的电芯94均衡状态";
CM_ SG_ 2555904051 P3_BalSwCell95 "电池包3的电芯95均衡状态";
CM_ SG_ 2555904051 P3_BalSwCell96 "电池包3的电芯96均衡状态";
CM_ SG_ 2555969587 P3_CellVoltage97 "电池包3的单体电压97";
CM_ SG_ 2555969587 P3_CellVoltage98 "电池包3的单体电压98";
CM_ SG_ 2555969587 P3_CellVoltage99 "电池包3的单体电压99";
CM_ SG_ 2555969587 P3_CellVoltage100 "电池包3的单体电压100";
CM_ SG_ 2555969587 P3_BalSwCell97 "电池包3的电芯97均衡状态";
CM_ SG_ 2555969587 P3_BalSwCell98 "电池包3的电芯98均衡状态";
CM_ SG_ 2555969587 P3_BalSwCell99 "电池包3的电芯99均衡状态";
CM_ SG_ 2555969587 P3_BalSwCell100 "电池包3的电芯100均衡状态";
CM_ SG_ 2556035123 P3_CellVoltage101 "电池包3的单体电压101";
CM_ SG_ 2556035123 P3_CellVoltage102 "电池包3的单体电压102";
CM_ SG_ 2556035123 P3_CellVoltage103 "电池包3的单体电压103";
CM_ SG_ 2556035123 P3_CellVoltage104 "电池包3的单体电压104";
CM_ SG_ 2556035123 P3_BalSwCell101 "电池包3的电芯101均衡状态";
CM_ SG_ 2556035123 P3_BalSwCell102 "电池包3的电芯102均衡状态";
CM_ SG_ 2556035123 P3_BalSwCell103 "电池包3的电芯103均衡状态";
CM_ SG_ 2556035123 P3_BalSwCell104 "电池包3的电芯104均衡状态";
CM_ SG_ 2556100659 P3_CellVoltage105 "电池包3的单体电压105";
CM_ SG_ 2556100659 P3_CellVoltage106 "电池包3的单体电压106";
CM_ SG_ 2556100659 P3_CellVoltage107 "电池包3的单体电压107";
CM_ SG_ 2556100659 P3_CellVoltage108 "电池包3的单体电压108";
CM_ SG_ 2556100659 P3_BalSwCell105 "电池包3的电芯105均衡状态";
CM_ SG_ 2556100659 P3_BalSwCell106 "电池包3的电芯106均衡状态";
CM_ SG_ 2556100659 P3_BalSwCell107 "电池包3的电芯107均衡状态";
CM_ SG_ 2556100659 P3_BalSwCell108 "电池包3的电芯108均衡状态";
CM_ SG_ 2556166195 P3_CellVoltage109 "电池包3的单体电压109";
CM_ SG_ 2556166195 P3_CellVoltage110 "电池包3的单体电压110";
CM_ SG_ 2556166195 P3_CellVoltage111 "电池包3的单体电压111";
CM_ SG_ 2556166195 P3_CellVoltage112 "电池包3的单体电压112";
CM_ SG_ 2556166195 P3_BalSwCell109 "电池包3的电芯109均衡状态";
CM_ SG_ 2556166195 P3_BalSwCell110 "电池包3的电芯110均衡状态";
CM_ SG_ 2556166195 P3_BalSwCell111 "电池包3的电芯111均衡状态";
CM_ SG_ 2556166195 P3_BalSwCell112 "电池包3的电芯112均衡状态";
CM_ SG_ 2556231731 P3_CellVoltage113 "电池包3的单体电压113";
CM_ SG_ 2556231731 P3_CellVoltage114 "电池包3的单体电压114";
CM_ SG_ 2556231731 P3_CellVoltage115 "电池包3的单体电压115";
CM_ SG_ 2556231731 P3_CellVoltage116 "电池包3的单体电压116";
CM_ SG_ 2556231731 P3_BalSwCell113 "电池包3的电芯113均衡状态";
CM_ SG_ 2556231731 P3_BalSwCell114 "电池包3的电芯114均衡状态";
CM_ SG_ 2556231731 P3_BalSwCell115 "电池包3的电芯115均衡状态";
CM_ SG_ 2556231731 P3_BalSwCell116 "电池包3的电芯116均衡状态";
CM_ SG_ 2556297267 P3_CellVoltage117 "电池包3的单体电压117";
CM_ SG_ 2556297267 P3_CellVoltage118 "电池包3的单体电压118";
CM_ SG_ 2556297267 P3_CellVoltage119 "电池包3的单体电压119";
CM_ SG_ 2556297267 P3_CellVoltage120 "电池包3的单体电压120";
CM_ SG_ 2556297267 P3_BalSwCell117 "电池包3的电芯117均衡状态";
CM_ SG_ 2556297267 P3_BalSwCell118 "电池包3的电芯118均衡状态";
CM_ SG_ 2556297267 P3_BalSwCell119 "电池包3的电芯119均衡状态";
CM_ SG_ 2556297267 P3_BalSwCell120 "电池包3的电芯120均衡状态";
CM_ SG_ 2556362803 P3_CellVoltage121 "电池包3的单体电压121";
CM_ SG_ 2556362803 P3_CellVoltage122 "电池包3的单体电压122";
CM_ SG_ 2556362803 P3_CellVoltage123 "电池包3的单体电压123";
CM_ SG_ 2556362803 P3_CellVoltage124 "电池包3的单体电压124";
CM_ SG_ 2556362803 P3_BalSwCell121 "电池包3的电芯121均衡状态";
CM_ SG_ 2556362803 P3_BalSwCell122 "电池包3的电芯122均衡状态";
CM_ SG_ 2556362803 P3_BalSwCell123 "电池包3的电芯123均衡状态";
CM_ SG_ 2556362803 P3_BalSwCell124 "电池包3的电芯124均衡状态";
CM_ SG_ 2556428339 P3_CellVoltage125 "电池包3的单体电压125";
CM_ SG_ 2556428339 P3_CellVoltage126 "电池包3的单体电压126";
CM_ SG_ 2556428339 P3_CellVoltage127 "电池包3的单体电压127";
CM_ SG_ 2556428339 P3_CellVoltage128 "电池包3的单体电压128";
CM_ SG_ 2556428339 P3_BalSwCell125 "电池包3的电芯125均衡状态";
CM_ SG_ 2556428339 P3_BalSwCell126 "电池包3的电芯126均衡状态";
CM_ SG_ 2556428339 P3_BalSwCell127 "电池包3的电芯127均衡状态";
CM_ SG_ 2556428339 P3_BalSwCell128 "电池包3的电芯128均衡状态";
CM_ SG_ 2556493875 P3_CellVoltage129 "电池包3的单体电压129";
CM_ SG_ 2556493875 P3_CellVoltage130 "电池包3的单体电压130";
CM_ SG_ 2556493875 P3_CellVoltage131 "电池包3的单体电压131";
CM_ SG_ 2556493875 P3_CellVoltage132 "电池包3的单体电压132";
CM_ SG_ 2556493875 P3_BalSwCell129 "电池包3的电芯129均衡状态";
CM_ SG_ 2556493875 P3_BalSwCell130 "电池包3的电芯130均衡状态";
CM_ SG_ 2556493875 P3_BalSwCell131 "电池包3的电芯131均衡状态";
CM_ SG_ 2556493875 P3_BalSwCell132 "电池包3的电芯132均衡状态";
CM_ SG_ 2556559411 P3_CellVoltage133 "电池包3的单体电压133";
CM_ SG_ 2556559411 P3_CellVoltage134 "电池包3的单体电压134";
CM_ SG_ 2556559411 P3_CellVoltage135 "电池包3的单体电压135";
CM_ SG_ 2556559411 P3_CellVoltage136 "电池包3的单体电压136";
CM_ SG_ 2556559411 P3_BalSwCell133 "电池包3的电芯133均衡状态";
CM_ SG_ 2556559411 P3_BalSwCell134 "电池包3的电芯134均衡状态";
CM_ SG_ 2556559411 P3_BalSwCell135 "电池包3的电芯135均衡状态";
CM_ SG_ 2556559411 P3_BalSwCell136 "电池包3的电芯136均衡状态";
CM_ SG_ 2556624947 P3_CellVoltage137 "电池包3的单体电压137";
CM_ SG_ 2556624947 P3_CellVoltage138 "电池包3的单体电压138";
CM_ SG_ 2556624947 P3_CellVoltage139 "电池包3的单体电压139";
CM_ SG_ 2556624947 P3_CellVoltage140 "电池包3的单体电压140";
CM_ SG_ 2556624947 P3_BalSwCell137 "电池包3的电芯137均衡状态";
CM_ SG_ 2556624947 P3_BalSwCell138 "电池包3的电芯138均衡状态";
CM_ SG_ 2556624947 P3_BalSwCell139 "电池包3的电芯139均衡状态";
CM_ SG_ 2556624947 P3_BalSwCell140 "电池包3的电芯140均衡状态";
CM_ SG_ 2556690483 P3_CellVoltage141 "电池包3的单体电压141";
CM_ SG_ 2556690483 P3_CellVoltage142 "电池包3的单体电压142";
CM_ SG_ 2556690483 P3_CellVoltage143 "电池包3的单体电压143";
CM_ SG_ 2556690483 P3_CellVoltage144 "电池包3的单体电压144";
CM_ SG_ 2556690483 P3_BalSwCell141 "电池包3的电芯141均衡状态";
CM_ SG_ 2556690483 P3_BalSwCell142 "电池包3的电芯142均衡状态";
CM_ SG_ 2556690483 P3_BalSwCell143 "电池包3的电芯143均衡状态";
CM_ SG_ 2556690483 P3_BalSwCell144 "电池包3的电芯144均衡状态";
CM_ SG_ 2556756019 P3_CellVoltage145 "电池包3的单体电压145";
CM_ SG_ 2556756019 P3_CellVoltage146 "电池包3的单体电压146";
CM_ SG_ 2556756019 P3_CellVoltage147 "电池包3的单体电压147";
CM_ SG_ 2556756019 P3_CellVoltage148 "电池包3的单体电压148";
CM_ SG_ 2556756019 P3_BalSwCell145 "电池包3的电芯145均衡状态";
CM_ SG_ 2556756019 P3_BalSwCell146 "电池包3的电芯146均衡状态";
CM_ SG_ 2556756019 P3_BalSwCell147 "电池包3的电芯147均衡状态";
CM_ SG_ 2556756019 P3_BalSwCell148 "电池包3的电芯148均衡状态";
CM_ SG_ 2556821555 P3_CellVoltage149 "电池包3的单体电压149";
CM_ SG_ 2556821555 P3_CellVoltage150 "电池包3的单体电压150";
CM_ SG_ 2556821555 P3_CellVoltage151 "电池包3的单体电压151";
CM_ SG_ 2556821555 P3_CellVoltage152 "电池包3的单体电压152";
CM_ SG_ 2556821555 P3_BalSwCell149 "电池包3的电芯149均衡状态";
CM_ SG_ 2556821555 P3_BalSwCell150 "电池包3的电芯150均衡状态";
CM_ SG_ 2556821555 P3_BalSwCell151 "电池包3的电芯151均衡状态";
CM_ SG_ 2556821555 P3_BalSwCell152 "电池包3的电芯152均衡状态";
CM_ SG_ 2556887091 P3_CellVoltage153 "电池包3的单体电压153";
CM_ SG_ 2556887091 P3_CellVoltage154 "电池包3的单体电压154";
CM_ SG_ 2556887091 P3_CellVoltage155 "电池包3的单体电压155";
CM_ SG_ 2556887091 P3_CellVoltage156 "电池包3的单体电压156";
CM_ SG_ 2556887091 P3_BalSwCell153 "电池包3的电芯153均衡状态";
CM_ SG_ 2556887091 P3_BalSwCell154 "电池包3的电芯154均衡状态";
CM_ SG_ 2556887091 P3_BalSwCell155 "电池包3的电芯155均衡状态";
CM_ SG_ 2556887091 P3_BalSwCell156 "电池包3的电芯156均衡状态";
CM_ SG_ 2556952627 P3_CellVoltage157 "电池包3的单体电压157";
CM_ SG_ 2556952627 P3_CellVoltage158 "电池包3的单体电压158";
CM_ SG_ 2556952627 P3_CellVoltage159 "电池包3的单体电压159";
CM_ SG_ 2556952627 P3_CellVoltage160 "电池包3的单体电压160";
CM_ SG_ 2556952627 P3_BalSwCell157 "电池包3的电芯157均衡状态";
CM_ SG_ 2556952627 P3_BalSwCell158 "电池包3的电芯158均衡状态";
CM_ SG_ 2556952627 P3_BalSwCell159 "电池包3的电芯159均衡状态";
CM_ SG_ 2556952627 P3_BalSwCell160 "电池包3的电芯160均衡状态";
CM_ SG_ 2557018163 P3_CellVoltage161 "电池包3的单体电压161";
CM_ SG_ 2557018163 P3_CellVoltage162 "电池包3的单体电压162";
CM_ SG_ 2557018163 P3_CellVoltage163 "电池包3的单体电压163";
CM_ SG_ 2557018163 P3_CellVoltage164 "电池包3的单体电压164";
CM_ SG_ 2557018163 P3_BalSwCell161 "电池包3的电芯161均衡状态";
CM_ SG_ 2557018163 P3_BalSwCell162 "电池包3的电芯162均衡状态";
CM_ SG_ 2557018163 P3_BalSwCell163 "电池包3的电芯163均衡状态";
CM_ SG_ 2557018163 P3_BalSwCell164 "电池包3的电芯164均衡状态";
CM_ SG_ 2557083699 P3_CellVoltage165 "电池包3的单体电压165";
CM_ SG_ 2557083699 P3_CellVoltage166 "电池包3的单体电压166";
CM_ SG_ 2557083699 P3_CellVoltage167 "电池包3的单体电压167";
CM_ SG_ 2557083699 P3_CellVoltage168 "电池包3的单体电压168";
CM_ SG_ 2557083699 P3_BalSwCell165 "电池包3的电芯165均衡状态";
CM_ SG_ 2557083699 P3_BalSwCell166 "电池包3的电芯166均衡状态";
CM_ SG_ 2557083699 P3_BalSwCell167 "电池包3的电芯167均衡状态";
CM_ SG_ 2557083699 P3_BalSwCell168 "电池包3的电芯168均衡状态";
CM_ SG_ 2557149235 P3_CellVoltage169 "电池包3的单体电压169";
CM_ SG_ 2557149235 P3_CellVoltage170 "电池包3的单体电压170";
CM_ SG_ 2557149235 P3_CellVoltage171 "电池包3的单体电压171";
CM_ SG_ 2557149235 P3_CellVoltage172 "电池包3的单体电压172";
CM_ SG_ 2557149235 P3_BalSwCell169 "电池包3的电芯169均衡状态";
CM_ SG_ 2557149235 P3_BalSwCell170 "电池包3的电芯170均衡状态";
CM_ SG_ 2557149235 P3_BalSwCell171 "电池包3的电芯171均衡状态";
CM_ SG_ 2557149235 P3_BalSwCell172 "电池包3的电芯172均衡状态";
CM_ SG_ 2557214771 P3_CellVoltage173 "电池包3的单体电压173";
CM_ SG_ 2557214771 P3_CellVoltage174 "电池包3的单体电压174";
CM_ SG_ 2557214771 P3_CellVoltage175 "电池包3的单体电压175";
CM_ SG_ 2557214771 P3_CellVoltage176 "电池包3的单体电压176";
CM_ SG_ 2557214771 P3_BalSwCell173 "电池包3的电芯173均衡状态";
CM_ SG_ 2557214771 P3_BalSwCell174 "电池包3的电芯174均衡状态";
CM_ SG_ 2557214771 P3_BalSwCell175 "电池包3的电芯175均衡状态";
CM_ SG_ 2557214771 P3_BalSwCell176 "电池包3的电芯176均衡状态";
CM_ SG_ 2557280307 P3_CellVoltage177 "电池包3的单体电压177";
CM_ SG_ 2557280307 P3_CellVoltage178 "电池包3的单体电压178";
CM_ SG_ 2557280307 P3_CellVoltage179 "电池包3的单体电压179";
CM_ SG_ 2557280307 P3_CellVoltage180 "电池包3的单体电压180";
CM_ SG_ 2557280307 P3_BalSwCell177 "电池包3的电芯177均衡状态";
CM_ SG_ 2557280307 P3_BalSwCell178 "电池包3的电芯178均衡状态";
CM_ SG_ 2557280307 P3_BalSwCell179 "电池包3的电芯179均衡状态";
CM_ SG_ 2557280307 P3_BalSwCell180 "电池包3的电芯180均衡状态";
CM_ SG_ 2557345843 P3_CellVoltage181 "电池包3的单体电压181";
CM_ SG_ 2557345843 P3_CellVoltage182 "电池包3的单体电压182";
CM_ SG_ 2557345843 P3_CellVoltage183 "电池包3的单体电压183";
CM_ SG_ 2557345843 P3_CellVoltage184 "电池包3的单体电压184";
CM_ SG_ 2557345843 P3_BalSwCell181 "电池包3的电芯181均衡状态";
CM_ SG_ 2557345843 P3_BalSwCell182 "电池包3的电芯182均衡状态";
CM_ SG_ 2557345843 P3_BalSwCell183 "电池包3的电芯183均衡状态";
CM_ SG_ 2557345843 P3_BalSwCell184 "电池包3的电芯184均衡状态";
CM_ SG_ 2557411379 P3_CellVoltage185 "电池包3的单体电压185";
CM_ SG_ 2557411379 P3_CellVoltage186 "电池包3的单体电压186";
CM_ SG_ 2557411379 P3_CellVoltage187 "电池包3的单体电压187";
CM_ SG_ 2557411379 P3_CellVoltage188 "电池包3的单体电压188";
CM_ SG_ 2557411379 P3_BalSwCell185 "电池包3的电芯185均衡状态";
CM_ SG_ 2557411379 P3_BalSwCell186 "电池包3的电芯186均衡状态";
CM_ SG_ 2557411379 P3_BalSwCell187 "电池包3的电芯187均衡状态";
CM_ SG_ 2557411379 P3_BalSwCell188 "电池包3的电芯188均衡状态";
CM_ SG_ 2557476915 P3_CellVoltage189 "电池包3的单体电压189";
CM_ SG_ 2557476915 P3_CellVoltage190 "电池包3的单体电压190";
CM_ SG_ 2557476915 P3_CellVoltage191 "电池包3的单体电压191";
CM_ SG_ 2557476915 P3_CellVoltage192 "电池包3的单体电压192";
CM_ SG_ 2557476915 P3_BalSwCell189 "电池包3的电芯189均衡状态";
CM_ SG_ 2557476915 P3_BalSwCell190 "电池包3的电芯190均衡状态";
CM_ SG_ 2557476915 P3_BalSwCell191 "电池包3的电芯191均衡状态";
CM_ SG_ 2557476915 P3_BalSwCell192 "电池包3的电芯192均衡状态";
CM_ SG_ 2558525491 P3_CellTemp1 "电池包3的单体温度1";
CM_ SG_ 2558525491 P3_CellTemp2 "电池包3的单体温度2";
CM_ SG_ 2558525491 P3_CellTemp3 "电池包3的单体温度3";
CM_ SG_ 2558525491 P3_CellTemp4 "电池包3的单体温度4";
CM_ SG_ 2558525491 P3_CellTemp5 "电池包3的单体温度5";
CM_ SG_ 2558591027 P3_CellTemp6 "电池包3的单体温度6";
CM_ SG_ 2558591027 P3_CellTemp7 "电池包3的单体温度7";
CM_ SG_ 2558591027 P3_CellTemp8 "电池包3的单体温度8";
CM_ SG_ 2558591027 P3_CellTemp9 "电池包3的单体温度9";
CM_ SG_ 2558591027 P3_CellTemp10 "电池包3的单体温度10";
CM_ SG_ 2558656563 P3_CellTemp11 "电池包3的单体温度11";
CM_ SG_ 2558656563 P3_CellTemp12 "电池包3的单体温度12";
CM_ SG_ 2558656563 P3_CellTemp13 "电池包3的单体温度13";
CM_ SG_ 2558656563 P3_CellTemp14 "电池包3的单体温度14";
CM_ SG_ 2558656563 P3_CellTemp15 "电池包3的单体温度15";
CM_ SG_ 2558722099 P3_CellTemp16 "电池包3的单体温度16";
CM_ SG_ 2558722099 P3_CellTemp17 "电池包3的单体温度17";
CM_ SG_ 2558722099 P3_CellTemp18 "电池包3的单体温度18";
CM_ SG_ 2558722099 P3_CellTemp19 "电池包3的单体温度19";
CM_ SG_ 2558722099 P3_CellTemp20 "电池包3的单体温度20";
CM_ SG_ 2558787635 P3_CellTemp21 "电池包3的单体温度21";
CM_ SG_ 2558787635 P3_CellTemp22 "电池包3的单体温度22";
CM_ SG_ 2558787635 P3_CellTemp23 "电池包3的单体温度23";
CM_ SG_ 2558787635 P3_CellTemp24 "电池包3的单体温度24";
CM_ SG_ 2558787635 P3_CellTemp25 "电池包3的单体温度25";
CM_ SG_ 2558853171 P3_CellTemp26 "电池包3的单体温度26";
CM_ SG_ 2558853171 P3_CellTemp27 "电池包3的单体温度27";
CM_ SG_ 2558853171 P3_CellTemp28 "电池包3的单体温度28";
CM_ SG_ 2558853171 P3_CellTemp29 "电池包3的单体温度29";
CM_ SG_ 2558853171 P3_CellTemp30 "电池包3的单体温度30";
CM_ SG_ 2558918707 P3_CellTemp31 "电池包3的单体温度31";
CM_ SG_ 2558918707 P3_CellTemp32 "电池包3的单体温度32";
CM_ SG_ 2558918707 P3_CellTemp33 "电池包3的单体温度33";
CM_ SG_ 2558918707 P3_CellTemp34 "电池包3的单体温度34";
CM_ SG_ 2558918707 P3_CellTemp35 "电池包3的单体温度35";
CM_ SG_ 2558984243 P3_CellTemp36 "电池包3的单体温度36";
CM_ SG_ 2558984243 P3_CellTemp37 "电池包3的单体温度37";
CM_ SG_ 2558984243 P3_CellTemp38 "电池包3的单体温度38";
CM_ SG_ 2558984243 P3_CellTemp39 "电池包3的单体温度39";
CM_ SG_ 2558984243 P3_CellTemp40 "电池包3的单体温度40";
CM_ SG_ 2559049779 P3_CellTemp41 "电池包3的单体温度41";
CM_ SG_ 2559049779 P3_CellTemp42 "电池包3的单体温度42";
CM_ SG_ 2559049779 P3_CellTemp43 "电池包3的单体温度43";
CM_ SG_ 2559049779 P3_CellTemp44 "电池包3的单体温度44";
CM_ SG_ 2559049779 P3_CellTemp45 "电池包3的单体温度45";
CM_ SG_ 2559115315 P3_CellTemp46 "电池包3的单体温度46";
CM_ SG_ 2559115315 P3_CellTemp47 "电池包3的单体温度47";
CM_ SG_ 2559115315 P3_CellTemp48 "电池包3的单体温度48";
CM_ SG_ 2559115315 P3_CellTemp49 "电池包3的单体温度49";
CM_ SG_ 2559115315 P3_CellTemp50 "电池包3的单体温度50";
CM_ SG_ 2559180851 P3_CellTemp51 "电池包3的单体温度51";
CM_ SG_ 2559180851 P3_CellTemp52 "电池包3的单体温度52";
CM_ SG_ 2559180851 P3_CellTemp53 "电池包3的单体温度53";
CM_ SG_ 2559180851 P3_CellTemp54 "电池包3的单体温度54";
CM_ SG_ 2559180851 P3_CellTemp55 "电池包3的单体温度55";
CM_ SG_ 2559246387 P3_CellTemp56 "电池包3的单体温度56";
CM_ SG_ 2559246387 P3_CellTemp57 "电池包3的单体温度57";
CM_ SG_ 2559246387 P3_CellTemp58 "电池包3的单体温度58";
CM_ SG_ 2559246387 P3_CellTemp59 "电池包3的单体温度59";
CM_ SG_ 2559246387 P3_CellTemp60 "电池包3的单体温度60";
CM_ SG_ 2559311923 P3_CellTemp61 "电池包3的单体温度61";
CM_ SG_ 2559311923 P3_CellTemp62 "电池包3的单体温度62";
CM_ SG_ 2559311923 P3_CellTemp63 "电池包3的单体温度63";
CM_ SG_ 2559311923 P3_CellTemp64 "电池包3的单体温度64";
CM_ SG_ 2559311923 P3_CellTemp65 "电池包3的单体温度65";
CM_ SG_ 2559377459 P3_CellTemp66 "电池包3的单体温度66";
CM_ SG_ 2559377459 P3_CellTemp67 "电池包3的单体温度67";
CM_ SG_ 2559377459 P3_CellTemp68 "电池包3的单体温度68";
CM_ SG_ 2559377459 P3_CellTemp69 "电池包3的单体温度69";
CM_ SG_ 2559377459 P3_CellTemp70 "电池包3的单体温度70";
CM_ SG_ 2559442995 P3_CellTemp71 "电池包3的单体温度71";
CM_ SG_ 2559442995 P3_CellTemp72 "电池包3的单体温度72";
CM_ SG_ 2559442995 P3_CellTemp73 "电池包3的单体温度73";
CM_ SG_ 2559442995 P3_CellTemp74 "电池包3的单体温度74";
CM_ SG_ 2559442995 P3_CellTemp75 "电池包3的单体温度75";
CM_ SG_ 2559508531 P3_CellTemp76 "电池包3的单体温度76";
CM_ SG_ 2559508531 P3_CellTemp77 "电池包3的单体温度77";
CM_ SG_ 2559508531 P3_CellTemp78 "电池包3的单体温度78";
CM_ SG_ 2559508531 P3_CellTemp79 "电池包3的单体温度79";
CM_ SG_ 2559508531 P3_CellTemp80 "电池包3的单体温度80";
CM_ SG_ 2559574067 P3_CellTemp81 "电池包3的单体温度81";
CM_ SG_ 2559574067 P3_CellTemp82 "电池包3的单体温度82";
CM_ SG_ 2559574067 P3_CellTemp83 "电池包3的单体温度83";
CM_ SG_ 2559574067 P3_CellTemp84 "电池包3的单体温度84";
CM_ SG_ 2559574067 P3_CellTemp85 "电池包3的单体温度85";
CM_ SG_ 2559639603 P3_CellTemp86 "电池包3的单体温度86";
CM_ SG_ 2559639603 P3_CellTemp87 "电池包3的单体温度87";
CM_ SG_ 2559639603 P3_CellTemp88 "电池包3的单体温度88";
CM_ SG_ 2559639603 P3_CellTemp89 "电池包3的单体温度89";
CM_ SG_ 2559639603 P3_CellTemp90 "电池包3的单体温度90";
CM_ SG_ 2559705139 P3_CellTemp91 "电池包3的单体温度91";
CM_ SG_ 2559705139 P3_CellTemp92 "电池包3的单体温度92";
CM_ SG_ 2559705139 P3_CellTemp93 "电池包3的单体温度93";
CM_ SG_ 2559705139 P3_CellTemp94 "电池包3的单体温度94";
CM_ SG_ 2559705139 P3_CellTemp95 "电池包3的单体温度95";
CM_ SG_ 2559770675 P3_CellTemp96 "电池包3的单体温度96";
CM_ SG_ 2559770675 P3_CellTemp97 "电池包3的单体温度97";
CM_ SG_ 2559770675 P3_CellTemp98 "电池包3的单体温度98";
CM_ SG_ 2559770675 P3_CellTemp99 "电池包3的单体温度99";
CM_ SG_ 2559770675 P3_CellTemp100 "电池包3的单体温度100";
CM_ SG_ 2559836211 P3_CellTemp101 "电池包3的单体温度101";
CM_ SG_ 2559836211 P3_CellTemp102 "电池包3的单体温度102";
CM_ SG_ 2559836211 P3_CellTemp103 "电池包3的单体温度103";
CM_ SG_ 2559836211 P3_CellTemp104 "电池包3的单体温度104";
CM_ SG_ 2559836211 P3_CellTemp105 "电池包3的单体温度105";
CM_ SG_ 2559901747 P3_CellTemp106 "电池包3的单体温度106";
CM_ SG_ 2559901747 P3_CellTemp107 "电池包3的单体温度107";
CM_ SG_ 2559901747 P3_CellTemp108 "电池包3的单体温度108";
CM_ SG_ 2559901747 P3_CellTemp109 "电池包3的单体温度109";
CM_ SG_ 2559901747 P3_CellTemp110 "电池包3的单体温度110";
CM_ SG_ 2559967283 P3_CellTemp111 "电池包3的单体温度111";
CM_ SG_ 2559967283 P3_CellTemp112 "电池包3的单体温度112";
CM_ SG_ 2559967283 P3_CellTemp113 "电池包3的单体温度113";
CM_ SG_ 2559967283 P3_CellTemp114 "电池包3的单体温度114";
CM_ SG_ 2559967283 P3_CellTemp115 "电池包3的单体温度115";
CM_ SG_ 2560032819 P3_CellTemp116 "电池包3的单体温度116";
CM_ SG_ 2560032819 P3_CellTemp117 "电池包3的单体温度117";
CM_ SG_ 2560032819 P3_CellTemp118 "电池包3的单体温度118";
CM_ SG_ 2560032819 P3_CellTemp119 "电池包3的单体温度119";
CM_ SG_ 2560032819 P3_CellTemp120 "电池包3的单体温度120";
CM_ SG_ 2560098355 P3_CellTemp121 "电池包3的单体温度121";
CM_ SG_ 2560098355 P3_CellTemp122 "电池包3的单体温度122";
CM_ SG_ 2560098355 P3_CellTemp123 "电池包3的单体温度123";
CM_ SG_ 2560098355 P3_CellTemp124 "电池包3的单体温度124";
CM_ SG_ 2560098355 P3_CellTemp125 "电池包3的单体温度125";
CM_ SG_ 2560163891 P3_CellTemp126 "电池包3的单体温度126";
CM_ SG_ 2560163891 P3_CellTemp127 "电池包3的单体温度127";
CM_ SG_ 2560163891 P3_CellTemp128 "电池包3的单体温度128";
CM_ SG_ 2560163891 P3_CellTemp129 "电池包3的单体温度129";
CM_ SG_ 2560163891 P3_CellTemp130 "电池包3的单体温度130";
CM_ SG_ 2560229427 P3_CellTemp131 "电池包3的单体温度131";
CM_ SG_ 2560229427 P3_CellTemp132 "电池包3的单体温度132";
CM_ SG_ 2560229427 P3_CellTemp133 "电池包3的单体温度133";
CM_ SG_ 2560229427 P3_CellTemp134 "电池包3的单体温度134";
CM_ SG_ 2560229427 P3_CellTemp135 "电池包3的单体温度135";
CM_ SG_ 2560294963 P3_CellTemp136 "电池包3的单体温度136";
CM_ SG_ 2560294963 P3_CellTemp137 "电池包3的单体温度137";
CM_ SG_ 2560294963 P3_CellTemp138 "电池包3的单体温度138";
CM_ SG_ 2560294963 P3_CellTemp139 "电池包3的单体温度139";
CM_ SG_ 2560294963 P3_CellTemp140 "电池包3的单体温度140";
CM_ SG_ 2560360499 P3_CellTemp141 "电池包3的单体温度141";
CM_ SG_ 2560360499 P3_CellTemp142 "电池包3的单体温度142";
CM_ SG_ 2560360499 P3_CellTemp143 "电池包3的单体温度143";
CM_ SG_ 2560360499 P3_CellTemp144 "电池包3的单体温度144";
CM_ SG_ 2560360499 P3_CellTemp145 "电池包3的单体温度145";
CM_ SG_ 2560426035 P3_CellTemp146 "电池包3的单体温度146";
CM_ SG_ 2560426035 P3_CellTemp147 "电池包3的单体温度147";
CM_ SG_ 2560426035 P3_CellTemp148 "电池包3的单体温度148";
CM_ SG_ 2560426035 P3_CellTemp149 "电池包3的单体温度149";
CM_ SG_ 2560426035 P3_CellTemp150 "电池包3的单体温度150";
CM_ SG_ 2560491571 P3_CellTemp151 "电池包3的单体温度151";
CM_ SG_ 2560491571 P3_CellTemp152 "电池包3的单体温度152";
CM_ SG_ 2560491571 P3_CellTemp153 "电池包3的单体温度153";
CM_ SG_ 2560491571 P3_CellTemp154 "电池包3的单体温度154";
CM_ SG_ 2560491571 P3_CellTemp155 "电池包3的单体温度155";
CM_ SG_ 2560557107 P3_CellTemp156 "电池包3的单体温度156";
CM_ SG_ 2560557107 P3_CellTemp157 "电池包3的单体温度157";
CM_ SG_ 2560557107 P3_CellTemp158 "电池包3的单体温度158";
CM_ SG_ 2560557107 P3_CellTemp159 "电池包3的单体温度159";
CM_ SG_ 2560557107 P3_CellTemp160 "电池包3的单体温度160";
CM_ SG_ 2560622643 P3_CellTemp161 "电池包3的单体温度161";
CM_ SG_ 2560622643 P3_CellTemp162 "电池包3的单体温度162";
CM_ SG_ 2560622643 P3_CellTemp163 "电池包3的单体温度163";
CM_ SG_ 2560622643 P3_CellTemp164 "电池包3的单体温度164";
CM_ SG_ 2560622643 P3_CellTemp165 "电池包3的单体温度165";
CM_ SG_ 2560688179 P3_CellTemp166 "电池包3的单体温度166";
CM_ SG_ 2560688179 P3_CellTemp167 "电池包3的单体温度167";
CM_ SG_ 2560688179 P3_CellTemp168 "电池包3的单体温度168";
CM_ SG_ 2560688179 P3_CellTemp169 "电池包3的单体温度169";
CM_ SG_ 2560688179 P3_CellTemp170 "电池包3的单体温度170";
CM_ SG_ 2560753715 P3_CellTemp171 "电池包3的单体温度171";
CM_ SG_ 2560753715 P3_CellTemp172 "电池包3的单体温度172";
CM_ SG_ 2560753715 P3_CellTemp173 "电池包3的单体温度173";
CM_ SG_ 2560753715 P3_CellTemp174 "电池包3的单体温度174";
CM_ SG_ 2560753715 P3_CellTemp175 "电池包3的单体温度175";
CM_ SG_ 2560819251 P3_CellTemp176 "电池包3的单体温度176";
CM_ SG_ 2560819251 P3_CellTemp177 "电池包3的单体温度177";
CM_ SG_ 2560819251 P3_CellTemp178 "电池包3的单体温度178";
CM_ SG_ 2560819251 P3_CellTemp179 "电池包3的单体温度179";
CM_ SG_ 2560819251 P3_CellTemp180 "电池包3的单体温度180";
CM_ SG_ 2560884787 P3_CellTemp181 "电池包3的单体温度181";
CM_ SG_ 2560884787 P3_CellTemp182 "电池包3的单体温度182";
CM_ SG_ 2560884787 P3_CellTemp183 "电池包3的单体温度183";
CM_ SG_ 2560884787 P3_CellTemp184 "电池包3的单体温度184";
CM_ SG_ 2560884787 P3_CellTemp185 "电池包3的单体温度185";
CM_ SG_ 2560950323 P3_CellTemp186 "电池包3的单体温度186";
CM_ SG_ 2560950323 P3_CellTemp187 "电池包3的单体温度187";
CM_ SG_ 2560950323 P3_CellTemp188 "电池包3的单体温度188";
CM_ SG_ 2560950323 P3_CellTemp189 "电池包3的单体温度189";
CM_ SG_ 2560950323 P3_CellTemp190 "电池包3的单体温度190";
CM_ SG_ 2561015859 P3_CellTemp191 "电池包3的单体温度191";
CM_ SG_ 2561015859 P3_CellTemp192 "电池包3的单体温度192";
CM_ SG_ 2561015859 P3_DatLen16DbgInfo1 "长度为16的调试信息1";
CM_ SG_ 2561015859 P3_DatLen16DbgInfo2 "长度为16的调试信息2";
CM_ SG_ 2561015859 P3_DatLen16DbgInfo3 "长度为16的调试信息3";
CM_ SG_ 2561015859 P3_DatLen16DbgInfo4 "长度为16的调试信息4";
CM_ SG_ 2550399044 P4_BMSPwrSuplVlt1 "电池包4的BMS供电电源电压1";
CM_ SG_ 2550399044 P4_BMSPwrSuplVlt2 "电池包4的BMS供电电源电压2";
CM_ SG_ 2550399044 P4_ChrgStationAuxPwrSuplVlt "电池包4的快充桩A+电压";
CM_ SG_ 2550399044 P4_BMSKL15ON "电池包4的BMS唤醒信号";
CM_ SG_ 2550399044 P4_DCStepState "电池包4的充电状态机";
CM_ SG_ 2550399044 P4_ExtLvWakeup_28VOnly "电池包4的外部唤醒";
CM_ SG_ 2550464580 P4_PackVltUprLmt "电池包4的电压使用上限";
CM_ SG_ 2550464580 P4_PackVltLoLmt "电池包4的电压使用下限";
CM_ SG_ 2550464580 P4_PackMaxDschrgCrnt "电池包4的最大允许放电电流";
CM_ SG_ 2550464580 P4_PackMaxChrgCrnt "电池包4的最大允许充电电流";
CM_ SG_ 2550530116 P4_PackDschrgPwrLmt "电池包4的放电功率限值";
CM_ SG_ 2550530116 P4_PackDschrgPwrStat "电池包4的放电功率状态";
CM_ SG_ 2550530116 P4_PackChrgPwrLmt "电池包4的充电功率限值";
CM_ SG_ 2550530116 P4_PackChrgPwrStat "电池包4的充电功率状态";
CM_ SG_ 2550595652 P4_ChrgrCplrStat "电池包4的充电枪连接状态";
CM_ SG_ 2550595652 P4_HVBattChrgSysStatus "电池包4的充电系统状态";
CM_ SG_ 2550595652 P4_DCChrgCrntCmd "电池包4的直流充电请求电流";
CM_ SG_ 2550595652 P4_CC2Vlt "电池包4的CC2电压值";
CM_ SG_ 2550595652 P4_DCRcptPosTemp "电池包4的快充充电插座正极温度";
CM_ SG_ 2550595652 P4_DCRcptNegTemp "电池包4的快充充电插座负极温度";
CM_ SG_ 2550595652 P4_Tm2FullChrg "电池包4满充剩余时间";
CM_ SG_ 2550661188 P4_Inlet1ClntTemp "进水口1冷却液温度";
CM_ SG_ 2550661188 P4_Inlet2ClntTemp "进水口2冷却液温度";
CM_ SG_ 2550661188 P4_Outlet1ClntTemp "出水口1冷却液温度";
CM_ SG_ 2550661188 P4_Outlet2ClntTemp "出水口2冷却液温度";
CM_ SG_ 2550661188 P4_TrgtClntTemp "冷却水目标温度";
CM_ SG_ 2550661188 P4_TrgtClntFlowRate "冷却水目标流量";
CM_ SG_ 2550726724 P4_MaxCellVlt "电池包4的最大单体电压";
CM_ SG_ 2550726724 P4_MaxCellVltNum "电池包4的最大单体电压编号";
CM_ SG_ 2550726724 P4_MinCellVlt "电池包4的最小单体电压";
CM_ SG_ 2550726724 P4_MinCellVltNum "电池包4的最小单体电压编号";
CM_ SG_ 2550726724 P4_AvgCellVlt "电池包4的平均单体电压";
CM_ SG_ 2550792260 P4_MaxCellTemp "电池包4的最高单体温度";
CM_ SG_ 2550792260 P4_MaxCellTempNum "电池包4的最高单体温度编号";
CM_ SG_ 2550792260 P4_MinCellTemp "电池包4的最低单体温度";
CM_ SG_ 2550792260 P4_MinCellTempNum "电池包4的最低单体温度编号";
CM_ SG_ 2550792260 P4_AvgCellTemp "电池包4的单体平均温度";
CM_ SG_ 2550857796 P4_PackTotFltNum "电池包4的电池故障总数";
CM_ SG_ 2550857796 P4_CellOverVoltage "电池包4的单体过压";
CM_ SG_ 2550857796 P4_CellUnderVoltage "电池包4的单体欠压";
CM_ SG_ 2550857796 P4_CellVoltageDiffHi "电池包4的单体压差过大";
CM_ SG_ 2550857796 P4_PackOverVoltage "电池包4的电压过高";
CM_ SG_ 2550857796 P4_PackUnderVoltage "电池包4的电压过低";
CM_ SG_ 2550857796 P4_CellOverTemp "电池包4的单体过温";
CM_ SG_ 2550857796 P4_CellTempLow "电池包4的单体温度过低";
CM_ SG_ 2550857796 P4_CellTempDiffHi "电池包4的单体温度差异过大";
CM_ SG_ 2550857796 P4_PackDschrgCrntHi "电池包4的放电电流过流";
CM_ SG_ 2550857796 P4_PackChrgCrntHi "电池包4的充电电流过流";
CM_ SG_ 2550857796 P4_PackCrnSnsr1OffsetHi "电池包4的电流传感器1零漂过大";
CM_ SG_ 2550857796 P4_HVIsolFlt "电池包4的高压绝缘故障";
CM_ SG_ 2550857796 P4_HVILFlt "电池包4的高压互锁故障";
CM_ SG_ 2550857796 P4_ThrmlRunaway "电池包4的热失控故障";
CM_ SG_ 2550857796 P4_CellVoltInvalid "电池包4的单体电压采样失效";
CM_ SG_ 2550857796 P4_CellTempInvalid "电池包4的电芯温度采样失效";
CM_ SG_ 2550857796 P4_DaisyChainComFlt "电池包4的菊花链通信故障";
CM_ SG_ 2550857796 P4_PackVoltRatFlt "电池包4的总电压与单体电压总和偏差过大";
CM_ SG_ 2550857796 P4_CrntSnsr1Invalid "电池包4的电流传感器1电流采样失效";
CM_ SG_ 2550857796 P4_CrntSnsr1OOR "电池包4的电流传感器1电流超出采样范围";
CM_ SG_ 2550857796 P4_CrntSnsr2Invalid "电池包4的电流传感器2电流采样失效";
CM_ SG_ 2550857796 P4_CrntSnsr2OOR "电池包4的电流传感器2电流超出采样范围";
CM_ SG_ 2550857796 P4_PackCrnSnsr2OffsetHi "电池包4的电流传感器2零漂过大";
CM_ SG_ 2550857796 P4_OutofEnergy "电池包4的电池剩余电量低";
CM_ SG_ 2550857796 P4_IsolDetCircErr "电池包4的绝缘检测电路失效";
CM_ SG_ 2550857796 P4_HVILCircShortToGND "电池包4的高压互锁对地短路";
CM_ SG_ 2550857796 P4_HVILCircShortToPwr "电池包4的高压互锁对电源短路";
CM_ SG_ 2550923332 P4_MainPosCntctrStkClsd "电池包4的主正继电器粘连故障";
CM_ SG_ 2550923332 P4_MainPosCntctrStkOpn "电池包4的主正继电器常开故障";
CM_ SG_ 2550923332 P4_MainNegCntctr1StkClsd "电池包4的主负继电器1粘连故障";
CM_ SG_ 2550923332 P4_MainNegCntctr1StkOpn "电池包4的主负继电器1常开故障";
CM_ SG_ 2550923332 P4_MainNegCntctr2StkClsd "电池包4的主负继电器2粘连故障";
CM_ SG_ 2550923332 P4_MainNegCntctr2StkOpn "电池包4的主负继电器2常开故障";
CM_ SG_ 2550923332 P4_PrechargTmOut "电池包4的预充超时故障";
CM_ SG_ 2550923332 P4_PrechrgCrntHi "电池包4的预充过流故障";
CM_ SG_ 2550923332 P4_ChrgCplrPosTempHi "电池包4的充电正极接口温度过高故障";
CM_ SG_ 2550923332 P4_ChrgCplrNegTempHi "电池包4的充电负极接口温度过高故障";
CM_ SG_ 2550923332 P4_BMSPwrSuplVlt1Hi "电池包4的BMS供电电压1过高";
CM_ SG_ 2550923332 P4_BMSPwrSuplVlt1Lo "电池包4的BMS供电电压1过低";
CM_ SG_ 2550923332 P4_BMSPwrSuplVlt2Hi "电池包4的BMS供电电压2过高";
CM_ SG_ 2550923332 P4_BMSPwrSuplVlt2Lo "电池包4的BMS供电电压2过低";
CM_ SG_ 2550923332 P4_CntctrCirPwrSuplVltLo "电池包4的继电器驱动供电电压过低";
CM_ SG_ 2550923332 P4_CntctrCirPwrSuplVltHi "电池包4的继电器驱动供电电压过高";
CM_ SG_ 2550923332 P4_CAN1BusOff "电池包4的CAN1通信Bus off";
CM_ SG_ 2550923332 P4_CAN1BusTmOut "电池包4的CAN1报文超时（Timeout）";
CM_ SG_ 2550923332 P4_CAN2BusOff "电池包4的CAN2通信Bus off";
CM_ SG_ 2550923332 P4_CAN2BusTmOut "电池包4的CAN2报文超时（Timeout）";
CM_ SG_ 2550923332 P4_CellBalCircTempHi "电池包4的均衡电路过温";
CM_ SG_ 2550923332 P4_ClntInTempHi "电池包4的入水口温度过高";
CM_ SG_ 2550923332 P4_ClntOutTempHi "电池包4的出水口温度过高";
CM_ SG_ 2550923332 P4_CellExtrmUdrVolt "电池包4的单体极限欠压";
CM_ SG_ 2550923332 P4_CellExtrmOvrVolt "电池包4的单体极限过压";
CM_ SG_ 2550923332 P4_Branch1DischrgCrntHi  "电池包4的支路1放电过流";
CM_ SG_ 2550923332 P4_Branch2DischrgCrntHi  "电池包4的支路2放电过流";
CM_ SG_ 2550923332 P4_Branch1ChrgCrntHi  "电池包4的支路1充电过流";
CM_ SG_ 2550923332 P4_Branch2ChrgCrntHi  "电池包4的支路2充电过流";
CM_ SG_ 2550923332 P4_InitFailed "电池包4的BMS初始化失败";
CM_ SG_ 2550923332 P4_PackErrCode "电池包4的故障代码";
CM_ SG_ 2550988868 P4_PackTotCellNum "电池包4的单体电池总数";
CM_ SG_ 2550988868 P4_PackTotCellTempSnsrNum "电池包4的单体温度传感器总数";
CM_ SG_ 2552299588 P4_BMSASWMajVerNum "电池包4的BMS应用层软件主版本号";
CM_ SG_ 2552299588 P4_BMSASWMinVerNum "电池包4的BMS应用层软件子版本号";
CM_ SG_ 2552299588 P4_BMSASWPatchVerNum "电池包4的BMS应用层软件修订版本号";
CM_ SG_ 2552299588 P4_BMSBSWMajVerNum "电池包4的BMS底层软件主版本号";
CM_ SG_ 2552299588 P4_BMSBSWMinVerNum "电池包4的BMS底层软件子版本号";
CM_ SG_ 2552299588 P4_BMSBSWPatchVerNum "电池包4的BMS底层软件修订版本号";
CM_ SG_ 2554396740 P4_CellVoltage1 "电池包4的单体电压1";
CM_ SG_ 2554396740 P4_CellVoltage2 "电池包4的单体电压2";
CM_ SG_ 2554396740 P4_CellVoltage3 "电池包4的单体电压3";
CM_ SG_ 2554396740 P4_CellVoltage4 "电池包4的单体电压4";
CM_ SG_ 2554396740 P4_BalSwCell1 "电池包4的电芯1均衡状态";
CM_ SG_ 2554396740 P4_BalSwCell2 "电池包4的电芯2均衡状态";
CM_ SG_ 2554396740 P4_BalSwCell3 "电池包4的电芯3均衡状态";
CM_ SG_ 2554396740 P4_BalSwCell4 "电池包4的电芯4均衡状态";
CM_ SG_ 2554462276 P4_CellVoltage5 "电池包4的单体电压5";
CM_ SG_ 2554462276 P4_CellVoltage6 "电池包4的单体电压6";
CM_ SG_ 2554462276 P4_CellVoltage7 "电池包4的单体电压7";
CM_ SG_ 2554462276 P4_CellVoltage8 "电池包4的单体电压8";
CM_ SG_ 2554462276 P4_BalSwCell5 "电池包4的电芯5均衡状态";
CM_ SG_ 2554462276 P4_BalSwCell6 "电池包4的电芯6均衡状态";
CM_ SG_ 2554462276 P4_BalSwCell7 "电池包4的电芯7均衡状态";
CM_ SG_ 2554462276 P4_BalSwCell8 "电池包4的电芯8均衡状态";
CM_ SG_ 2554527812 P4_CellVoltage9 "电池包4的单体电压9";
CM_ SG_ 2554527812 P4_CellVoltage10 "电池包4的单体电压10";
CM_ SG_ 2554527812 P4_CellVoltage11 "电池包4的单体电压11";
CM_ SG_ 2554527812 P4_CellVoltage12 "电池包4的单体电压12";
CM_ SG_ 2554527812 P4_BalSwCell9 "电池包4的电芯9均衡状态";
CM_ SG_ 2554527812 P4_BalSwCell10 "电池包4的电芯10均衡状态";
CM_ SG_ 2554527812 P4_BalSwCell11 "电池包4的电芯11均衡状态";
CM_ SG_ 2554527812 P4_BalSwCell12 "电池包4的电芯12均衡状态";
CM_ SG_ 2554593348 P4_CellVoltage13 "电池包4的单体电压13";
CM_ SG_ 2554593348 P4_CellVoltage14 "电池包4的单体电压14";
CM_ SG_ 2554593348 P4_CellVoltage15 "电池包4的单体电压15";
CM_ SG_ 2554593348 P4_CellVoltage16 "电池包4的单体电压16";
CM_ SG_ 2554593348 P4_BalSwCell13 "电池包4的电芯13均衡状态";
CM_ SG_ 2554593348 P4_BalSwCell14 "电池包4的电芯14均衡状态";
CM_ SG_ 2554593348 P4_BalSwCell15 "电池包4的电芯15均衡状态";
CM_ SG_ 2554593348 P4_BalSwCell16 "电池包4的电芯16均衡状态";
CM_ SG_ 2554658884 P4_CellVoltage17 "电池包4的单体电压17";
CM_ SG_ 2554658884 P4_CellVoltage18 "电池包4的单体电压18";
CM_ SG_ 2554658884 P4_CellVoltage19 "电池包4的单体电压19";
CM_ SG_ 2554658884 P4_CellVoltage20 "电池包4的单体电压20";
CM_ SG_ 2554658884 P4_BalSwCell17 "电池包4的电芯17均衡状态";
CM_ SG_ 2554658884 P4_BalSwCell18 "电池包4的电芯18均衡状态";
CM_ SG_ 2554658884 P4_BalSwCell19 "电池包4的电芯19均衡状态";
CM_ SG_ 2554658884 P4_BalSwCell20 "电池包4的电芯20均衡状态";
CM_ SG_ 2554724420 P4_CellVoltage21 "电池包4的单体电压21";
CM_ SG_ 2554724420 P4_CellVoltage22 "电池包4的单体电压22";
CM_ SG_ 2554724420 P4_CellVoltage23 "电池包4的单体电压23";
CM_ SG_ 2554724420 P4_CellVoltage24 "电池包4的单体电压24";
CM_ SG_ 2554724420 P4_BalSwCell21 "电池包4的电芯21均衡状态";
CM_ SG_ 2554724420 P4_BalSwCell22 "电池包4的电芯22均衡状态";
CM_ SG_ 2554724420 P4_BalSwCell23 "电池包4的电芯23均衡状态";
CM_ SG_ 2554724420 P4_BalSwCell24 "电池包4的电芯24均衡状态";
CM_ SG_ 2554789956 P4_CellVoltage25 "电池包4的单体电压25";
CM_ SG_ 2554789956 P4_CellVoltage26 "电池包4的单体电压26";
CM_ SG_ 2554789956 P4_CellVoltage27 "电池包4的单体电压27";
CM_ SG_ 2554789956 P4_CellVoltage28 "电池包4的单体电压28";
CM_ SG_ 2554789956 P4_BalSwCell25 "电池包4的电芯25均衡状态";
CM_ SG_ 2554789956 P4_BalSwCell26 "电池包4的电芯26均衡状态";
CM_ SG_ 2554789956 P4_BalSwCell27 "电池包4的电芯27均衡状态";
CM_ SG_ 2554789956 P4_BalSwCell28 "电池包4的电芯28均衡状态";
CM_ SG_ 2554855492 P4_CellVoltage29 "电池包4的单体电压29";
CM_ SG_ 2554855492 P4_CellVoltage30 "电池包4的单体电压30";
CM_ SG_ 2554855492 P4_CellVoltage31 "电池包4的单体电压31";
CM_ SG_ 2554855492 P4_CellVoltage32 "电池包4的单体电压32";
CM_ SG_ 2554855492 P4_BalSwCell29 "电池包4的电芯29均衡状态";
CM_ SG_ 2554855492 P4_BalSwCell30 "电池包4的电芯30均衡状态";
CM_ SG_ 2554855492 P4_BalSwCell31 "电池包4的电芯31均衡状态";
CM_ SG_ 2554855492 P4_BalSwCell32 "电池包4的电芯32均衡状态";
CM_ SG_ 2554921028 P4_CellVoltage33 "电池包4的单体电压33";
CM_ SG_ 2554921028 P4_CellVoltage34 "电池包4的单体电压34";
CM_ SG_ 2554921028 P4_CellVoltage35 "电池包4的单体电压35";
CM_ SG_ 2554921028 P4_CellVoltage36 "电池包4的单体电压36";
CM_ SG_ 2554921028 P4_BalSwCell33 "电池包4的电芯33均衡状态";
CM_ SG_ 2554921028 P4_BalSwCell34 "电池包4的电芯34均衡状态";
CM_ SG_ 2554921028 P4_BalSwCell35 "电池包4的电芯35均衡状态";
CM_ SG_ 2554921028 P4_BalSwCell36 "电池包4的电芯36均衡状态";
CM_ SG_ 2554986564 P4_CellVoltage37 "电池包4的单体电压37";
CM_ SG_ 2554986564 P4_CellVoltage38 "电池包4的单体电压38";
CM_ SG_ 2554986564 P4_CellVoltage39 "电池包4的单体电压39";
CM_ SG_ 2554986564 P4_CellVoltage40 "电池包4的单体电压40";
CM_ SG_ 2554986564 P4_BalSwCell37 "电池包4的电芯37均衡状态";
CM_ SG_ 2554986564 P4_BalSwCell38 "电池包4的电芯38均衡状态";
CM_ SG_ 2554986564 P4_BalSwCell39 "电池包4的电芯39均衡状态";
CM_ SG_ 2554986564 P4_BalSwCell40 "电池包4的电芯40均衡状态";
CM_ SG_ 2555052100 P4_CellVoltage41 "电池包4的单体电压41";
CM_ SG_ 2555052100 P4_CellVoltage42 "电池包4的单体电压42";
CM_ SG_ 2555052100 P4_CellVoltage43 "电池包4的单体电压43";
CM_ SG_ 2555052100 P4_CellVoltage44 "电池包4的单体电压44";
CM_ SG_ 2555052100 P4_BalSwCell41 "电池包4的电芯41均衡状态";
CM_ SG_ 2555052100 P4_BalSwCell42 "电池包4的电芯42均衡状态";
CM_ SG_ 2555052100 P4_BalSwCell43 "电池包4的电芯43均衡状态";
CM_ SG_ 2555052100 P4_BalSwCell44 "电池包4的电芯44均衡状态";
CM_ SG_ 2555117636 P4_CellVoltage45 "电池包4的单体电压45";
CM_ SG_ 2555117636 P4_CellVoltage46 "电池包4的单体电压46";
CM_ SG_ 2555117636 P4_CellVoltage47 "电池包4的单体电压47";
CM_ SG_ 2555117636 P4_CellVoltage48 "电池包4的单体电压48";
CM_ SG_ 2555117636 P4_BalSwCell45 "电池包4的电芯45均衡状态";
CM_ SG_ 2555117636 P4_BalSwCell46 "电池包4的电芯46均衡状态";
CM_ SG_ 2555117636 P4_BalSwCell47 "电池包4的电芯47均衡状态";
CM_ SG_ 2555117636 P4_BalSwCell48 "电池包4的电芯48均衡状态";
CM_ SG_ 2555183172 P4_CellVoltage49 "电池包4的单体电压49";
CM_ SG_ 2555183172 P4_CellVoltage50 "电池包4的单体电压50";
CM_ SG_ 2555183172 P4_CellVoltage51 "电池包4的单体电压51";
CM_ SG_ 2555183172 P4_CellVoltage52 "电池包4的单体电压52";
CM_ SG_ 2555183172 P4_BalSwCell49 "电池包4的电芯49均衡状态";
CM_ SG_ 2555183172 P4_BalSwCell50 "电池包4的电芯50均衡状态";
CM_ SG_ 2555183172 P4_BalSwCell51 "电池包4的电芯51均衡状态";
CM_ SG_ 2555183172 P4_BalSwCell52 "电池包4的电芯52均衡状态";
CM_ SG_ 2555248708 P4_CellVoltage53 "电池包4的单体电压53";
CM_ SG_ 2555248708 P4_CellVoltage54 "电池包4的单体电压54";
CM_ SG_ 2555248708 P4_CellVoltage55 "电池包4的单体电压55";
CM_ SG_ 2555248708 P4_CellVoltage56 "电池包4的单体电压56";
CM_ SG_ 2555248708 P4_BalSwCell53 "电池包4的电芯53均衡状态";
CM_ SG_ 2555248708 P4_BalSwCell54 "电池包4的电芯54均衡状态";
CM_ SG_ 2555248708 P4_BalSwCell55 "电池包4的电芯55均衡状态";
CM_ SG_ 2555248708 P4_BalSwCell56 "电池包4的电芯56均衡状态";
CM_ SG_ 2555314244 P4_CellVoltage57 "电池包4的单体电压57";
CM_ SG_ 2555314244 P4_CellVoltage58 "电池包4的单体电压58";
CM_ SG_ 2555314244 P4_CellVoltage59 "电池包4的单体电压59";
CM_ SG_ 2555314244 P4_CellVoltage60 "电池包4的单体电压60";
CM_ SG_ 2555314244 P4_BalSwCell57 "电池包4的电芯57均衡状态";
CM_ SG_ 2555314244 P4_BalSwCell58 "电池包4的电芯58均衡状态";
CM_ SG_ 2555314244 P4_BalSwCell59 "电池包4的电芯59均衡状态";
CM_ SG_ 2555314244 P4_BalSwCell60 "电池包4的电芯60均衡状态";
CM_ SG_ 2555379780 P4_CellVoltage61 "电池包4的单体电压61";
CM_ SG_ 2555379780 P4_CellVoltage62 "电池包4的单体电压62";
CM_ SG_ 2555379780 P4_CellVoltage63 "电池包4的单体电压63";
CM_ SG_ 2555379780 P4_CellVoltage64 "电池包4的单体电压64";
CM_ SG_ 2555379780 P4_BalSwCell61 "电池包4的电芯61均衡状态";
CM_ SG_ 2555379780 P4_BalSwCell62 "电池包4的电芯62均衡状态";
CM_ SG_ 2555379780 P4_BalSwCell63 "电池包4的电芯63均衡状态";
CM_ SG_ 2555379780 P4_BalSwCell64 "电池包4的电芯64均衡状态";
CM_ SG_ 2555445316 P4_CellVoltage65 "电池包4的单体电压65";
CM_ SG_ 2555445316 P4_CellVoltage66 "电池包4的单体电压66";
CM_ SG_ 2555445316 P4_CellVoltage67 "电池包4的单体电压67";
CM_ SG_ 2555445316 P4_CellVoltage68 "电池包4的单体电压68";
CM_ SG_ 2555445316 P4_BalSwCell65 "电池包4的电芯65均衡状态";
CM_ SG_ 2555445316 P4_BalSwCell66 "电池包4的电芯66均衡状态";
CM_ SG_ 2555445316 P4_BalSwCell67 "电池包4的电芯67均衡状态";
CM_ SG_ 2555445316 P4_BalSwCell68 "电池包4的电芯68均衡状态";
CM_ SG_ 2555510852 P4_CellVoltage69 "电池包4的单体电压69";
CM_ SG_ 2555510852 P4_CellVoltage70 "电池包4的单体电压70";
CM_ SG_ 2555510852 P4_CellVoltage71 "电池包4的单体电压71";
CM_ SG_ 2555510852 P4_CellVoltage72 "电池包4的单体电压72";
CM_ SG_ 2555510852 P4_BalSwCell69 "电池包4的电芯69均衡状态";
CM_ SG_ 2555510852 P4_BalSwCell70 "电池包4的电芯70均衡状态";
CM_ SG_ 2555510852 P4_BalSwCell71 "电池包4的电芯71均衡状态";
CM_ SG_ 2555510852 P4_BalSwCell72 "电池包4的电芯72均衡状态";
CM_ SG_ 2555576388 P4_CellVoltage73 "电池包4的单体电压73";
CM_ SG_ 2555576388 P4_CellVoltage74 "电池包4的单体电压74";
CM_ SG_ 2555576388 P4_CellVoltage75 "电池包4的单体电压75";
CM_ SG_ 2555576388 P4_CellVoltage76 "电池包4的单体电压76";
CM_ SG_ 2555576388 P4_BalSwCell73 "电池包4的电芯73均衡状态";
CM_ SG_ 2555576388 P4_BalSwCell74 "电池包4的电芯74均衡状态";
CM_ SG_ 2555576388 P4_BalSwCell75 "电池包4的电芯75均衡状态";
CM_ SG_ 2555576388 P4_BalSwCell76 "电池包4的电芯76均衡状态";
CM_ SG_ 2555641924 P4_CellVoltage77 "电池包4的单体电压77";
CM_ SG_ 2555641924 P4_CellVoltage78 "电池包4的单体电压78";
CM_ SG_ 2555641924 P4_CellVoltage79 "电池包4的单体电压79";
CM_ SG_ 2555641924 P4_CellVoltage80 "电池包4的单体电压80";
CM_ SG_ 2555641924 P4_BalSwCell77 "电池包4的电芯77均衡状态";
CM_ SG_ 2555641924 P4_BalSwCell78 "电池包4的电芯78均衡状态";
CM_ SG_ 2555641924 P4_BalSwCell79 "电池包4的电芯79均衡状态";
CM_ SG_ 2555641924 P4_BalSwCell80 "电池包4的电芯80均衡状态";
CM_ SG_ 2555707460 P4_CellVoltage81 "电池包4的单体电压81";
CM_ SG_ 2555707460 P4_CellVoltage82 "电池包4的单体电压82";
CM_ SG_ 2555707460 P4_CellVoltage83 "电池包4的单体电压83";
CM_ SG_ 2555707460 P4_CellVoltage84 "电池包4的单体电压84";
CM_ SG_ 2555707460 P4_BalSwCell81 "电池包4的电芯81均衡状态";
CM_ SG_ 2555707460 P4_BalSwCell82 "电池包4的电芯82均衡状态";
CM_ SG_ 2555707460 P4_BalSwCell83 "电池包4的电芯83均衡状态";
CM_ SG_ 2555707460 P4_BalSwCell84 "电池包4的电芯84均衡状态";
CM_ SG_ 2555772996 P4_CellVoltage85 "电池包4的单体电压85";
CM_ SG_ 2555772996 P4_CellVoltage86 "电池包4的单体电压86";
CM_ SG_ 2555772996 P4_CellVoltage87 "电池包4的单体电压87";
CM_ SG_ 2555772996 P4_CellVoltage88 "电池包4的单体电压88";
CM_ SG_ 2555772996 P4_BalSwCell85 "电池包4的电芯85均衡状态";
CM_ SG_ 2555772996 P4_BalSwCell86 "电池包4的电芯86均衡状态";
CM_ SG_ 2555772996 P4_BalSwCell87 "电池包4的电芯87均衡状态";
CM_ SG_ 2555772996 P4_BalSwCell88 "电池包4的电芯88均衡状态";
CM_ SG_ 2555838532 P4_CellVoltage89 "电池包4的单体电压89";
CM_ SG_ 2555838532 P4_CellVoltage90 "电池包4的单体电压90";
CM_ SG_ 2555838532 P4_CellVoltage91 "电池包4的单体电压91";
CM_ SG_ 2555838532 P4_CellVoltage92 "电池包4的单体电压92";
CM_ SG_ 2555838532 P4_BalSwCell89 "电池包4的电芯89均衡状态";
CM_ SG_ 2555838532 P4_BalSwCell90 "电池包4的电芯90均衡状态";
CM_ SG_ 2555838532 P4_BalSwCell91 "电池包4的电芯91均衡状态";
CM_ SG_ 2555838532 P4_BalSwCell92 "电池包4的电芯92均衡状态";
CM_ SG_ 2555904068 P4_CellVoltage93 "电池包4的单体电压93";
CM_ SG_ 2555904068 P4_CellVoltage94 "电池包4的单体电压94";
CM_ SG_ 2555904068 P4_CellVoltage95 "电池包4的单体电压95";
CM_ SG_ 2555904068 P4_CellVoltage96 "电池包4的单体电压96";
CM_ SG_ 2555904068 P4_BalSwCell93 "电池包4的电芯93均衡状态";
CM_ SG_ 2555904068 P4_BalSwCell94 "电池包4的电芯94均衡状态";
CM_ SG_ 2555904068 P4_BalSwCell95 "电池包4的电芯95均衡状态";
CM_ SG_ 2555904068 P4_BalSwCell96 "电池包4的电芯96均衡状态";
CM_ SG_ 2555969604 P4_CellVoltage97 "电池包4的单体电压97";
CM_ SG_ 2555969604 P4_CellVoltage98 "电池包4的单体电压98";
CM_ SG_ 2555969604 P4_CellVoltage99 "电池包4的单体电压99";
CM_ SG_ 2555969604 P4_CellVoltage100 "电池包4的单体电压100";
CM_ SG_ 2555969604 P4_BalSwCell97 "电池包4的电芯97均衡状态";
CM_ SG_ 2555969604 P4_BalSwCell98 "电池包4的电芯98均衡状态";
CM_ SG_ 2555969604 P4_BalSwCell99 "电池包4的电芯99均衡状态";
CM_ SG_ 2555969604 P4_BalSwCell100 "电池包4的电芯100均衡状态";
CM_ SG_ 2556035140 P4_CellVoltage101 "电池包4的单体电压101";
CM_ SG_ 2556035140 P4_CellVoltage102 "电池包4的单体电压102";
CM_ SG_ 2556035140 P4_CellVoltage103 "电池包4的单体电压103";
CM_ SG_ 2556035140 P4_CellVoltage104 "电池包4的单体电压104";
CM_ SG_ 2556035140 P4_BalSwCell101 "电池包4的电芯101均衡状态";
CM_ SG_ 2556035140 P4_BalSwCell102 "电池包4的电芯102均衡状态";
CM_ SG_ 2556035140 P4_BalSwCell103 "电池包4的电芯103均衡状态";
CM_ SG_ 2556035140 P4_BalSwCell104 "电池包4的电芯104均衡状态";
CM_ SG_ 2556100676 P4_CellVoltage105 "电池包4的单体电压105";
CM_ SG_ 2556100676 P4_CellVoltage106 "电池包4的单体电压106";
CM_ SG_ 2556100676 P4_CellVoltage107 "电池包4的单体电压107";
CM_ SG_ 2556100676 P4_CellVoltage108 "电池包4的单体电压108";
CM_ SG_ 2556100676 P4_BalSwCell105 "电池包4的电芯105均衡状态";
CM_ SG_ 2556100676 P4_BalSwCell106 "电池包4的电芯106均衡状态";
CM_ SG_ 2556100676 P4_BalSwCell107 "电池包4的电芯107均衡状态";
CM_ SG_ 2556100676 P4_BalSwCell108 "电池包4的电芯108均衡状态";
CM_ SG_ 2556166212 P4_CellVoltage109 "电池包4的单体电压109";
CM_ SG_ 2556166212 P4_CellVoltage110 "电池包4的单体电压110";
CM_ SG_ 2556166212 P4_CellVoltage111 "电池包4的单体电压111";
CM_ SG_ 2556166212 P4_CellVoltage112 "电池包4的单体电压112";
CM_ SG_ 2556166212 P4_BalSwCell109 "电池包4的电芯109均衡状态";
CM_ SG_ 2556166212 P4_BalSwCell110 "电池包4的电芯110均衡状态";
CM_ SG_ 2556166212 P4_BalSwCell111 "电池包4的电芯111均衡状态";
CM_ SG_ 2556166212 P4_BalSwCell112 "电池包4的电芯112均衡状态";
CM_ SG_ 2556231748 P4_CellVoltage113 "电池包4的单体电压113";
CM_ SG_ 2556231748 P4_CellVoltage114 "电池包4的单体电压114";
CM_ SG_ 2556231748 P4_CellVoltage115 "电池包4的单体电压115";
CM_ SG_ 2556231748 P4_CellVoltage116 "电池包4的单体电压116";
CM_ SG_ 2556231748 P4_BalSwCell113 "电池包4的电芯113均衡状态";
CM_ SG_ 2556231748 P4_BalSwCell114 "电池包4的电芯114均衡状态";
CM_ SG_ 2556231748 P4_BalSwCell115 "电池包4的电芯115均衡状态";
CM_ SG_ 2556231748 P4_BalSwCell116 "电池包4的电芯116均衡状态";
CM_ SG_ 2556297284 P4_CellVoltage117 "电池包4的单体电压117";
CM_ SG_ 2556297284 P4_CellVoltage118 "电池包4的单体电压118";
CM_ SG_ 2556297284 P4_CellVoltage119 "电池包4的单体电压119";
CM_ SG_ 2556297284 P4_CellVoltage120 "电池包4的单体电压120";
CM_ SG_ 2556297284 P4_BalSwCell117 "电池包4的电芯117均衡状态";
CM_ SG_ 2556297284 P4_BalSwCell118 "电池包4的电芯118均衡状态";
CM_ SG_ 2556297284 P4_BalSwCell119 "电池包4的电芯119均衡状态";
CM_ SG_ 2556297284 P4_BalSwCell120 "电池包4的电芯120均衡状态";
CM_ SG_ 2556362820 P4_CellVoltage121 "电池包4的单体电压121";
CM_ SG_ 2556362820 P4_CellVoltage122 "电池包4的单体电压122";
CM_ SG_ 2556362820 P4_CellVoltage123 "电池包4的单体电压123";
CM_ SG_ 2556362820 P4_CellVoltage124 "电池包4的单体电压124";
CM_ SG_ 2556362820 P4_BalSwCell121 "电池包4的电芯121均衡状态";
CM_ SG_ 2556362820 P4_BalSwCell122 "电池包4的电芯122均衡状态";
CM_ SG_ 2556362820 P4_BalSwCell123 "电池包4的电芯123均衡状态";
CM_ SG_ 2556362820 P4_BalSwCell124 "电池包4的电芯124均衡状态";
CM_ SG_ 2556428356 P4_CellVoltage125 "电池包4的单体电压125";
CM_ SG_ 2556428356 P4_CellVoltage126 "电池包4的单体电压126";
CM_ SG_ 2556428356 P4_CellVoltage127 "电池包4的单体电压127";
CM_ SG_ 2556428356 P4_CellVoltage128 "电池包4的单体电压128";
CM_ SG_ 2556428356 P4_BalSwCell125 "电池包4的电芯125均衡状态";
CM_ SG_ 2556428356 P4_BalSwCell126 "电池包4的电芯126均衡状态";
CM_ SG_ 2556428356 P4_BalSwCell127 "电池包4的电芯127均衡状态";
CM_ SG_ 2556428356 P4_BalSwCell128 "电池包4的电芯128均衡状态";
CM_ SG_ 2556493892 P4_CellVoltage129 "电池包4的单体电压129";
CM_ SG_ 2556493892 P4_CellVoltage130 "电池包4的单体电压130";
CM_ SG_ 2556493892 P4_CellVoltage131 "电池包4的单体电压131";
CM_ SG_ 2556493892 P4_CellVoltage132 "电池包4的单体电压132";
CM_ SG_ 2556493892 P4_BalSwCell129 "电池包4的电芯129均衡状态";
CM_ SG_ 2556493892 P4_BalSwCell130 "电池包4的电芯130均衡状态";
CM_ SG_ 2556493892 P4_BalSwCell131 "电池包4的电芯131均衡状态";
CM_ SG_ 2556493892 P4_BalSwCell132 "电池包4的电芯132均衡状态";
CM_ SG_ 2556559428 P4_CellVoltage133 "电池包4的单体电压133";
CM_ SG_ 2556559428 P4_CellVoltage134 "电池包4的单体电压134";
CM_ SG_ 2556559428 P4_CellVoltage135 "电池包4的单体电压135";
CM_ SG_ 2556559428 P4_CellVoltage136 "电池包4的单体电压136";
CM_ SG_ 2556559428 P4_BalSwCell133 "电池包4的电芯133均衡状态";
CM_ SG_ 2556559428 P4_BalSwCell134 "电池包4的电芯134均衡状态";
CM_ SG_ 2556559428 P4_BalSwCell135 "电池包4的电芯135均衡状态";
CM_ SG_ 2556559428 P4_BalSwCell136 "电池包4的电芯136均衡状态";
CM_ SG_ 2556624964 P4_CellVoltage137 "电池包4的单体电压137";
CM_ SG_ 2556624964 P4_CellVoltage138 "电池包4的单体电压138";
CM_ SG_ 2556624964 P4_CellVoltage139 "电池包4的单体电压139";
CM_ SG_ 2556624964 P4_CellVoltage140 "电池包4的单体电压140";
CM_ SG_ 2556624964 P4_BalSwCell137 "电池包4的电芯137均衡状态";
CM_ SG_ 2556624964 P4_BalSwCell138 "电池包4的电芯138均衡状态";
CM_ SG_ 2556624964 P4_BalSwCell139 "电池包4的电芯139均衡状态";
CM_ SG_ 2556624964 P4_BalSwCell140 "电池包4的电芯140均衡状态";
CM_ SG_ 2556690500 P4_CellVoltage141 "电池包4的单体电压141";
CM_ SG_ 2556690500 P4_CellVoltage142 "电池包4的单体电压142";
CM_ SG_ 2556690500 P4_CellVoltage143 "电池包4的单体电压143";
CM_ SG_ 2556690500 P4_CellVoltage144 "电池包4的单体电压144";
CM_ SG_ 2556690500 P4_BalSwCell141 "电池包4的电芯141均衡状态";
CM_ SG_ 2556690500 P4_BalSwCell142 "电池包4的电芯142均衡状态";
CM_ SG_ 2556690500 P4_BalSwCell143 "电池包4的电芯143均衡状态";
CM_ SG_ 2556690500 P4_BalSwCell144 "电池包4的电芯144均衡状态";
CM_ SG_ 2556756036 P4_CellVoltage145 "电池包4的单体电压145";
CM_ SG_ 2556756036 P4_CellVoltage146 "电池包4的单体电压146";
CM_ SG_ 2556756036 P4_CellVoltage147 "电池包4的单体电压147";
CM_ SG_ 2556756036 P4_CellVoltage148 "电池包4的单体电压148";
CM_ SG_ 2556756036 P4_BalSwCell145 "电池包4的电芯145均衡状态";
CM_ SG_ 2556756036 P4_BalSwCell146 "电池包4的电芯146均衡状态";
CM_ SG_ 2556756036 P4_BalSwCell147 "电池包4的电芯147均衡状态";
CM_ SG_ 2556756036 P4_BalSwCell148 "电池包4的电芯148均衡状态";
CM_ SG_ 2556821572 P4_CellVoltage149 "电池包4的单体电压149";
CM_ SG_ 2556821572 P4_CellVoltage150 "电池包4的单体电压150";
CM_ SG_ 2556821572 P4_CellVoltage151 "电池包4的单体电压151";
CM_ SG_ 2556821572 P4_CellVoltage152 "电池包4的单体电压152";
CM_ SG_ 2556821572 P4_BalSwCell149 "电池包4的电芯149均衡状态";
CM_ SG_ 2556821572 P4_BalSwCell150 "电池包4的电芯150均衡状态";
CM_ SG_ 2556821572 P4_BalSwCell151 "电池包4的电芯151均衡状态";
CM_ SG_ 2556821572 P4_BalSwCell152 "电池包4的电芯152均衡状态";
CM_ SG_ 2556887108 P4_CellVoltage153 "电池包4的单体电压153";
CM_ SG_ 2556887108 P4_CellVoltage154 "电池包4的单体电压154";
CM_ SG_ 2556887108 P4_CellVoltage155 "电池包4的单体电压155";
CM_ SG_ 2556887108 P4_CellVoltage156 "电池包4的单体电压156";
CM_ SG_ 2556887108 P4_BalSwCell153 "电池包4的电芯153均衡状态";
CM_ SG_ 2556887108 P4_BalSwCell154 "电池包4的电芯154均衡状态";
CM_ SG_ 2556887108 P4_BalSwCell155 "电池包4的电芯155均衡状态";
CM_ SG_ 2556887108 P4_BalSwCell156 "电池包4的电芯156均衡状态";
CM_ SG_ 2556952644 P4_CellVoltage157 "电池包4的单体电压157";
CM_ SG_ 2556952644 P4_CellVoltage158 "电池包4的单体电压158";
CM_ SG_ 2556952644 P4_CellVoltage159 "电池包4的单体电压159";
CM_ SG_ 2556952644 P4_CellVoltage160 "电池包4的单体电压160";
CM_ SG_ 2556952644 P4_BalSwCell157 "电池包4的电芯157均衡状态";
CM_ SG_ 2556952644 P4_BalSwCell158 "电池包4的电芯158均衡状态";
CM_ SG_ 2556952644 P4_BalSwCell159 "电池包4的电芯159均衡状态";
CM_ SG_ 2556952644 P4_BalSwCell160 "电池包4的电芯160均衡状态";
CM_ SG_ 2557018180 P4_CellVoltage161 "电池包4的单体电压161";
CM_ SG_ 2557018180 P4_CellVoltage162 "电池包4的单体电压162";
CM_ SG_ 2557018180 P4_CellVoltage163 "电池包4的单体电压163";
CM_ SG_ 2557018180 P4_CellVoltage164 "电池包4的单体电压164";
CM_ SG_ 2557018180 P4_BalSwCell161 "电池包4的电芯161均衡状态";
CM_ SG_ 2557018180 P4_BalSwCell162 "电池包4的电芯162均衡状态";
CM_ SG_ 2557018180 P4_BalSwCell163 "电池包4的电芯163均衡状态";
CM_ SG_ 2557018180 P4_BalSwCell164 "电池包4的电芯164均衡状态";
CM_ SG_ 2557083716 P4_CellVoltage165 "电池包4的单体电压165";
CM_ SG_ 2557083716 P4_CellVoltage166 "电池包4的单体电压166";
CM_ SG_ 2557083716 P4_CellVoltage167 "电池包4的单体电压167";
CM_ SG_ 2557083716 P4_CellVoltage168 "电池包4的单体电压168";
CM_ SG_ 2557083716 P4_BalSwCell165 "电池包4的电芯165均衡状态";
CM_ SG_ 2557083716 P4_BalSwCell166 "电池包4的电芯166均衡状态";
CM_ SG_ 2557083716 P4_BalSwCell167 "电池包4的电芯167均衡状态";
CM_ SG_ 2557083716 P4_BalSwCell168 "电池包4的电芯168均衡状态";
CM_ SG_ 2557149252 P4_CellVoltage169 "电池包4的单体电压169";
CM_ SG_ 2557149252 P4_CellVoltage170 "电池包4的单体电压170";
CM_ SG_ 2557149252 P4_CellVoltage171 "电池包4的单体电压171";
CM_ SG_ 2557149252 P4_CellVoltage172 "电池包4的单体电压172";
CM_ SG_ 2557149252 P4_BalSwCell169 "电池包4的电芯169均衡状态";
CM_ SG_ 2557149252 P4_BalSwCell170 "电池包4的电芯170均衡状态";
CM_ SG_ 2557149252 P4_BalSwCell171 "电池包4的电芯171均衡状态";
CM_ SG_ 2557149252 P4_BalSwCell172 "电池包4的电芯172均衡状态";
CM_ SG_ 2557214788 P4_CellVoltage173 "电池包4的单体电压173";
CM_ SG_ 2557214788 P4_CellVoltage174 "电池包4的单体电压174";
CM_ SG_ 2557214788 P4_CellVoltage175 "电池包4的单体电压175";
CM_ SG_ 2557214788 P4_CellVoltage176 "电池包4的单体电压176";
CM_ SG_ 2557214788 P4_BalSwCell173 "电池包4的电芯173均衡状态";
CM_ SG_ 2557214788 P4_BalSwCell174 "电池包4的电芯174均衡状态";
CM_ SG_ 2557214788 P4_BalSwCell175 "电池包4的电芯175均衡状态";
CM_ SG_ 2557214788 P4_BalSwCell176 "电池包4的电芯176均衡状态";
CM_ SG_ 2557280324 P4_CellVoltage177 "电池包4的单体电压177";
CM_ SG_ 2557280324 P4_CellVoltage178 "电池包4的单体电压178";
CM_ SG_ 2557280324 P4_CellVoltage179 "电池包4的单体电压179";
CM_ SG_ 2557280324 P4_CellVoltage180 "电池包4的单体电压180";
CM_ SG_ 2557280324 P4_BalSwCell177 "电池包4的电芯177均衡状态";
CM_ SG_ 2557280324 P4_BalSwCell178 "电池包4的电芯178均衡状态";
CM_ SG_ 2557280324 P4_BalSwCell179 "电池包4的电芯179均衡状态";
CM_ SG_ 2557280324 P4_BalSwCell180 "电池包4的电芯180均衡状态";
CM_ SG_ 2557345860 P4_CellVoltage181 "电池包4的单体电压181";
CM_ SG_ 2557345860 P4_CellVoltage182 "电池包4的单体电压182";
CM_ SG_ 2557345860 P4_CellVoltage183 "电池包4的单体电压183";
CM_ SG_ 2557345860 P4_CellVoltage184 "电池包4的单体电压184";
CM_ SG_ 2557345860 P4_BalSwCell181 "电池包4的电芯181均衡状态";
CM_ SG_ 2557345860 P4_BalSwCell182 "电池包4的电芯182均衡状态";
CM_ SG_ 2557345860 P4_BalSwCell183 "电池包4的电芯183均衡状态";
CM_ SG_ 2557345860 P4_BalSwCell184 "电池包4的电芯184均衡状态";
CM_ SG_ 2557411396 P4_CellVoltage185 "电池包4的单体电压185";
CM_ SG_ 2557411396 P4_CellVoltage186 "电池包4的单体电压186";
CM_ SG_ 2557411396 P4_CellVoltage187 "电池包4的单体电压187";
CM_ SG_ 2557411396 P4_CellVoltage188 "电池包4的单体电压188";
CM_ SG_ 2557411396 P4_BalSwCell185 "电池包4的电芯185均衡状态";
CM_ SG_ 2557411396 P4_BalSwCell186 "电池包4的电芯186均衡状态";
CM_ SG_ 2557411396 P4_BalSwCell187 "电池包4的电芯187均衡状态";
CM_ SG_ 2557411396 P4_BalSwCell188 "电池包4的电芯188均衡状态";
CM_ SG_ 2557476932 P4_CellVoltage189 "电池包4的单体电压189";
CM_ SG_ 2557476932 P4_CellVoltage190 "电池包4的单体电压190";
CM_ SG_ 2557476932 P4_CellVoltage191 "电池包4的单体电压191";
CM_ SG_ 2557476932 P4_CellVoltage192 "电池包4的单体电压192";
CM_ SG_ 2557476932 P4_BalSwCell189 "电池包4的电芯189均衡状态";
CM_ SG_ 2557476932 P4_BalSwCell190 "电池包4的电芯190均衡状态";
CM_ SG_ 2557476932 P4_BalSwCell191 "电池包4的电芯191均衡状态";
CM_ SG_ 2557476932 P4_BalSwCell192 "电池包4的电芯192均衡状态";
CM_ SG_ 2558525508 P4_CellTemp1 "电池包4的单体温度1";
CM_ SG_ 2558525508 P4_CellTemp2 "电池包4的单体温度2";
CM_ SG_ 2558525508 P4_CellTemp3 "电池包4的单体温度3";
CM_ SG_ 2558525508 P4_CellTemp4 "电池包4的单体温度4";
CM_ SG_ 2558525508 P4_CellTemp5 "电池包4的单体温度5";
CM_ SG_ 2558591044 P4_CellTemp6 "电池包4的单体温度6";
CM_ SG_ 2558591044 P4_CellTemp7 "电池包4的单体温度7";
CM_ SG_ 2558591044 P4_CellTemp8 "电池包4的单体温度8";
CM_ SG_ 2558591044 P4_CellTemp9 "电池包4的单体温度9";
CM_ SG_ 2558591044 P4_CellTemp10 "电池包4的单体温度10";
CM_ SG_ 2558656580 P4_CellTemp11 "电池包4的单体温度11";
CM_ SG_ 2558656580 P4_CellTemp12 "电池包4的单体温度12";
CM_ SG_ 2558656580 P4_CellTemp13 "电池包4的单体温度13";
CM_ SG_ 2558656580 P4_CellTemp14 "电池包4的单体温度14";
CM_ SG_ 2558656580 P4_CellTemp15 "电池包4的单体温度15";
CM_ SG_ 2558722116 P4_CellTemp16 "电池包4的单体温度16";
CM_ SG_ 2558722116 P4_CellTemp17 "电池包4的单体温度17";
CM_ SG_ 2558722116 P4_CellTemp18 "电池包4的单体温度18";
CM_ SG_ 2558722116 P4_CellTemp19 "电池包4的单体温度19";
CM_ SG_ 2558722116 P4_CellTemp20 "电池包4的单体温度20";
CM_ SG_ 2558787652 P4_CellTemp21 "电池包4的单体温度21";
CM_ SG_ 2558787652 P4_CellTemp22 "电池包4的单体温度22";
CM_ SG_ 2558787652 P4_CellTemp23 "电池包4的单体温度23";
CM_ SG_ 2558787652 P4_CellTemp24 "电池包4的单体温度24";
CM_ SG_ 2558787652 P4_CellTemp25 "电池包4的单体温度25";
CM_ SG_ 2558853188 P4_CellTemp26 "电池包4的单体温度26";
CM_ SG_ 2558853188 P4_CellTemp27 "电池包4的单体温度27";
CM_ SG_ 2558853188 P4_CellTemp28 "电池包4的单体温度28";
CM_ SG_ 2558853188 P4_CellTemp29 "电池包4的单体温度29";
CM_ SG_ 2558853188 P4_CellTemp30 "电池包4的单体温度30";
CM_ SG_ 2558918724 P4_CellTemp31 "电池包4的单体温度31";
CM_ SG_ 2558918724 P4_CellTemp32 "电池包4的单体温度32";
CM_ SG_ 2558918724 P4_CellTemp33 "电池包4的单体温度33";
CM_ SG_ 2558918724 P4_CellTemp34 "电池包4的单体温度34";
CM_ SG_ 2558918724 P4_CellTemp35 "电池包4的单体温度35";
CM_ SG_ 2558984260 P4_CellTemp36 "电池包4的单体温度36";
CM_ SG_ 2558984260 P4_CellTemp37 "电池包4的单体温度37";
CM_ SG_ 2558984260 P4_CellTemp38 "电池包4的单体温度38";
CM_ SG_ 2558984260 P4_CellTemp39 "电池包4的单体温度39";
CM_ SG_ 2558984260 P4_CellTemp40 "电池包4的单体温度40";
CM_ SG_ 2559049796 P4_CellTemp41 "电池包4的单体温度41";
CM_ SG_ 2559049796 P4_CellTemp42 "电池包4的单体温度42";
CM_ SG_ 2559049796 P4_CellTemp43 "电池包4的单体温度43";
CM_ SG_ 2559049796 P4_CellTemp44 "电池包4的单体温度44";
CM_ SG_ 2559049796 P4_CellTemp45 "电池包4的单体温度45";
CM_ SG_ 2559115332 P4_CellTemp46 "电池包4的单体温度46";
CM_ SG_ 2559115332 P4_CellTemp47 "电池包4的单体温度47";
CM_ SG_ 2559115332 P4_CellTemp48 "电池包4的单体温度48";
CM_ SG_ 2559115332 P4_CellTemp49 "电池包4的单体温度49";
CM_ SG_ 2559115332 P4_CellTemp50 "电池包4的单体温度50";
CM_ SG_ 2559180868 P4_CellTemp51 "电池包4的单体温度51";
CM_ SG_ 2559180868 P4_CellTemp52 "电池包4的单体温度52";
CM_ SG_ 2559180868 P4_CellTemp53 "电池包4的单体温度53";
CM_ SG_ 2559180868 P4_CellTemp54 "电池包4的单体温度54";
CM_ SG_ 2559180868 P4_CellTemp55 "电池包4的单体温度55";
CM_ SG_ 2559246404 P4_CellTemp56 "电池包4的单体温度56";
CM_ SG_ 2559246404 P4_CellTemp57 "电池包4的单体温度57";
CM_ SG_ 2559246404 P4_CellTemp58 "电池包4的单体温度58";
CM_ SG_ 2559246404 P4_CellTemp59 "电池包4的单体温度59";
CM_ SG_ 2559246404 P4_CellTemp60 "电池包4的单体温度60";
CM_ SG_ 2559311940 P4_CellTemp61 "电池包4的单体温度61";
CM_ SG_ 2559311940 P4_CellTemp62 "电池包4的单体温度62";
CM_ SG_ 2559311940 P4_CellTemp63 "电池包4的单体温度63";
CM_ SG_ 2559311940 P4_CellTemp64 "电池包4的单体温度64";
CM_ SG_ 2559311940 P4_CellTemp65 "电池包4的单体温度65";
CM_ SG_ 2559377476 P4_CellTemp66 "电池包4的单体温度66";
CM_ SG_ 2559377476 P4_CellTemp67 "电池包4的单体温度67";
CM_ SG_ 2559377476 P4_CellTemp68 "电池包4的单体温度68";
CM_ SG_ 2559377476 P4_CellTemp69 "电池包4的单体温度69";
CM_ SG_ 2559377476 P4_CellTemp70 "电池包4的单体温度70";
CM_ SG_ 2559443012 P4_CellTemp71 "电池包4的单体温度71";
CM_ SG_ 2559443012 P4_CellTemp72 "电池包4的单体温度72";
CM_ SG_ 2559443012 P4_CellTemp73 "电池包4的单体温度73";
CM_ SG_ 2559443012 P4_CellTemp74 "电池包4的单体温度74";
CM_ SG_ 2559443012 P4_CellTemp75 "电池包4的单体温度75";
CM_ SG_ 2559508548 P4_CellTemp76 "电池包4的单体温度76";
CM_ SG_ 2559508548 P4_CellTemp77 "电池包4的单体温度77";
CM_ SG_ 2559508548 P4_CellTemp78 "电池包4的单体温度78";
CM_ SG_ 2559508548 P4_CellTemp79 "电池包4的单体温度79";
CM_ SG_ 2559508548 P4_CellTemp80 "电池包4的单体温度80";
CM_ SG_ 2559574084 P4_CellTemp81 "电池包4的单体温度81";
CM_ SG_ 2559574084 P4_CellTemp82 "电池包4的单体温度82";
CM_ SG_ 2559574084 P4_CellTemp83 "电池包4的单体温度83";
CM_ SG_ 2559574084 P4_CellTemp84 "电池包4的单体温度84";
CM_ SG_ 2559574084 P4_CellTemp85 "电池包4的单体温度85";
CM_ SG_ 2559639620 P4_CellTemp86 "电池包4的单体温度86";
CM_ SG_ 2559639620 P4_CellTemp87 "电池包4的单体温度87";
CM_ SG_ 2559639620 P4_CellTemp88 "电池包4的单体温度88";
CM_ SG_ 2559639620 P4_CellTemp89 "电池包4的单体温度89";
CM_ SG_ 2559639620 P4_CellTemp90 "电池包4的单体温度90";
CM_ SG_ 2559705156 P4_CellTemp91 "电池包4的单体温度91";
CM_ SG_ 2559705156 P4_CellTemp92 "电池包4的单体温度92";
CM_ SG_ 2559705156 P4_CellTemp93 "电池包4的单体温度93";
CM_ SG_ 2559705156 P4_CellTemp94 "电池包4的单体温度94";
CM_ SG_ 2559705156 P4_CellTemp95 "电池包4的单体温度95";
CM_ SG_ 2559770692 P4_CellTemp96 "电池包4的单体温度96";
CM_ SG_ 2559770692 P4_CellTemp97 "电池包4的单体温度97";
CM_ SG_ 2559770692 P4_CellTemp98 "电池包4的单体温度98";
CM_ SG_ 2559770692 P4_CellTemp99 "电池包4的单体温度99";
CM_ SG_ 2559770692 P4_CellTemp100 "电池包4的单体温度100";
CM_ SG_ 2559836228 P4_CellTemp101 "电池包4的单体温度101";
CM_ SG_ 2559836228 P4_CellTemp102 "电池包4的单体温度102";
CM_ SG_ 2559836228 P4_CellTemp103 "电池包4的单体温度103";
CM_ SG_ 2559836228 P4_CellTemp104 "电池包4的单体温度104";
CM_ SG_ 2559836228 P4_CellTemp105 "电池包4的单体温度105";
CM_ SG_ 2559901764 P4_CellTemp106 "电池包4的单体温度106";
CM_ SG_ 2559901764 P4_CellTemp107 "电池包4的单体温度107";
CM_ SG_ 2559901764 P4_CellTemp108 "电池包4的单体温度108";
CM_ SG_ 2559901764 P4_CellTemp109 "电池包4的单体温度109";
CM_ SG_ 2559901764 P4_CellTemp110 "电池包4的单体温度110";
CM_ SG_ 2559967300 P4_CellTemp111 "电池包4的单体温度111";
CM_ SG_ 2559967300 P4_CellTemp112 "电池包4的单体温度112";
CM_ SG_ 2559967300 P4_CellTemp113 "电池包4的单体温度113";
CM_ SG_ 2559967300 P4_CellTemp114 "电池包4的单体温度114";
CM_ SG_ 2559967300 P4_CellTemp115 "电池包4的单体温度115";
CM_ SG_ 2560032836 P4_CellTemp116 "电池包4的单体温度116";
CM_ SG_ 2560032836 P4_CellTemp117 "电池包4的单体温度117";
CM_ SG_ 2560032836 P4_CellTemp118 "电池包4的单体温度118";
CM_ SG_ 2560032836 P4_CellTemp119 "电池包4的单体温度119";
CM_ SG_ 2560032836 P4_CellTemp120 "电池包4的单体温度120";
CM_ SG_ 2560098372 P4_CellTemp121 "电池包4的单体温度121";
CM_ SG_ 2560098372 P4_CellTemp122 "电池包4的单体温度122";
CM_ SG_ 2560098372 P4_CellTemp123 "电池包4的单体温度123";
CM_ SG_ 2560098372 P4_CellTemp124 "电池包4的单体温度124";
CM_ SG_ 2560098372 P4_CellTemp125 "电池包4的单体温度125";
CM_ SG_ 2560163908 P4_CellTemp126 "电池包4的单体温度126";
CM_ SG_ 2560163908 P4_CellTemp127 "电池包4的单体温度127";
CM_ SG_ 2560163908 P4_CellTemp128 "电池包4的单体温度128";
CM_ SG_ 2560163908 P4_CellTemp129 "电池包4的单体温度129";
CM_ SG_ 2560163908 P4_CellTemp130 "电池包4的单体温度130";
CM_ SG_ 2560229444 P4_CellTemp131 "电池包4的单体温度131";
CM_ SG_ 2560229444 P4_CellTemp132 "电池包4的单体温度132";
CM_ SG_ 2560229444 P4_CellTemp133 "电池包4的单体温度133";
CM_ SG_ 2560229444 P4_CellTemp134 "电池包4的单体温度134";
CM_ SG_ 2560229444 P4_CellTemp135 "电池包4的单体温度135";
CM_ SG_ 2560294980 P4_CellTemp136 "电池包4的单体温度136";
CM_ SG_ 2560294980 P4_CellTemp137 "电池包4的单体温度137";
CM_ SG_ 2560294980 P4_CellTemp138 "电池包4的单体温度138";
CM_ SG_ 2560294980 P4_CellTemp139 "电池包4的单体温度139";
CM_ SG_ 2560294980 P4_CellTemp140 "电池包4的单体温度140";
CM_ SG_ 2560360516 P4_CellTemp141 "电池包4的单体温度141";
CM_ SG_ 2560360516 P4_CellTemp142 "电池包4的单体温度142";
CM_ SG_ 2560360516 P4_CellTemp143 "电池包4的单体温度143";
CM_ SG_ 2560360516 P4_CellTemp144 "电池包4的单体温度144";
CM_ SG_ 2560360516 P4_CellTemp145 "电池包4的单体温度145";
CM_ SG_ 2560426052 P4_CellTemp146 "电池包4的单体温度146";
CM_ SG_ 2560426052 P4_CellTemp147 "电池包4的单体温度147";
CM_ SG_ 2560426052 P4_CellTemp148 "电池包4的单体温度148";
CM_ SG_ 2560426052 P4_CellTemp149 "电池包4的单体温度149";
CM_ SG_ 2560426052 P4_CellTemp150 "电池包4的单体温度150";
CM_ SG_ 2560491588 P4_CellTemp151 "电池包4的单体温度151";
CM_ SG_ 2560491588 P4_CellTemp152 "电池包4的单体温度152";
CM_ SG_ 2560491588 P4_CellTemp153 "电池包4的单体温度153";
CM_ SG_ 2560491588 P4_CellTemp154 "电池包4的单体温度154";
CM_ SG_ 2560491588 P4_CellTemp155 "电池包4的单体温度155";
CM_ SG_ 2560557124 P4_CellTemp156 "电池包4的单体温度156";
CM_ SG_ 2560557124 P4_CellTemp157 "电池包4的单体温度157";
CM_ SG_ 2560557124 P4_CellTemp158 "电池包4的单体温度158";
CM_ SG_ 2560557124 P4_CellTemp159 "电池包4的单体温度159";
CM_ SG_ 2560557124 P4_CellTemp160 "电池包4的单体温度160";
CM_ SG_ 2560622660 P4_CellTemp161 "电池包4的单体温度161";
CM_ SG_ 2560622660 P4_CellTemp162 "电池包4的单体温度162";
CM_ SG_ 2560622660 P4_CellTemp163 "电池包4的单体温度163";
CM_ SG_ 2560622660 P4_CellTemp164 "电池包4的单体温度164";
CM_ SG_ 2560622660 P4_CellTemp165 "电池包4的单体温度165";
CM_ SG_ 2560688196 P4_CellTemp166 "电池包4的单体温度166";
CM_ SG_ 2560688196 P4_CellTemp167 "电池包4的单体温度167";
CM_ SG_ 2560688196 P4_CellTemp168 "电池包4的单体温度168";
CM_ SG_ 2560688196 P4_CellTemp169 "电池包4的单体温度169";
CM_ SG_ 2560688196 P4_CellTemp170 "电池包4的单体温度170";
CM_ SG_ 2560753732 P4_CellTemp171 "电池包4的单体温度171";
CM_ SG_ 2560753732 P4_CellTemp172 "电池包4的单体温度172";
CM_ SG_ 2560753732 P4_CellTemp173 "电池包4的单体温度173";
CM_ SG_ 2560753732 P4_CellTemp174 "电池包4的单体温度174";
CM_ SG_ 2560753732 P4_CellTemp175 "电池包4的单体温度175";
CM_ SG_ 2560819268 P4_CellTemp176 "电池包4的单体温度176";
CM_ SG_ 2560819268 P4_CellTemp177 "电池包4的单体温度177";
CM_ SG_ 2560819268 P4_CellTemp178 "电池包4的单体温度178";
CM_ SG_ 2560819268 P4_CellTemp179 "电池包4的单体温度179";
CM_ SG_ 2560819268 P4_CellTemp180 "电池包4的单体温度180";
CM_ SG_ 2560884804 P4_CellTemp181 "电池包4的单体温度181";
CM_ SG_ 2560884804 P4_CellTemp182 "电池包4的单体温度182";
CM_ SG_ 2560884804 P4_CellTemp183 "电池包4的单体温度183";
CM_ SG_ 2560884804 P4_CellTemp184 "电池包4的单体温度184";
CM_ SG_ 2560884804 P4_CellTemp185 "电池包4的单体温度185";
CM_ SG_ 2560950340 P4_CellTemp186 "电池包4的单体温度186";
CM_ SG_ 2560950340 P4_CellTemp187 "电池包4的单体温度187";
CM_ SG_ 2560950340 P4_CellTemp188 "电池包4的单体温度188";
CM_ SG_ 2560950340 P4_CellTemp189 "电池包4的单体温度189";
CM_ SG_ 2560950340 P4_CellTemp190 "电池包4的单体温度190";
CM_ SG_ 2561015876 P4_CellTemp191 "电池包4的单体温度191";
CM_ SG_ 2561015876 P4_CellTemp192 "电池包4的单体温度192";
CM_ SG_ 2561015876 P4_DatLen16DbgInfo1 "长度为16的调试信息1";
CM_ SG_ 2561015876 P4_DatLen16DbgInfo2 "长度为16的调试信息2";
CM_ SG_ 2561015876 P4_DatLen16DbgInfo3 "长度为16的调试信息3";
CM_ SG_ 2561015876 P4_DatLen16DbgInfo4 "长度为16的调试信息4";
CM_ SG_ 2550399061 P5_BMSPwrSuplVlt1 "电池包5的BMS供电电源电压1";
CM_ SG_ 2550399061 P5_BMSPwrSuplVlt2 "电池包5的BMS供电电源电压2";
CM_ SG_ 2550399061 P5_ChrgStationAuxPwrSuplVlt "电池包5的快充桩A+电压";
CM_ SG_ 2550399061 P5_BMSKL15ON "电池包5的BMS唤醒信号";
CM_ SG_ 2550399061 P5_DCStepState "电池包5的充电状态机";
CM_ SG_ 2550399061 P5_ExtLvWakeup_28VOnly "电池包5的外部唤醒";
CM_ SG_ 2550464597 P5_PackVltUprLmt "电池包5的电压使用上限";
CM_ SG_ 2550464597 P5_PackVltLoLmt "电池包5的电压使用下限";
CM_ SG_ 2550464597 P5_PackMaxDschrgCrnt "电池包5的最大允许放电电流";
CM_ SG_ 2550464597 P5_PackMaxChrgCrnt "电池包5的最大允许充电电流";
BA_DEF_ BO_  "GenMsgSendType" ENUM  "Cyclic","IfActive","Event";
BA_DEF_ BO_  "GenMsgCycleTime" INT 0 5000;
BA_DEF_ BO_  "VFrameFormat" ENUM  "StandardCAN","ExtendedCAN","reserved","reserved","reserved","reserved","reserved","reserved","reserved","reserved","reserved","reserved","reserved","reserved","StandardCAN_FD","ExtendedCAN_FD";
BA_DEF_ SG_  "GenSigSendType" ENUM  "Cyclic","OnWrite","OnChange","NoSigSendType";
BA_DEF_DEF_  "GenMsgSendType" "Cyclic";
BA_DEF_DEF_  "GenMsgCycleTime" 0;
BA_DEF_DEF_  "GenSigSendType" "Cyclic";
BA_DEF_DEF_  "VFrameFormat" "ExtendedCAN";
BA_ "GenMsgCycleTime" BO_ 2550464563 500;
BA_ "GenMsgCycleTime" BO_ 2550530099 500;
BA_ "GenMsgCycleTime" BO_ 2550595635 500;
BA_ "GenMsgCycleTime" BO_ 2550661171 500;
BA_ "GenMsgCycleTime" BO_ 2550726707 500;
BA_ "GenMsgCycleTime" BO_ 2550792243 500;
BA_ "GenMsgCycleTime" BO_ 2550857779 500;
BA_ "GenMsgCycleTime" BO_ 2550923315 500;
BA_ "GenMsgCycleTime" BO_ 2550988851 1000;
BA_ "GenMsgCycleTime" BO_ 2552299571 1000;
BA_ "GenMsgCycleTime" BO_ 2554396723 1000;
BA_ "GenMsgCycleTime" BO_ 2554462259 1000;
BA_ "GenMsgCycleTime" BO_ 2554527795 1000;
BA_ "GenMsgCycleTime" BO_ 2554593331 1000;
BA_ "GenMsgCycleTime" BO_ 2554658867 1000;
BA_ "GenMsgCycleTime" BO_ 2554724403 1000;
BA_ "GenMsgCycleTime" BO_ 2554789939 1000;
BA_ "GenMsgCycleTime" BO_ 2554855475 1000;
BA_ "GenMsgCycleTime" BO_ 2554921011 1000;
BA_ "GenMsgCycleTime" BO_ 2554986547 1000;
BA_ "GenMsgCycleTime" BO_ 2555052083 1000;
BA_ "GenMsgCycleTime" BO_ 2555117619 1000;
BA_ "GenMsgCycleTime" BO_ 2555183155 1000;
BA_ "GenMsgCycleTime" BO_ 2555248691 1000;
BA_ "GenMsgCycleTime" BO_ 2555314227 1000;
BA_ "GenMsgCycleTime" BO_ 2555379763 1000;
BA_ "GenMsgCycleTime" BO_ 2555445299 1000;
BA_ "GenMsgCycleTime" BO_ 2555510835 1000;
BA_ "GenMsgCycleTime" BO_ 2555576371 1000;
BA_ "GenMsgCycleTime" BO_ 2555641907 1000;
BA_ "GenMsgCycleTime" BO_ 2555707443 1000;
BA_ "GenMsgCycleTime" BO_ 2555772979 1000;
BA_ "GenMsgCycleTime" BO_ 2555838515 1000;
BA_ "GenMsgCycleTime" BO_ 2555904051 1000;
BA_ "GenMsgCycleTime" BO_ 2555969587 1000;
BA_ "GenMsgCycleTime" BO_ 2556035123 1000;
BA_ "GenMsgCycleTime" BO_ 2556100659 1000;
BA_ "GenMsgCycleTime" BO_ 2556166195 1000;
BA_ "GenMsgCycleTime" BO_ 2556231731 1000;
BA_ "GenMsgCycleTime" BO_ 2556297267 1000;
BA_ "GenMsgCycleTime" BO_ 2556362803 1000;
BA_ "GenMsgCycleTime" BO_ 2556428339 1000;
BA_ "GenMsgCycleTime" BO_ 2556493875 1000;
BA_ "GenMsgCycleTime" BO_ 2556559411 1000;
BA_ "GenMsgCycleTime" BO_ 2556624947 1000;
BA_ "GenMsgCycleTime" BO_ 2556690483 1000;
BA_ "GenMsgCycleTime" BO_ 2556756019 1000;
BA_ "GenMsgCycleTime" BO_ 2556821555 1000;
BA_ "GenMsgCycleTime" BO_ 2556887091 1000;
BA_ "GenMsgCycleTime" BO_ 2556952627 1000;
BA_ "GenMsgCycleTime" BO_ 2557018163 1000;
BA_ "GenMsgCycleTime" BO_ 2557083699 1000;
BA_ "GenMsgCycleTime" BO_ 2557149235 1000;
BA_ "GenMsgCycleTime" BO_ 2557214771 1000;
BA_ "GenMsgCycleTime" BO_ 2557280307 1000;
BA_ "GenMsgCycleTime" BO_ 2557345843 1000;
BA_ "GenMsgCycleTime" BO_ 2557411379 1000;
BA_ "GenMsgCycleTime" BO_ 2557476915 1000;
BA_ "GenMsgCycleTime" BO_ 2558525491 1000;
BA_ "GenMsgCycleTime" BO_ 2558591027 1000;
BA_ "GenMsgCycleTime" BO_ 2558656563 1000;
BA_ "GenMsgCycleTime" BO_ 2558722099 1000;
BA_ "GenMsgCycleTime" BO_ 2558787635 1000;
BA_ "GenMsgCycleTime" BO_ 2558853171 1000;
BA_ "GenMsgCycleTime" BO_ 2558918707 1000;
BA_ "GenMsgCycleTime" BO_ 2558984243 1000;
BA_ "GenMsgCycleTime" BO_ 2559049779 1000;
BA_ "GenMsgCycleTime" BO_ 2559115315 1000;
BA_ "GenMsgCycleTime" BO_ 2559180851 1000;
BA_ "GenMsgCycleTime" BO_ 2559246387 1000;
BA_ "GenMsgCycleTime" BO_ 2559311923 1000;
BA_ "GenMsgCycleTime" BO_ 2559377459 1000;
BA_ "GenMsgCycleTime" BO_ 2559442995 1000;
BA_ "GenMsgCycleTime" BO_ 2559508531 1000;
BA_ "GenMsgCycleTime" BO_ 2559574067 1000;
BA_ "GenMsgCycleTime" BO_ 2559639603 1000;
BA_ "GenMsgCycleTime" BO_ 2559705139 1000;
BA_ "GenMsgCycleTime" BO_ 2559770675 1000;
BA_ "GenMsgCycleTime" BO_ 2559836211 1000;
BA_ "GenMsgCycleTime" BO_ 2559901747 1000;
BA_ "GenMsgCycleTime" BO_ 2559967283 1000;
BA_ "GenMsgCycleTime" BO_ 2560032819 1000;
BA_ "GenMsgCycleTime" BO_ 2560098355 1000;
BA_ "GenMsgCycleTime" BO_ 2560163891 1000;
BA_ "GenMsgCycleTime" BO_ 2560229427 1000;
BA_ "GenMsgCycleTime" BO_ 2560294963 1000;
BA_ "GenMsgCycleTime" BO_ 2560360499 1000;
BA_ "GenMsgCycleTime" BO_ 2560426035 1000;
BA_ "GenMsgCycleTime" BO_ 2560491571 1000;
BA_ "GenMsgCycleTime" BO_ 2560557107 1000;
BA_ "GenMsgCycleTime" BO_ 2560622643 1000;
BA_ "GenMsgCycleTime" BO_ 2560688179 1000;
BA_ "GenMsgCycleTime" BO_ 2560753715 1000;
BA_ "GenMsgCycleTime" BO_ 2560819251 1000;
BA_ "GenMsgCycleTime" BO_ 2560884787 1000;
BA_ "GenMsgCycleTime" BO_ 2560950323 1000;
BA_ "GenMsgCycleTime" BO_ 2561015859 1000;
BA_ "GenMsgCycleTime" BO_ 2550399044 500;
BA_ "GenMsgCycleTime" BO_ 2550464580 500;
BA_ "GenMsgCycleTime" BO_ 2550530116 500;
BA_ "GenMsgCycleTime" BO_ 2550595652 500;
BA_ "GenMsgCycleTime" BO_ 2550661188 500;
BA_ "GenMsgCycleTime" BO_ 2550726724 500;
BA_ "GenMsgCycleTime" BO_ 2550792260 500;
BA_ "GenMsgCycleTime" BO_ 2550857796 500;
BA_ "GenMsgCycleTime" BO_ 2550923332 500;
BA_ "GenMsgCycleTime" BO_ 2550988868 1000;
BA_ "GenMsgCycleTime" BO_ 2552299588 1000;
BA_ "GenMsgCycleTime" BO_ 2554396740 1000;
BA_ "GenMsgCycleTime" BO_ 2554462276 1000;
BA_ "GenMsgCycleTime" BO_ 2554527812 1000;
BA_ "GenMsgCycleTime" BO_ 2554593348 1000;
BA_ "GenMsgCycleTime" BO_ 2554658884 1000;
BA_ "GenMsgCycleTime" BO_ 2554724420 1000;
BA_ "GenMsgCycleTime" BO_ 2554789956 1000;
BA_ "GenMsgCycleTime" BO_ 2554855492 1000;
BA_ "GenMsgCycleTime" BO_ 2554921028 1000;
BA_ "GenMsgCycleTime" BO_ 2554986564 1000;
BA_ "GenMsgCycleTime" BO_ 2555052100 1000;
BA_ "GenMsgCycleTime" BO_ 2555117636 1000;
BA_ "GenMsgCycleTime" BO_ 2555183172 1000;
BA_ "GenMsgCycleTime" BO_ 2555248708 1000;
BA_ "GenMsgCycleTime" BO_ 2555314244 1000;
BA_ "GenMsgCycleTime" BO_ 2555379780 1000;
BA_ "GenMsgCycleTime" BO_ 2555445316 1000;
BA_ "GenMsgCycleTime" BO_ 2555510852 1000;
BA_ "GenMsgCycleTime" BO_ 2555576388 1000;
BA_ "GenMsgCycleTime" BO_ 2555641924 1000;
BA_ "GenMsgCycleTime" BO_ 2555707460 1000;
BA_ "GenMsgCycleTime" BO_ 2555772996 1000;
BA_ "GenMsgCycleTime" BO_ 2555838532 1000;
BA_ "GenMsgCycleTime" BO_ 2555904068 1000;
BA_ "GenMsgCycleTime" BO_ 2555969604 1000;
BA_ "GenMsgCycleTime" BO_ 2556035140 1000;
BA_ "GenMsgCycleTime" BO_ 2556100676 1000;
BA_ "GenMsgCycleTime" BO_ 2556166212 1000;
BA_ "GenMsgCycleTime" BO_ 2556231748 1000;
BA_ "GenMsgCycleTime" BO_ 2556297284 1000;
BA_ "GenMsgCycleTime" BO_ 2556362820 1000;
BA_ "GenMsgCycleTime" BO_ 2556428356 1000;
BA_ "GenMsgCycleTime" BO_ 2556493892 1000;
BA_ "GenMsgCycleTime" BO_ 2556559428 1000;
BA_ "GenMsgCycleTime" BO_ 2556624964 1000;
BA_ "GenMsgCycleTime" BO_ 2556690500 1000;
BA_ "GenMsgCycleTime" BO_ 2556756036 1000;
BA_ "GenMsgCycleTime" BO_ 2556821572 1000;
BA_ "GenMsgCycleTime" BO_ 2556887108 1000;
BA_ "GenMsgCycleTime" BO_ 2556952644 1000;
BA_ "GenMsgCycleTime" BO_ 2557018180 1000;
BA_ "GenMsgCycleTime" BO_ 2557083716 1000;
BA_ "GenMsgCycleTime" BO_ 2557149252 1000;
BA_ "GenMsgCycleTime" BO_ 2557214788 1000;
BA_ "GenMsgCycleTime" BO_ 2557280324 1000;
BA_ "GenMsgCycleTime" BO_ 2557345860 1000;
BA_ "GenMsgCycleTime" BO_ 2557411396 1000;
BA_ "GenMsgCycleTime" BO_ 2557476932 1000;
BA_ "GenMsgCycleTime" BO_ 2558525508 1000;
BA_ "GenMsgCycleTime" BO_ 2558591044 1000;
BA_ "GenMsgCycleTime" BO_ 2558656580 1000;
BA_ "GenMsgCycleTime" BO_ 2558722116 1000;
BA_ "GenMsgCycleTime" BO_ 2558787652 1000;
BA_ "GenMsgCycleTime" BO_ 2558853188 1000;
BA_ "GenMsgCycleTime" BO_ 2558918724 1000;
BA_ "GenMsgCycleTime" BO_ 2558984260 1000;
BA_ "GenMsgCycleTime" BO_ 2559049796 1000;
BA_ "GenMsgCycleTime" BO_ 2559115332 1000;
BA_ "GenMsgCycleTime" BO_ 2559180868 1000;
BA_ "GenMsgCycleTime" BO_ 2559246404 1000;
BA_ "GenMsgCycleTime" BO_ 2559311940 1000;
BA_ "GenMsgCycleTime" BO_ 2559377476 1000;
BA_ "GenMsgCycleTime" BO_ 2559443012 1000;
BA_ "GenMsgCycleTime" BO_ 2559508548 1000;
BA_ "GenMsgCycleTime" BO_ 2559574084 1000;
BA_ "GenMsgCycleTime" BO_ 2559639620 1000;
BA_ "GenMsgCycleTime" BO_ 2559705156 1000;
BA_ "GenMsgCycleTime" BO_ 2559770692 1000;
BA_ "GenMsgCycleTime" BO_ 2559836228 1000;
BA_ "GenMsgCycleTime" BO_ 2559901764 1000;
BA_ "GenMsgCycleTime" BO_ 2559967300 1000;
BA_ "GenMsgCycleTime" BO_ 2560032836 1000;
BA_ "GenMsgCycleTime" BO_ 2560098372 1000;
BA_ "GenMsgCycleTime" BO_ 2560163908 1000;
BA_ "GenMsgCycleTime" BO_ 2560229444 1000;
BA_ "GenMsgCycleTime" BO_ 2560294980 1000;
BA_ "GenMsgCycleTime" BO_ 2560360516 1000;
BA_ "GenMsgCycleTime" BO_ 2560426052 1000;
BA_ "GenMsgCycleTime" BO_ 2560491588 1000;
BA_ "GenMsgCycleTime" BO_ 2560557124 1000;
BA_ "GenMsgCycleTime" BO_ 2560622660 1000;
BA_ "GenMsgCycleTime" BO_ 2560688196 1000;
BA_ "GenMsgCycleTime" BO_ 2560753732 1000;
BA_ "GenMsgCycleTime" BO_ 2560819268 1000;
BA_ "GenMsgCycleTime" BO_ 2560884804 1000;
BA_ "GenMsgCycleTime" BO_ 2560950340 1000;
BA_ "GenMsgCycleTime" BO_ 2561015876 1000;
BA_ "GenMsgCycleTime" BO_ 2550399061 500;
BA_ "GenMsgCycleTime" BO_ 2550464597 500;
VAL_ 2550530099 P3_PackDschrgPwrStat 02 "鎸佺画鏀剧數鍔熺巼" 01 "30s鏀剧數鍔熺巼" 00 "10s鏀剧數鍔熺巼" ;
VAL_ 2550530099 P3_PackChrgPwrStat 02 "鎸佺画鍏呯數鍔熺巼" 01 "30s鍏呯數鍔熺巼" 00 "10s鍏呯數鍔熺巼" ;
VAL_ 2550595635 P3_ChrgrCplrStat 01 "Connected" 00 "Disconnected" ;
VAL_ 2550595635 P3_HVBattChrgSysStatus 04 "Aborted" 03 "Complete" 02 "Active" 01 "Initialization" 00 "Default" ;
VAL_ 2550857779 P3_CellOverVoltage 03 "Level 3" 02 "Level 2" 01 "Level 1" 00 "No Fault" ;
VAL_ 2550857779 P3_CellUnderVoltage 03 "Level 3" 02 "Level 2" 01 "Level 1" 00 "No Fault" ;
VAL_ 2550857779 P3_CellVoltageDiffHi 01 "Fault" 00 "No Fault" ;
VAL_ 2550857779 P3_PackOverVoltage 03 "Level 3" 02 "Level 2" 01 "Level 1" 00 "No Fault" ;
VAL_ 2550857779 P3_PackUnderVoltage 03 "Level 3" 02 "Level 2" 01 "Level 1" 00 "No Fault" ;
VAL_ 2550857779 P3_CellOverTemp 03 "Level 3" 02 "Level 2" 01 "Level 1" 00 "No Fault" ;
VAL_ 2550857779 P3_CellTempLow 01 "Fault" 00 "No Fault" ;
VAL_ 2550857779 P3_CellTempDiffHi 01 "Fault" 00 "No Fault" ;
VAL_ 2550857779 P3_PackDschrgCrntHi 03 "Level 3" 02 "Level 2" 01 "Level 1" 00 "No Fault" ;
VAL_ 2550857779 P3_PackChrgCrntHi 03 "Level 3" 02 "Level 2" 01 "Level 1" 00 "No Fault" ;
VAL_ 2550857779 P3_PackCrnSnsr1OffsetHi 01 "Fault" 00 "No Fault" ;
VAL_ 2550857779 P3_HVIsolFlt 03 "Level 3" 02 "Level 2" 01 "Level 1" 00 "No Fault" ;
VAL_ 2550857779 P3_HVILFlt 01 "Fault" 00 "No Fault" ;
VAL_ 2550857779 P3_ThrmlRunaway 01 "Fault" 00 "No Fault" ;
VAL_ 2550857779 P3_CellVoltInvalid 01 "Fault" 00 "No Fault" ;
VAL_ 2550857779 P3_CellTempInvalid 01 "Fault" 00 "No Fault" ;
VAL_ 2550857779 P3_DaisyChainComFlt 01 "Fault" 00 "No Fault" ;
VAL_ 2550857779 P3_PackVoltRatFlt 01 "Fault" 00 "No Fault" ;
VAL_ 2550857779 P3_CrntSnsr1Invalid 01 "Fault" 00 "No Fault" ;
VAL_ 2550857779 P3_CrntSnsr1OOR 01 "Fault" 00 "No Fault" ;
VAL_ 2550857779 P3_CrntSnsr2Invalid 01 "Fault" 00 "No Fault" ;
VAL_ 2550857779 P3_CrntSnsr2OOR 01 "Fault" 00 "No Fault" ;
VAL_ 2550857779 P3_PackCrnSnsr2OffsetHi 01 "Fault" 00 "No Fault" ;
VAL_ 2550857779 P3_OutofEnergy 01 "Fault" 00 "No Fault" ;
VAL_ 2550857779 P3_IsolDetCircErr 01 "Fault" 00 "No Fault" ;
VAL_ 2550857779 P3_HVILCircShortToGND 01 "Fault" 00 "No Fault" ;
VAL_ 2550857779 P3_HVILCircShortToPwr 01 "Fault" 00 "No Fault" ;
VAL_ 2550923315 P3_MainPosCntctrStkClsd 01 "Fault" 00 "No Fault" ;
VAL_ 2550923315 P3_MainPosCntctrStkOpn 01 "Fault" 00 "No Fault" ;
VAL_ 2550923315 P3_MainNegCntctr1StkClsd 01 "Fault" 00 "No Fault" ;
VAL_ 2550923315 P3_MainNegCntctr1StkOpn 01 "Fault" 00 "No Fault" ;
VAL_ 2550923315 P3_MainNegCntctr2StkClsd 01 "Fault" 00 "No Fault" ;
VAL_ 2550923315 P3_MainNegCntctr2StkOpn 01 "Fault" 00 "No Fault" ;
VAL_ 2550923315 P3_PrechargTmOut 01 "Fault" 00 "No Fault" ;
VAL_ 2550923315 P3_PrechrgCrntHi 01 "Fault" 00 "No Fault" ;
VAL_ 2550923315 P3_ChrgCplrPosTempHi 01 "Fault" 00 "No Fault" ;
VAL_ 2550923315 P3_ChrgCplrNegTempHi 01 "Fault" 00 "No Fault" ;
VAL_ 2550923315 P3_BMSPwrSuplVlt1Hi 01 "Fault" 00 "No Fault" ;
VAL_ 2550923315 P3_BMSPwrSuplVlt1Lo 01 "Fault" 00 "No Fault" ;
VAL_ 2550923315 P3_BMSPwrSuplVlt2Hi 01 "Fault" 00 "No Fault" ;
VAL_ 2550923315 P3_BMSPwrSuplVlt2Lo 01 "Fault" 00 "No Fault" ;
VAL_ 2550923315 P3_CntctrCirPwrSuplVltLo 01 "Fault" 00 "No Fault" ;
VAL_ 2550923315 P3_CntctrCirPwrSuplVltHi 01 "Fault" 00 "No Fault" ;
VAL_ 2550923315 P3_CAN1BusOff 01 "Fault" 00 "No Fault" ;
VAL_ 2550923315 P3_CAN1BusTmOut 01 "Fault" 00 "No Fault" ;
VAL_ 2550923315 P3_CAN2BusOff 01 "Fault" 00 "No Fault" ;
VAL_ 2550923315 P3_CAN2BusTmOut 01 "Fault" 00 "No Fault" ;
VAL_ 2550923315 P3_CellBalCircTempHi 01 "Fault" 00 "No Fault" ;
VAL_ 2550923315 P3_ClntInTempHi 01 "Fault" 00 "No Fault" ;
VAL_ 2550923315 P3_ClntOutTempHi 01 "Fault" 00 "No Fault" ;
VAL_ 2550923315 P3_CellExtrmUdrVolt 01 "Fault" 00 "No Fault" ;
VAL_ 2550923315 P3_CellExtrmOvrVolt 01 "Fault" 00 "No Fault" ;
VAL_ 2550923315 P3_Branch1DischrgCrntHi  01 "Fault" 00 "No Fault" ;
VAL_ 2550923315 P3_Branch2DischrgCrntHi  01 "Fault" 00 "No Fault" ;
VAL_ 2550923315 P3_Branch1ChrgCrntHi  01 "Fault" 00 "No Fault" ;
VAL_ 2550923315 P3_Branch2ChrgCrntHi  01 "Fault" 00 "No Fault" ;
VAL_ 2550923315 P3_InitFailed 01 "Fault" 00 "No Fault" ;
VAL_ 2554396723 P3_BalSwCell1 01 "Active" 00 "Inactive" ;
VAL_ 2554396723 P3_BalSwCell2 01 "Active" 00 "Inactive" ;
VAL_ 2554396723 P3_BalSwCell3 01 "Active" 00 "Inactive" ;
VAL_ 2554396723 P3_BalSwCell4 01 "Active" 00 "Inactive" ;
VAL_ 2554462259 P3_BalSwCell5 01 "Active" 00 "Inactive" ;
VAL_ 2554462259 P3_BalSwCell6 01 "Active" 00 "Inactive" ;
VAL_ 2554462259 P3_BalSwCell7 01 "Active" 00 "Inactive" ;
VAL_ 2554462259 P3_BalSwCell8 01 "Active" 00 "Inactive" ;
VAL_ 2554527795 P3_BalSwCell9 01 "Active" 00 "Inactive" ;
VAL_ 2554527795 P3_BalSwCell10 01 "Active" 00 "Inactive" ;
VAL_ 2554527795 P3_BalSwCell11 01 "Active" 00 "Inactive" ;
VAL_ 2554527795 P3_BalSwCell12 01 "Active" 00 "Inactive" ;
VAL_ 2554593331 P3_BalSwCell13 01 "Active" 00 "Inactive" ;
VAL_ 2554593331 P3_BalSwCell14 01 "Active" 00 "Inactive" ;
VAL_ 2554593331 P3_BalSwCell15 01 "Active" 00 "Inactive" ;
VAL_ 2554593331 P3_BalSwCell16 01 "Active" 00 "Inactive" ;
VAL_ 2554658867 P3_BalSwCell17 01 "Active" 00 "Inactive" ;
VAL_ 2554658867 P3_BalSwCell18 01 "Active" 00 "Inactive" ;
VAL_ 2554658867 P3_BalSwCell19 01 "Active" 00 "Inactive" ;
VAL_ 2554658867 P3_BalSwCell20 01 "Active" 00 "Inactive" ;
VAL_ 2554724403 P3_BalSwCell21 01 "Active" 00 "Inactive" ;
VAL_ 2554724403 P3_BalSwCell22 01 "Active" 00 "Inactive" ;
VAL_ 2554724403 P3_BalSwCell23 01 "Active" 00 "Inactive" ;
VAL_ 2554724403 P3_BalSwCell24 01 "Active" 00 "Inactive" ;
VAL_ 2554789939 P3_BalSwCell25 01 "Active" 00 "Inactive" ;
VAL_ 2554789939 P3_BalSwCell26 01 "Active" 00 "Inactive" ;
VAL_ 2554789939 P3_BalSwCell27 01 "Active" 00 "Inactive" ;
VAL_ 2554789939 P3_BalSwCell28 01 "Active" 00 "Inactive" ;
VAL_ 2554855475 P3_BalSwCell29 01 "Active" 00 "Inactive" ;
VAL_ 2554855475 P3_BalSwCell30 01 "Active" 00 "Inactive" ;
VAL_ 2554855475 P3_BalSwCell31 01 "Active" 00 "Inactive" ;
VAL_ 2554855475 P3_BalSwCell32 01 "Active" 00 "Inactive" ;
VAL_ 2554921011 P3_BalSwCell33 01 "Active" 00 "Inactive" ;
VAL_ 2554921011 P3_BalSwCell34 01 "Active" 00 "Inactive" ;
VAL_ 2554921011 P3_BalSwCell35 01 "Active" 00 "Inactive" ;
VAL_ 2554921011 P3_BalSwCell36 01 "Active" 00 "Inactive" ;
VAL_ 2554986547 P3_BalSwCell37 01 "Active" 00 "Inactive" ;
VAL_ 2554986547 P3_BalSwCell38 01 "Active" 00 "Inactive" ;
VAL_ 2554986547 P3_BalSwCell39 01 "Active" 00 "Inactive" ;
VAL_ 2554986547 P3_BalSwCell40 01 "Active" 00 "Inactive" ;
VAL_ 2555052083 P3_BalSwCell41 01 "Active" 00 "Inactive" ;
VAL_ 2555052083 P3_BalSwCell42 01 "Active" 00 "Inactive" ;
VAL_ 2555052083 P3_BalSwCell43 01 "Active" 00 "Inactive" ;
VAL_ 2555052083 P3_BalSwCell44 01 "Active" 00 "Inactive" ;
VAL_ 2555117619 P3_BalSwCell45 01 "Active" 00 "Inactive" ;
VAL_ 2555117619 P3_BalSwCell46 01 "Active" 00 "Inactive" ;
VAL_ 2555117619 P3_BalSwCell47 01 "Active" 00 "Inactive" ;
VAL_ 2555117619 P3_BalSwCell48 01 "Active" 00 "Inactive" ;
VAL_ 2555183155 P3_BalSwCell49 01 "Active" 00 "Inactive" ;
VAL_ 2555183155 P3_BalSwCell50 01 "Active" 00 "Inactive" ;
VAL_ 2555183155 P3_BalSwCell51 01 "Active" 00 "Inactive" ;
VAL_ 2555183155 P3_BalSwCell52 01 "Active" 00 "Inactive" ;
VAL_ 2555248691 P3_BalSwCell53 01 "Active" 00 "Inactive" ;
VAL_ 2555248691 P3_BalSwCell54 01 "Active" 00 "Inactive" ;
VAL_ 2555248691 P3_BalSwCell55 01 "Active" 00 "Inactive" ;
VAL_ 2555248691 P3_BalSwCell56 01 "Active" 00 "Inactive" ;
VAL_ 2555314227 P3_BalSwCell57 01 "Active" 00 "Inactive" ;
VAL_ 2555314227 P3_BalSwCell58 01 "Active" 00 "Inactive" ;
VAL_ 2555314227 P3_BalSwCell59 01 "Active" 00 "Inactive" ;
VAL_ 2555314227 P3_BalSwCell60 01 "Active" 00 "Inactive" ;
VAL_ 2555379763 P3_BalSwCell61 01 "Active" 00 "Inactive" ;
VAL_ 2555379763 P3_BalSwCell62 01 "Active" 00 "Inactive" ;
VAL_ 2555379763 P3_BalSwCell63 01 "Active" 00 "Inactive" ;
VAL_ 2555379763 P3_BalSwCell64 01 "Active" 00 "Inactive" ;
VAL_ 2555445299 P3_BalSwCell65 01 "Active" 00 "Inactive" ;
VAL_ 2555445299 P3_BalSwCell66 01 "Active" 00 "Inactive" ;
VAL_ 2555445299 P3_BalSwCell67 01 "Active" 00 "Inactive" ;
VAL_ 2555445299 P3_BalSwCell68 01 "Active" 00 "Inactive" ;
VAL_ 2555510835 P3_BalSwCell69 01 "Active" 00 "Inactive" ;
VAL_ 2555510835 P3_BalSwCell70 01 "Active" 00 "Inactive" ;
VAL_ 2555510835 P3_BalSwCell71 01 "Active" 00 "Inactive" ;
VAL_ 2555510835 P3_BalSwCell72 01 "Active" 00 "Inactive" ;
VAL_ 2555576371 P3_BalSwCell73 01 "Active" 00 "Inactive" ;
VAL_ 2555576371 P3_BalSwCell74 01 "Active" 00 "Inactive" ;
VAL_ 2555576371 P3_BalSwCell75 01 "Active" 00 "Inactive" ;
VAL_ 2555576371 P3_BalSwCell76 01 "Active" 00 "Inactive" ;
VAL_ 2555641907 P3_BalSwCell77 01 "Active" 00 "Inactive" ;
VAL_ 2555641907 P3_BalSwCell78 01 "Active" 00 "Inactive" ;
VAL_ 2555641907 P3_BalSwCell79 01 "Active" 00 "Inactive" ;
VAL_ 2555641907 P3_BalSwCell80 01 "Active" 00 "Inactive" ;
VAL_ 2555707443 P3_BalSwCell81 01 "Active" 00 "Inactive" ;
VAL_ 2555707443 P3_BalSwCell82 01 "Active" 00 "Inactive" ;
VAL_ 2555707443 P3_BalSwCell83 01 "Active" 00 "Inactive" ;
VAL_ 2555707443 P3_BalSwCell84 01 "Active" 00 "Inactive" ;
VAL_ 2555772979 P3_BalSwCell85 01 "Active" 00 "Inactive" ;
VAL_ 2555772979 P3_BalSwCell86 01 "Active" 00 "Inactive" ;
VAL_ 2555772979 P3_BalSwCell87 01 "Active" 00 "Inactive" ;
VAL_ 2555772979 P3_BalSwCell88 01 "Active" 00 "Inactive" ;
VAL_ 2555838515 P3_BalSwCell89 01 "Active" 00 "Inactive" ;
VAL_ 2555838515 P3_BalSwCell90 01 "Active" 00 "Inactive" ;
VAL_ 2555838515 P3_BalSwCell91 01 "Active" 00 "Inactive" ;
VAL_ 2555838515 P3_BalSwCell92 01 "Active" 00 "Inactive" ;
VAL_ 2555904051 P3_BalSwCell93 01 "Active" 00 "Inactive" ;
VAL_ 2555904051 P3_BalSwCell94 01 "Active" 00 "Inactive" ;
VAL_ 2555904051 P3_BalSwCell95 01 "Active" 00 "Inactive" ;
VAL_ 2555904051 P3_BalSwCell96 01 "Active" 00 "Inactive" ;
VAL_ 2555969587 P3_BalSwCell97 01 "Active" 00 "Inactive" ;
VAL_ 2555969587 P3_BalSwCell98 01 "Active" 00 "Inactive" ;
VAL_ 2555969587 P3_BalSwCell99 01 "Active" 00 "Inactive" ;
VAL_ 2555969587 P3_BalSwCell100 01 "Active" 00 "Inactive" ;
VAL_ 2556035123 P3_BalSwCell101 01 "Active" 00 "Inactive" ;
VAL_ 2556035123 P3_BalSwCell102 01 "Active" 00 "Inactive" ;
VAL_ 2556035123 P3_BalSwCell103 01 "Active" 00 "Inactive" ;
VAL_ 2556035123 P3_BalSwCell104 01 "Active" 00 "Inactive" ;
VAL_ 2556100659 P3_BalSwCell105 01 "Active" 00 "Inactive" ;
VAL_ 2556100659 P3_BalSwCell106 01 "Active" 00 "Inactive" ;
VAL_ 2556100659 P3_BalSwCell107 01 "Active" 00 "Inactive" ;
VAL_ 2556100659 P3_BalSwCell108 01 "Active" 00 "Inactive" ;
VAL_ 2556166195 P3_BalSwCell109 01 "Active" 00 "Inactive" ;
VAL_ 2556166195 P3_BalSwCell110 01 "Active" 00 "Inactive" ;
VAL_ 2556166195 P3_BalSwCell111 01 "Active" 00 "Inactive" ;
VAL_ 2556166195 P3_BalSwCell112 01 "Active" 00 "Inactive" ;
VAL_ 2556231731 P3_BalSwCell113 01 "Active" 00 "Inactive" ;
VAL_ 2556231731 P3_BalSwCell114 01 "Active" 00 "Inactive" ;
VAL_ 2556231731 P3_BalSwCell115 01 "Active" 00 "Inactive" ;
VAL_ 2556231731 P3_BalSwCell116 01 "Active" 00 "Inactive" ;
VAL_ 2556297267 P3_BalSwCell117 01 "Active" 00 "Inactive" ;
VAL_ 2556297267 P3_BalSwCell118 01 "Active" 00 "Inactive" ;
VAL_ 2556297267 P3_BalSwCell119 01 "Active" 00 "Inactive" ;
VAL_ 2556297267 P3_BalSwCell120 01 "Active" 00 "Inactive" ;
VAL_ 2556362803 P3_BalSwCell121 01 "Active" 00 "Inactive" ;
VAL_ 2556362803 P3_BalSwCell122 01 "Active" 00 "Inactive" ;
VAL_ 2556362803 P3_BalSwCell123 01 "Active" 00 "Inactive" ;
VAL_ 2556362803 P3_BalSwCell124 01 "Active" 00 "Inactive" ;
VAL_ 2556428339 P3_BalSwCell125 01 "Active" 00 "Inactive" ;
VAL_ 2556428339 P3_BalSwCell126 01 "Active" 00 "Inactive" ;
VAL_ 2556428339 P3_BalSwCell127 01 "Active" 00 "Inactive" ;
VAL_ 2556428339 P3_BalSwCell128 01 "Active" 00 "Inactive" ;
VAL_ 2556493875 P3_BalSwCell129 01 "Active" 00 "Inactive" ;
VAL_ 2556493875 P3_BalSwCell130 01 "Active" 00 "Inactive" ;
VAL_ 2556493875 P3_BalSwCell131 01 "Active" 00 "Inactive" ;
VAL_ 2556493875 P3_BalSwCell132 01 "Active" 00 "Inactive" ;
VAL_ 2556559411 P3_BalSwCell133 01 "Active" 00 "Inactive" ;
VAL_ 2556559411 P3_BalSwCell134 01 "Active" 00 "Inactive" ;
VAL_ 2556559411 P3_BalSwCell135 01 "Active" 00 "Inactive" ;
VAL_ 2556559411 P3_BalSwCell136 01 "Active" 00 "Inactive" ;
VAL_ 2556624947 P3_BalSwCell137 01 "Active" 00 "Inactive" ;
VAL_ 2556624947 P3_BalSwCell138 01 "Active" 00 "Inactive" ;
VAL_ 2556624947 P3_BalSwCell139 01 "Active" 00 "Inactive" ;
VAL_ 2556624947 P3_BalSwCell140 01 "Active" 00 "Inactive" ;
VAL_ 2556690483 P3_BalSwCell141 01 "Active" 00 "Inactive" ;
VAL_ 2556690483 P3_BalSwCell142 01 "Active" 00 "Inactive" ;
VAL_ 2556690483 P3_BalSwCell143 01 "Active" 00 "Inactive" ;
VAL_ 2556690483 P3_BalSwCell144 01 "Active" 00 "Inactive" ;
VAL_ 2556756019 P3_BalSwCell145 01 "Active" 00 "Inactive" ;
VAL_ 2556756019 P3_BalSwCell146 01 "Active" 00 "Inactive" ;
VAL_ 2556756019 P3_BalSwCell147 01 "Active" 00 "Inactive" ;
VAL_ 2556756019 P3_BalSwCell148 01 "Active" 00 "Inactive" ;
VAL_ 2556821555 P3_BalSwCell149 01 "Active" 00 "Inactive" ;
VAL_ 2556821555 P3_BalSwCell150 01 "Active" 00 "Inactive" ;
VAL_ 2556821555 P3_BalSwCell151 01 "Active" 00 "Inactive" ;
VAL_ 2556821555 P3_BalSwCell152 01 "Active" 00 "Inactive" ;
VAL_ 2556887091 P3_BalSwCell153 01 "Active" 00 "Inactive" ;
VAL_ 2556887091 P3_BalSwCell154 01 "Active" 00 "Inactive" ;
VAL_ 2556887091 P3_BalSwCell155 01 "Active" 00 "Inactive" ;
VAL_ 2556887091 P3_BalSwCell156 01 "Active" 00 "Inactive" ;
VAL_ 2556952627 P3_BalSwCell157 01 "Active" 00 "Inactive" ;
VAL_ 2556952627 P3_BalSwCell158 01 "Active" 00 "Inactive" ;
VAL_ 2556952627 P3_BalSwCell159 01 "Active" 00 "Inactive" ;
VAL_ 2556952627 P3_BalSwCell160 01 "Active" 00 "Inactive" ;
VAL_ 2557018163 P3_BalSwCell161 01 "Active" 00 "Inactive" ;
VAL_ 2557018163 P3_BalSwCell162 01 "Active" 00 "Inactive" ;
VAL_ 2557018163 P3_BalSwCell163 01 "Active" 00 "Inactive" ;
VAL_ 2557018163 P3_BalSwCell164 01 "Active" 00 "Inactive" ;
VAL_ 2557083699 P3_BalSwCell165 01 "Active" 00 "Inactive" ;
VAL_ 2557083699 P3_BalSwCell166 01 "Active" 00 "Inactive" ;
VAL_ 2557083699 P3_BalSwCell167 01 "Active" 00 "Inactive" ;
VAL_ 2557083699 P3_BalSwCell168 01 "Active" 00 "Inactive" ;
VAL_ 2557149235 P3_BalSwCell169 01 "Active" 00 "Inactive" ;
VAL_ 2557149235 P3_BalSwCell170 01 "Active" 00 "Inactive" ;
VAL_ 2557149235 P3_BalSwCell171 01 "Active" 00 "Inactive" ;
VAL_ 2557149235 P3_BalSwCell172 01 "Active" 00 "Inactive" ;
VAL_ 2557214771 P3_BalSwCell173 01 "Active" 00 "Inactive" ;
VAL_ 2557214771 P3_BalSwCell174 01 "Active" 00 "Inactive" ;
VAL_ 2557214771 P3_BalSwCell175 01 "Active" 00 "Inactive" ;
VAL_ 2557214771 P3_BalSwCell176 01 "Active" 00 "Inactive" ;
VAL_ 2557280307 P3_BalSwCell177 01 "Active" 00 "Inactive" ;
VAL_ 2557280307 P3_BalSwCell178 01 "Active" 00 "Inactive" ;
VAL_ 2557280307 P3_BalSwCell179 01 "Active" 00 "Inactive" ;
VAL_ 2557280307 P3_BalSwCell180 01 "Active" 00 "Inactive" ;
VAL_ 2557345843 P3_BalSwCell181 01 "Active" 00 "Inactive" ;
VAL_ 2557345843 P3_BalSwCell182 01 "Active" 00 "Inactive" ;
VAL_ 2557345843 P3_BalSwCell183 01 "Active" 00 "Inactive" ;
VAL_ 2557345843 P3_BalSwCell184 01 "Active" 00 "Inactive" ;
VAL_ 2557411379 P3_BalSwCell185 01 "Active" 00 "Inactive" ;
VAL_ 2557411379 P3_BalSwCell186 01 "Active" 00 "Inactive" ;
VAL_ 2557411379 P3_BalSwCell187 01 "Active" 00 "Inactive" ;
VAL_ 2557411379 P3_BalSwCell188 01 "Active" 00 "Inactive" ;
VAL_ 2557476915 P3_BalSwCell189 01 "Active" 00 "Inactive" ;
VAL_ 2557476915 P3_BalSwCell190 01 "Active" 00 "Inactive" ;
VAL_ 2557476915 P3_BalSwCell191 01 "Active" 00 "Inactive" ;
VAL_ 2557476915 P3_BalSwCell192 01 "Active" 00 "Inactive" ;
VAL_ 2550399044 P4_BMSKL15ON 01 "On" 00 "Off" ;
VAL_ 2550530116 P4_PackDschrgPwrStat 02 "鎸佺画鏀剧數鍔熺巼" 01 "30s鏀剧數鍔熺巼" 00 "10s鏀剧數鍔熺巼" ;
VAL_ 2550530116 P4_PackChrgPwrStat 02 "鎸佺画鍏呯數鍔熺巼" 01 "30s鍏呯數鍔熺巼" 00 "10s鍏呯數鍔熺巼" ;
VAL_ 2550595652 P4_ChrgrCplrStat 01 "Connected" 00 "Disconnected" ;
VAL_ 2550595652 P4_HVBattChrgSysStatus 04 "Aborted" 03 "Complete" 02 "Active" 01 "Initialization" 00 "Default" ;
VAL_ 2550857796 P4_CellOverVoltage 03 "Level 3" 02 "Level 2" 01 "Level 1" 00 "No Fault" ;
VAL_ 2550857796 P4_CellUnderVoltage 03 "Level 3" 02 "Level 2" 01 "Level 1" 00 "No Fault" ;
VAL_ 2550857796 P4_CellVoltageDiffHi 01 "Fault" 00 "No Fault" ;
VAL_ 2550857796 P4_PackOverVoltage 03 "Level 3" 02 "Level 2" 01 "Level 1" 00 "No Fault" ;
VAL_ 2550857796 P4_PackUnderVoltage 03 "Level 3" 02 "Level 2" 01 "Level 1" 00 "No Fault" ;
VAL_ 2550857796 P4_CellOverTemp 03 "Level 3" 02 "Level 2" 01 "Level 1" 00 "No Fault" ;
VAL_ 2550857796 P4_CellTempLow 01 "Fault" 00 "No Fault" ;
VAL_ 2550857796 P4_CellTempDiffHi 01 "Fault" 00 "No Fault" ;
VAL_ 2550857796 P4_PackDschrgCrntHi 03 "Level 3" 02 "Level 2" 01 "Level 1" 00 "No Fault" ;
VAL_ 2550857796 P4_PackChrgCrntHi 03 "Level 3" 02 "Level 2" 01 "Level 1" 00 "No Fault" ;
VAL_ 2550857796 P4_PackCrnSnsr1OffsetHi 01 "Fault" 00 "No Fault" ;
VAL_ 2550857796 P4_HVIsolFlt 03 "Level 3" 02 "Level 2" 01 "Level 1" 00 "No Fault" ;
VAL_ 2550857796 P4_HVILFlt 01 "Fault" 00 "No Fault" ;
VAL_ 2550857796 P4_ThrmlRunaway 01 "Fault" 00 "No Fault" ;
VAL_ 2550857796 P4_CellVoltInvalid 01 "Fault" 00 "No Fault" ;
VAL_ 2550857796 P4_CellTempInvalid 01 "Fault" 00 "No Fault" ;
VAL_ 2550857796 P4_DaisyChainComFlt 01 "Fault" 00 "No Fault" ;
VAL_ 2550857796 P4_PackVoltRatFlt 01 "Fault" 00 "No Fault" ;
VAL_ 2550857796 P4_CrntSnsr1Invalid 01 "Fault" 00 "No Fault" ;
VAL_ 2550857796 P4_CrntSnsr1OOR 01 "Fault" 00 "No Fault" ;
VAL_ 2550857796 P4_CrntSnsr2Invalid 01 "Fault" 00 "No Fault" ;
VAL_ 2550857796 P4_CrntSnsr2OOR 01 "Fault" 00 "No Fault" ;
VAL_ 2550857796 P4_PackCrnSnsr2OffsetHi 01 "Fault" 00 "No Fault" ;
VAL_ 2550857796 P4_OutofEnergy 01 "Fault" 00 "No Fault" ;
VAL_ 2550857796 P4_IsolDetCircErr 01 "Fault" 00 "No Fault" ;
VAL_ 2550857796 P4_HVILCircShortToGND 01 "Fault" 00 "No Fault" ;
VAL_ 2550857796 P4_HVILCircShortToPwr 01 "Fault" 00 "No Fault" ;
VAL_ 2550923332 P4_MainPosCntctrStkClsd 01 "Fault" 00 "No Fault" ;
VAL_ 2550923332 P4_MainPosCntctrStkOpn 01 "Fault" 00 "No Fault" ;
VAL_ 2550923332 P4_MainNegCntctr1StkClsd 01 "Fault" 00 "No Fault" ;
VAL_ 2550923332 P4_MainNegCntctr1StkOpn 01 "Fault" 00 "No Fault" ;
VAL_ 2550923332 P4_MainNegCntctr2StkClsd 01 "Fault" 00 "No Fault" ;
VAL_ 2550923332 P4_MainNegCntctr2StkOpn 01 "Fault" 00 "No Fault" ;
VAL_ 2550923332 P4_PrechargTmOut 01 "Fault" 00 "No Fault" ;
VAL_ 2550923332 P4_PrechrgCrntHi 01 "Fault" 00 "No Fault" ;
VAL_ 2550923332 P4_ChrgCplrPosTempHi 01 "Fault" 00 "No Fault" ;
VAL_ 2550923332 P4_ChrgCplrNegTempHi 01 "Fault" 00 "No Fault" ;
VAL_ 2550923332 P4_BMSPwrSuplVlt1Hi 01 "Fault" 00 "No Fault" ;
VAL_ 2550923332 P4_BMSPwrSuplVlt1Lo 01 "Fault" 00 "No Fault" ;
VAL_ 2550923332 P4_BMSPwrSuplVlt2Hi 01 "Fault" 00 "No Fault" ;
VAL_ 2550923332 P4_BMSPwrSuplVlt2Lo 01 "Fault" 00 "No Fault" ;
VAL_ 2550923332 P4_CntctrCirPwrSuplVltLo 01 "Fault" 00 "No Fault" ;
VAL_ 2550923332 P4_CntctrCirPwrSuplVltHi 01 "Fault" 00 "No Fault" ;
VAL_ 2550923332 P4_CAN1BusOff 01 "Fault" 00 "No Fault" ;
VAL_ 2550923332 P4_CAN1BusTmOut 01 "Fault" 00 "No Fault" ;
VAL_ 2550923332 P4_CAN2BusOff 01 "Fault" 00 "No Fault" ;
VAL_ 2550923332 P4_CAN2BusTmOut 01 "Fault" 00 "No Fault" ;
VAL_ 2550923332 P4_CellBalCircTempHi 01 "Fault" 00 "No Fault" ;
VAL_ 2550923332 P4_ClntInTempHi 01 "Fault" 00 "No Fault" ;
VAL_ 2550923332 P4_ClntOutTempHi 01 "Fault" 00 "No Fault" ;
VAL_ 2550923332 P4_CellExtrmUdrVolt 01 "Fault" 00 "No Fault" ;
VAL_ 2550923332 P4_CellExtrmOvrVolt 01 "Fault" 00 "No Fault" ;
VAL_ 2550923332 P4_Branch1DischrgCrntHi  01 "Fault" 00 "No Fault" ;
VAL_ 2550923332 P4_Branch2DischrgCrntHi  01 "Fault" 00 "No Fault" ;
VAL_ 2550923332 P4_Branch1ChrgCrntHi  01 "Fault" 00 "No Fault" ;
VAL_ 2550923332 P4_Branch2ChrgCrntHi  01 "Fault" 00 "No Fault" ;
VAL_ 2550923332 P4_InitFailed 01 "Fault" 00 "No Fault" ;
VAL_ 2554396740 P4_BalSwCell1 01 "Active" 00 "Inactive" ;
VAL_ 2554396740 P4_BalSwCell2 01 "Active" 00 "Inactive" ;
VAL_ 2554396740 P4_BalSwCell3 01 "Active" 00 "Inactive" ;
VAL_ 2554396740 P4_BalSwCell4 01 "Active" 00 "Inactive" ;
VAL_ 2554462276 P4_BalSwCell5 01 "Active" 00 "Inactive" ;
VAL_ 2554462276 P4_BalSwCell6 01 "Active" 00 "Inactive" ;
VAL_ 2554462276 P4_BalSwCell7 01 "Active" 00 "Inactive" ;
VAL_ 2554462276 P4_BalSwCell8 01 "Active" 00 "Inactive" ;
VAL_ 2554527812 P4_BalSwCell9 01 "Active" 00 "Inactive" ;
VAL_ 2554527812 P4_BalSwCell10 01 "Active" 00 "Inactive" ;
VAL_ 2554527812 P4_BalSwCell11 01 "Active" 00 "Inactive" ;
VAL_ 2554527812 P4_BalSwCell12 01 "Active" 00 "Inactive" ;
VAL_ 2554593348 P4_BalSwCell13 01 "Active" 00 "Inactive" ;
VAL_ 2554593348 P4_BalSwCell14 01 "Active" 00 "Inactive" ;
VAL_ 2554593348 P4_BalSwCell15 01 "Active" 00 "Inactive" ;
VAL_ 2554593348 P4_BalSwCell16 01 "Active" 00 "Inactive" ;
VAL_ 2554658884 P4_BalSwCell17 01 "Active" 00 "Inactive" ;
VAL_ 2554658884 P4_BalSwCell18 01 "Active" 00 "Inactive" ;
VAL_ 2554658884 P4_BalSwCell19 01 "Active" 00 "Inactive" ;
VAL_ 2554658884 P4_BalSwCell20 01 "Active" 00 "Inactive" ;
VAL_ 2554724420 P4_BalSwCell21 01 "Active" 00 "Inactive" ;
VAL_ 2554724420 P4_BalSwCell22 01 "Active" 00 "Inactive" ;
VAL_ 2554724420 P4_BalSwCell23 01 "Active" 00 "Inactive" ;
VAL_ 2554724420 P4_BalSwCell24 01 "Active" 00 "Inactive" ;
VAL_ 2554789956 P4_BalSwCell25 01 "Active" 00 "Inactive" ;
VAL_ 2554789956 P4_BalSwCell26 01 "Active" 00 "Inactive" ;
VAL_ 2554789956 P4_BalSwCell27 01 "Active" 00 "Inactive" ;
VAL_ 2554789956 P4_BalSwCell28 01 "Active" 00 "Inactive" ;
VAL_ 2554855492 P4_BalSwCell29 01 "Active" 00 "Inactive" ;
VAL_ 2554855492 P4_BalSwCell30 01 "Active" 00 "Inactive" ;
VAL_ 2554855492 P4_BalSwCell31 01 "Active" 00 "Inactive" ;
VAL_ 2554855492 P4_BalSwCell32 01 "Active" 00 "Inactive" ;
VAL_ 2554921028 P4_BalSwCell33 01 "Active" 00 "Inactive" ;
VAL_ 2554921028 P4_BalSwCell34 01 "Active" 00 "Inactive" ;
VAL_ 2554921028 P4_BalSwCell35 01 "Active" 00 "Inactive" ;
VAL_ 2554921028 P4_BalSwCell36 01 "Active" 00 "Inactive" ;
VAL_ 2554986564 P4_BalSwCell37 01 "Active" 00 "Inactive" ;
VAL_ 2554986564 P4_BalSwCell38 01 "Active" 00 "Inactive" ;
VAL_ 2554986564 P4_BalSwCell39 01 "Active" 00 "Inactive" ;
VAL_ 2554986564 P4_BalSwCell40 01 "Active" 00 "Inactive" ;
VAL_ 2555052100 P4_BalSwCell41 01 "Active" 00 "Inactive" ;
VAL_ 2555052100 P4_BalSwCell42 01 "Active" 00 "Inactive" ;
VAL_ 2555052100 P4_BalSwCell43 01 "Active" 00 "Inactive" ;
VAL_ 2555052100 P4_BalSwCell44 01 "Active" 00 "Inactive" ;
VAL_ 2555117636 P4_BalSwCell45 01 "Active" 00 "Inactive" ;
VAL_ 2555117636 P4_BalSwCell46 01 "Active" 00 "Inactive" ;
VAL_ 2555117636 P4_BalSwCell47 01 "Active" 00 "Inactive" ;
VAL_ 2555117636 P4_BalSwCell48 01 "Active" 00 "Inactive" ;
VAL_ 2555183172 P4_BalSwCell49 01 "Active" 00 "Inactive" ;
VAL_ 2555183172 P4_BalSwCell50 01 "Active" 00 "Inactive" ;
VAL_ 2555183172 P4_BalSwCell51 01 "Active" 00 "Inactive" ;
VAL_ 2555183172 P4_BalSwCell52 01 "Active" 00 "Inactive" ;
VAL_ 2555248708 P4_BalSwCell53 01 "Active" 00 "Inactive" ;
VAL_ 2555248708 P4_BalSwCell54 01 "Active" 00 "Inactive" ;
VAL_ 2555248708 P4_BalSwCell55 01 "Active" 00 "Inactive" ;
VAL_ 2555248708 P4_BalSwCell56 01 "Active" 00 "Inactive" ;
VAL_ 2555314244 P4_BalSwCell57 01 "Active" 00 "Inactive" ;
VAL_ 2555314244 P4_BalSwCell58 01 "Active" 00 "Inactive" ;
VAL_ 2555314244 P4_BalSwCell59 01 "Active" 00 "Inactive" ;
VAL_ 2555314244 P4_BalSwCell60 01 "Active" 00 "Inactive" ;
VAL_ 2555379780 P4_BalSwCell61 01 "Active" 00 "Inactive" ;
VAL_ 2555379780 P4_BalSwCell62 01 "Active" 00 "Inactive" ;
VAL_ 2555379780 P4_BalSwCell63 01 "Active" 00 "Inactive" ;
VAL_ 2555379780 P4_BalSwCell64 01 "Active" 00 "Inactive" ;
VAL_ 2555445316 P4_BalSwCell65 01 "Active" 00 "Inactive" ;
VAL_ 2555445316 P4_BalSwCell66 01 "Active" 00 "Inactive" ;
VAL_ 2555445316 P4_BalSwCell67 01 "Active" 00 "Inactive" ;
VAL_ 2555445316 P4_BalSwCell68 01 "Active" 00 "Inactive" ;
VAL_ 2555510852 P4_BalSwCell69 01 "Active" 00 "Inactive" ;
VAL_ 2555510852 P4_BalSwCell70 01 "Active" 00 "Inactive" ;
VAL_ 2555510852 P4_BalSwCell71 01 "Active" 00 "Inactive" ;
VAL_ 2555510852 P4_BalSwCell72 01 "Active" 00 "Inactive" ;
VAL_ 2555576388 P4_BalSwCell73 01 "Active" 00 "Inactive" ;
VAL_ 2555576388 P4_BalSwCell74 01 "Active" 00 "Inactive" ;
VAL_ 2555576388 P4_BalSwCell75 01 "Active" 00 "Inactive" ;
VAL_ 2555576388 P4_BalSwCell76 01 "Active" 00 "Inactive" ;
VAL_ 2555641924 P4_BalSwCell77 01 "Active" 00 "Inactive" ;
VAL_ 2555641924 P4_BalSwCell78 01 "Active" 00 "Inactive" ;
VAL_ 2555641924 P4_BalSwCell79 01 "Active" 00 "Inactive" ;
VAL_ 2555641924 P4_BalSwCell80 01 "Active" 00 "Inactive" ;
VAL_ 2555707460 P4_BalSwCell81 01 "Active" 00 "Inactive" ;
VAL_ 2555707460 P4_BalSwCell82 01 "Active" 00 "Inactive" ;
VAL_ 2555707460 P4_BalSwCell83 01 "Active" 00 "Inactive" ;
VAL_ 2555707460 P4_BalSwCell84 01 "Active" 00 "Inactive" ;
VAL_ 2555772996 P4_BalSwCell85 01 "Active" 00 "Inactive" ;
VAL_ 2555772996 P4_BalSwCell86 01 "Active" 00 "Inactive" ;
VAL_ 2555772996 P4_BalSwCell87 01 "Active" 00 "Inactive" ;
VAL_ 2555772996 P4_BalSwCell88 01 "Active" 00 "Inactive" ;
VAL_ 2555838532 P4_BalSwCell89 01 "Active" 00 "Inactive" ;
VAL_ 2555838532 P4_BalSwCell90 01 "Active" 00 "Inactive" ;
VAL_ 2555838532 P4_BalSwCell91 01 "Active" 00 "Inactive" ;
VAL_ 2555838532 P4_BalSwCell92 01 "Active" 00 "Inactive" ;
VAL_ 2555904068 P4_BalSwCell93 01 "Active" 00 "Inactive" ;
VAL_ 2555904068 P4_BalSwCell94 01 "Active" 00 "Inactive" ;
VAL_ 2555904068 P4_BalSwCell95 01 "Active" 00 "Inactive" ;
VAL_ 2555904068 P4_BalSwCell96 01 "Active" 00 "Inactive" ;
VAL_ 2555969604 P4_BalSwCell97 01 "Active" 00 "Inactive" ;
VAL_ 2555969604 P4_BalSwCell98 01 "Active" 00 "Inactive" ;
VAL_ 2555969604 P4_BalSwCell99 01 "Active" 00 "Inactive" ;
VAL_ 2555969604 P4_BalSwCell100 01 "Active" 00 "Inactive" ;
VAL_ 2556035140 P4_BalSwCell101 01 "Active" 00 "Inactive" ;
VAL_ 2556035140 P4_BalSwCell102 01 "Active" 00 "Inactive" ;
VAL_ 2556035140 P4_BalSwCell103 01 "Active" 00 "Inactive" ;
VAL_ 2556035140 P4_BalSwCell104 01 "Active" 00 "Inactive" ;
VAL_ 2556100676 P4_BalSwCell105 01 "Active" 00 "Inactive" ;
VAL_ 2556100676 P4_BalSwCell106 01 "Active" 00 "Inactive" ;
VAL_ 2556100676 P4_BalSwCell107 01 "Active" 00 "Inactive" ;
VAL_ 2556100676 P4_BalSwCell108 01 "Active" 00 "Inactive" ;
VAL_ 2556166212 P4_BalSwCell109 01 "Active" 00 "Inactive" ;
VAL_ 2556166212 P4_BalSwCell110 01 "Active" 00 "Inactive" ;
VAL_ 2556166212 P4_BalSwCell111 01 "Active" 00 "Inactive" ;
VAL_ 2556166212 P4_BalSwCell112 01 "Active" 00 "Inactive" ;
VAL_ 2556231748 P4_BalSwCell113 01 "Active" 00 "Inactive" ;
VAL_ 2556231748 P4_BalSwCell114 01 "Active" 00 "Inactive" ;
VAL_ 2556231748 P4_BalSwCell115 01 "Active" 00 "Inactive" ;
VAL_ 2556231748 P4_BalSwCell116 01 "Active" 00 "Inactive" ;
VAL_ 2556297284 P4_BalSwCell117 01 "Active" 00 "Inactive" ;
VAL_ 2556297284 P4_BalSwCell118 01 "Active" 00 "Inactive" ;
VAL_ 2556297284 P4_BalSwCell119 01 "Active" 00 "Inactive" ;
VAL_ 2556297284 P4_BalSwCell120 01 "Active" 00 "Inactive" ;
VAL_ 2556362820 P4_BalSwCell121 01 "Active" 00 "Inactive" ;
VAL_ 2556362820 P4_BalSwCell122 01 "Active" 00 "Inactive" ;
VAL_ 2556362820 P4_BalSwCell123 01 "Active" 00 "Inactive" ;
VAL_ 2556362820 P4_BalSwCell124 01 "Active" 00 "Inactive" ;
VAL_ 2556428356 P4_BalSwCell125 01 "Active" 00 "Inactive" ;
VAL_ 2556428356 P4_BalSwCell126 01 "Active" 00 "Inactive" ;
VAL_ 2556428356 P4_BalSwCell127 01 "Active" 00 "Inactive" ;
VAL_ 2556428356 P4_BalSwCell128 01 "Active" 00 "Inactive" ;
VAL_ 2556493892 P4_BalSwCell129 01 "Active" 00 "Inactive" ;
VAL_ 2556493892 P4_BalSwCell130 01 "Active" 00 "Inactive" ;
VAL_ 2556493892 P4_BalSwCell131 01 "Active" 00 "Inactive" ;
VAL_ 2556493892 P4_BalSwCell132 01 "Active" 00 "Inactive" ;
VAL_ 2556559428 P4_BalSwCell133 01 "Active" 00 "Inactive" ;
VAL_ 2556559428 P4_BalSwCell134 01 "Active" 00 "Inactive" ;
VAL_ 2556559428 P4_BalSwCell135 01 "Active" 00 "Inactive" ;
VAL_ 2556559428 P4_BalSwCell136 01 "Active" 00 "Inactive" ;
VAL_ 2556624964 P4_BalSwCell137 01 "Active" 00 "Inactive" ;
VAL_ 2556624964 P4_BalSwCell138 01 "Active" 00 "Inactive" ;
VAL_ 2556624964 P4_BalSwCell139 01 "Active" 00 "Inactive" ;
VAL_ 2556624964 P4_BalSwCell140 01 "Active" 00 "Inactive" ;
VAL_ 2556690500 P4_BalSwCell141 01 "Active" 00 "Inactive" ;
VAL_ 2556690500 P4_BalSwCell142 01 "Active" 00 "Inactive" ;
VAL_ 2556690500 P4_BalSwCell143 01 "Active" 00 "Inactive" ;
VAL_ 2556690500 P4_BalSwCell144 01 "Active" 00 "Inactive" ;
VAL_ 2556756036 P4_BalSwCell145 01 "Active" 00 "Inactive" ;
VAL_ 2556756036 P4_BalSwCell146 01 "Active" 00 "Inactive" ;
VAL_ 2556756036 P4_BalSwCell147 01 "Active" 00 "Inactive" ;
VAL_ 2556756036 P4_BalSwCell148 01 "Active" 00 "Inactive" ;
VAL_ 2556821572 P4_BalSwCell149 01 "Active" 00 "Inactive" ;
VAL_ 2556821572 P4_BalSwCell150 01 "Active" 00 "Inactive" ;
VAL_ 2556821572 P4_BalSwCell151 01 "Active" 00 "Inactive" ;
VAL_ 2556821572 P4_BalSwCell152 01 "Active" 00 "Inactive" ;
VAL_ 2556887108 P4_BalSwCell153 01 "Active" 00 "Inactive" ;
VAL_ 2556887108 P4_BalSwCell154 01 "Active" 00 "Inactive" ;
VAL_ 2556887108 P4_BalSwCell155 01 "Active" 00 "Inactive" ;
VAL_ 2556887108 P4_BalSwCell156 01 "Active" 00 "Inactive" ;
VAL_ 2556952644 P4_BalSwCell157 01 "Active" 00 "Inactive" ;
VAL_ 2556952644 P4_BalSwCell158 01 "Active" 00 "Inactive" ;
VAL_ 2556952644 P4_BalSwCell159 01 "Active" 00 "Inactive" ;
VAL_ 2556952644 P4_BalSwCell160 01 "Active" 00 "Inactive" ;
VAL_ 2557018180 P4_BalSwCell161 01 "Active" 00 "Inactive" ;
VAL_ 2557018180 P4_BalSwCell162 01 "Active" 00 "Inactive" ;
VAL_ 2557018180 P4_BalSwCell163 01 "Active" 00 "Inactive" ;
VAL_ 2557018180 P4_BalSwCell164 01 "Active" 00 "Inactive" ;
VAL_ 2557083716 P4_BalSwCell165 01 "Active" 00 "Inactive" ;
VAL_ 2557083716 P4_BalSwCell166 01 "Active" 00 "Inactive" ;
VAL_ 2557083716 P4_BalSwCell167 01 "Active" 00 "Inactive" ;
VAL_ 2557083716 P4_BalSwCell168 01 "Active" 00 "Inactive" ;
VAL_ 2557149252 P4_BalSwCell169 01 "Active" 00 "Inactive" ;
VAL_ 2557149252 P4_BalSwCell170 01 "Active" 00 "Inactive" ;
VAL_ 2557149252 P4_BalSwCell171 01 "Active" 00 "Inactive" ;
VAL_ 2557149252 P4_BalSwCell172 01 "Active" 00 "Inactive" ;
VAL_ 2557214788 P4_BalSwCell173 01 "Active" 00 "Inactive" ;
VAL_ 2557214788 P4_BalSwCell174 01 "Active" 00 "Inactive" ;
VAL_ 2557214788 P4_BalSwCell175 01 "Active" 00 "Inactive" ;
VAL_ 2557214788 P4_BalSwCell176 01 "Active" 00 "Inactive" ;
VAL_ 2557280324 P4_BalSwCell177 01 "Active" 00 "Inactive" ;
VAL_ 2557280324 P4_BalSwCell178 01 "Active" 00 "Inactive" ;
VAL_ 2557280324 P4_BalSwCell179 01 "Active" 00 "Inactive" ;
VAL_ 2557280324 P4_BalSwCell180 01 "Active" 00 "Inactive" ;
VAL_ 2557345860 P4_BalSwCell181 01 "Active" 00 "Inactive" ;
VAL_ 2557345860 P4_BalSwCell182 01 "Active" 00 "Inactive" ;
VAL_ 2557345860 P4_BalSwCell183 01 "Active" 00 "Inactive" ;
VAL_ 2557345860 P4_BalSwCell184 01 "Active" 00 "Inactive" ;
VAL_ 2557411396 P4_BalSwCell185 01 "Active" 00 "Inactive" ;
VAL_ 2557411396 P4_BalSwCell186 01 "Active" 00 "Inactive" ;
VAL_ 2557411396 P4_BalSwCell187 01 "Active" 00 "Inactive" ;
VAL_ 2557411396 P4_BalSwCell188 01 "Active" 00 "Inactive" ;
VAL_ 2557476932 P4_BalSwCell189 01 "Active" 00 "Inactive" ;
VAL_ 2557476932 P4_BalSwCell190 01 "Active" 00 "Inactive" ;
VAL_ 2557476932 P4_BalSwCell191 01 "Active" 00 "Inactive" ;
VAL_ 2557476932 P4_BalSwCell192 01 "Active" 00 "Inactive" ;
VAL_ 2550399061 P5_BMSKL15ON 01 "On" 00 "Off" ;
